VERSION "dbc-export 1 2026.26.6.5"

NS_ :

BS_:

BU_: APP BMS CC CMP CMPD CP DAS DI DIF DIR EPBL EPBR EVSE FC GTW HCML HCMR HVP ICR PCS PCS2 PM PMF PMR PTC SCCM SCM SCS SDCR TAS UMC V2G VC VCBATT VCBATT0 VCBATT1 VCBATT2 VCFRONT VCFRONT1 VCFRONT2 VCLEFT VCRIGHT VCSEAT2L VCSEAT2R VCSEC

BO_ 1000 EPBR_alertMatrix: 8 EPBR
 SG_ EPBR_matrixIndex M : 0|4@1+ (1,0) [0|15] "" Vector__XXX
 SG_ EPBR_a001_WatchdogReset m0 : 4|1@1+ (1,0) [0|1] "" Vector__XXX
 SG_ EPBR_a002_PowerLossReset m0 : 5|1@1+ (1,0) [0|1] "" Vector__XXX
 SG_ EPBR_a003_SWAssertion m0 : 6|1@1+ (1,0) [0|1] "" Vector__XXX
 SG_ EPBR_a005_CANTXError m0 : 8|1@1+ (1,0) [0|1] "" Vector__XXX
 SG_ EPBR_a006_CANTX_cyclicError m0 : 9|1@1+ (1,0) [0|1] "" Vector__XXX
 SG_ EPBR_a012_CPUReset m0 : 15|1@1+ (1,0) [0|1] "" Vector__XXX
 SG_ EPBR_a013_AlertManagerFault m0 : 16|1@1+ (1,0) [0|1] "" Vector__XXX
 SG_ EPBR_a015_NVMMError m0 : 18|1@1+ (1,0) [0|1] "" Vector__XXX
 SG_ EPBR_a016_NVMMRecordError m0 : 19|1@1+ (1,0) [0|1] "" Vector__XXX
 SG_ EPBR_a021_TaskSchedulerError m0 : 24|1@1+ (1,0) [0|1] "" Vector__XXX
 SG_ EPBR_a022_TaskInitError m0 : 25|1@1+ (1,0) [0|1] "" Vector__XXX
 SG_ EPBR_a029_CoreDump m0 : 32|1@1+ (1,0) [0|1] "" Vector__XXX
 SG_ EPBR_a030_ECULogUploadRequest m0 : 33|1@1+ (1,0) [0|1] "" Vector__XXX
 SG_ EPBR_a031_UDSActive m0 : 34|1@1+ (1,0) [0|1] "" Vector__XXX
 SG_ EPBR_a041_HighCPULoad m0 : 44|1@1+ (1,0) [0|1] "" Vector__XXX
 SG_ EPBR_a042_HighStackUsage m0 : 45|1@1+ (1,0) [0|1] "" Vector__XXX
 SG_ EPBR_a043_Task1msError m0 : 46|1@1+ (1,0) [0|1] "" Vector__XXX
 SG_ EPBR_a044_Task10msError m0 : 47|1@1+ (1,0) [0|1] "" Vector__XXX
 SG_ EPBR_a045_Task100msError m0 : 48|1@1+ (1,0) [0|1] "" Vector__XXX
 SG_ EPBR_a046_Task1000msError m0 : 49|1@1+ (1,0) [0|1] "" Vector__XXX
 SG_ EPBR_a057_HVP_MIA m0 : 60|1@1+ (1,0) [0|1] "" Vector__XXX
 SG_ EPBR_a058_inputRHighSyncDebug m0 : 61|1@1+ (1,0) [0|1] "" Vector__XXX
 SG_ EPBR_a059_inputResistanceHigh m0 : 62|1@1+ (1,0) [0|1] "" Vector__XXX
 SG_ EPBR_a060_engineeringBuild m0 : 63|1@1+ (1,0) [0|1] "" Vector__XXX
 SG_ EPBR_a061_XCPConnected m1 : 4|1@1+ (1,0) [0|1] "" Vector__XXX
 SG_ EPBR_a062_XCPWasConnected m1 : 5|1@1+ (1,0) [0|1] "" Vector__XXX
 SG_ EPBR_a063_SwitchFault m1 : 6|1@1+ (1,0) [0|1] "" Vector__XXX
 SG_ EPBR_a064_busSleepReqTimeout m1 : 7|1@1+ (1,0) [0|1] "" Vector__XXX
 SG_ EPBR_a081_APP_MIA m1 : 24|1@1+ (1,0) [0|1] "" Vector__XXX
 SG_ EPBR_a082_VCRIGHT_IPC_MIA m1 : 25|1@1+ (1,0) [0|1] "" Vector__XXX
 SG_ EPBR_a083_VCLEFT_IPC_MIA m1 : 26|1@1+ (1,0) [0|1] "" Vector__XXX
 SG_ EPBR_a084_TPMS_MIA m1 : 27|1@1+ (1,0) [0|1] "" Vector__XXX
 SG_ EPBR_a085_CCCM_MIA m1 : 28|1@1+ (1,0) [0|1] "" Vector__XXX
 SG_ EPBR_a086_VCBATT_MIA m1 : 29|1@1+ (1,0) [0|1] "" Vector__XXX
 SG_ EPBR_a087_DIREL_MIA m1 : 30|1@1+ (1,0) [0|1] "" Vector__XXX
 SG_ EPBR_a088_DIRER_MIA m1 : 31|1@1+ (1,0) [0|1] "" Vector__XXX
 SG_ EPBR_a089_IBST_MIA m1 : 32|1@1+ (1,0) [0|1] "" Vector__XXX
 SG_ EPBR_a090_APS_MIA m1 : 33|1@1+ (1,0) [0|1] "" Vector__XXX
 SG_ EPBR_a091_CMPD_MIA m1 : 34|1@1+ (1,0) [0|1] "" Vector__XXX
 SG_ EPBR_a092_VCSEATD_MIA m1 : 35|1@1+ (1,0) [0|1] "" Vector__XXX
 SG_ EPBR_a093_VCSEATP_MIA m1 : 36|1@1+ (1,0) [0|1] "" Vector__XXX
 SG_ EPBR_a094_EPAS3P_MIA m1 : 37|1@1+ (1,0) [0|1] "" Vector__XXX
 SG_ EPBR_a095_CHG_MIA m1 : 38|1@1+ (1,0) [0|1] "" Vector__XXX
 SG_ EPBR_a096_OCS1P_MIA m1 : 39|1@1+ (1,0) [0|1] "" Vector__XXX
 SG_ EPBR_a097_CMP_MIA m1 : 40|1@1+ (1,0) [0|1] "" Vector__XXX
 SG_ EPBR_a098_DIR_MIA m1 : 41|1@1+ (1,0) [0|1] "" Vector__XXX
 SG_ EPBR_a099_PARK_MIA m1 : 42|1@1+ (1,0) [0|1] "" Vector__XXX
 SG_ EPBR_a100_CANbus_MIA m1 : 43|1@1+ (1,0) [0|1] "" Vector__XXX
 SG_ EPBR_a101_PM_MIA m1 : 44|1@1+ (1,0) [0|1] "" Vector__XXX
 SG_ EPBR_a102_PTC_MIA m1 : 45|1@1+ (1,0) [0|1] "" Vector__XXX
 SG_ EPBR_a103_CP_MIA m1 : 46|1@1+ (1,0) [0|1] "" Vector__XXX
 SG_ EPBR_a104_DAS_MIA m1 : 47|1@1+ (1,0) [0|1] "" Vector__XXX
 SG_ EPBR_a105_TAS_MIA m1 : 48|1@1+ (1,0) [0|1] "" Vector__XXX
 SG_ EPBR_a106_PCS_MIA m1 : 49|1@1+ (1,0) [0|1] "" Vector__XXX
 SG_ EPBR_a107_BMS_MIA m1 : 50|1@1+ (1,0) [0|1] "" Vector__XXX
 SG_ EPBR_a108_DIF_MIA m1 : 51|1@1+ (1,0) [0|1] "" Vector__XXX
 SG_ EPBR_a109_RCM_MIA m1 : 52|1@1+ (1,0) [0|1] "" Vector__XXX
 SG_ EPBR_a110_GTW_MIA m1 : 53|1@1+ (1,0) [0|1] "" Vector__XXX
 SG_ EPBR_a111_EPBR_MIA m1 : 54|1@1+ (1,0) [0|1] "" Vector__XXX
 SG_ EPBR_a112_EPBL_MIA m1 : 55|1@1+ (1,0) [0|1] "" Vector__XXX
 SG_ EPBR_a113_UI_MIA m1 : 56|1@1+ (1,0) [0|1] "" Vector__XXX
 SG_ EPBR_a114_ESP_MIA m1 : 57|1@1+ (1,0) [0|1] "" Vector__XXX
 SG_ EPBR_a115_VCSEC_MIA m1 : 58|1@1+ (1,0) [0|1] "" Vector__XXX
 SG_ EPBR_a116_VCRIGHT_MIA m1 : 59|1@1+ (1,0) [0|1] "" Vector__XXX
 SG_ EPBR_a117_VCLEFT_MIA m1 : 60|1@1+ (1,0) [0|1] "" Vector__XXX
 SG_ EPBR_a118_VCFRONT_MIA m1 : 61|1@1+ (1,0) [0|1] "" Vector__XXX
 SG_ EPBR_a119_SCCM_MIA m1 : 62|1@1+ (1,0) [0|1] "" Vector__XXX
 SG_ EPBR_a120_DI_DRIVE_MIA m1 : 63|1@1+ (1,0) [0|1] "" Vector__XXX
 SG_ EPBR_a121_nDriveFault m2 : 4|1@1+ (1,0) [0|1] "" Vector__XXX
 SG_ EPBR_a122_Oc m2 : 5|1@1+ (1,0) [0|1] "" Vector__XXX
 SG_ EPBR_a123_Uc m2 : 6|1@1+ (1,0) [0|1] "" Vector__XXX
 SG_ EPBR_a124_calOutOfBounds m2 : 7|1@1+ (1,0) [0|1] "" Vector__XXX
 SG_ EPBR_a125_IdleVMismatch m2 : 8|1@1+ (1,0) [0|1] "" Vector__XXX
 SG_ EPBR_a126_MotorNVoltLow m2 : 9|1@1+ (1,0) [0|1] "" Vector__XXX
 SG_ EPBR_a127_MotorNVoltHigh m2 : 10|1@1+ (1,0) [0|1] "" Vector__XXX
 SG_ EPBR_a128_MotorPVoltHigh m2 : 11|1@1+ (1,0) [0|1] "" Vector__XXX
 SG_ EPBR_a129_ICR_MIA m2 : 12|1@1+ (1,0) [0|1] "" Vector__XXX
 SG_ EPBR_a130_BB_MIA m2 : 13|1@1+ (1,0) [0|1] "" Vector__XXX
 SG_ EPBR_a131_RCU_MIA m2 : 14|1@1+ (1,0) [0|1] "" Vector__XXX
 SG_ EPBR_a132_VCBATT1_MIA m2 : 15|1@1+ (1,0) [0|1] "" Vector__XXX
 SG_ EPBR_a133_VCBATT2_MIA m2 : 16|1@1+ (1,0) [0|1] "" Vector__XXX
 SG_ EPBR_a134_NvOv m2 : 17|1@1+ (1,0) [0|1] "" Vector__XXX
 SG_ EPBR_a135_NvUv m2 : 18|1@1+ (1,0) [0|1] "" Vector__XXX
 SG_ EPBR_a136_PvOv m2 : 19|1@1+ (1,0) [0|1] "" Vector__XXX
 SG_ EPBR_a137_PvUv m2 : 20|1@1+ (1,0) [0|1] "" Vector__XXX
 SG_ EPBR_a138_NvmDualFailure m2 : 21|1@1+ (1,0) [0|1] "" Vector__XXX
 SG_ EPBR_a139_NvmRedundancyLoss m2 : 22|1@1+ (1,0) [0|1] "" Vector__XXX
 SG_ EPBR_a140_NvmSlowWrite m2 : 23|1@1+ (1,0) [0|1] "" Vector__XXX
 SG_ EPBR_a141_invalidState m2 : 24|1@1+ (1,0) [0|1] "" Vector__XXX
 SG_ EPBR_a170_12vOv m2 : 53|1@1+ (1,0) [0|1] "" Vector__XXX
 SG_ EPBR_a171_12vUv m2 : 54|1@1+ (1,0) [0|1] "" Vector__XXX
 SG_ EPBR_a172_SPI_MIA m2 : 55|1@1+ (1,0) [0|1] "" Vector__XXX
 SG_ EPBR_a173_hiCurrentMissing m2 : 56|1@1+ (1,0) [0|1] "" Vector__XXX
 SG_ EPBR_a174_csmReleaseFailed m2 : 57|1@1+ (1,0) [0|1] "" Vector__XXX
 SG_ EPBR_a175_csmReleaseRetry m2 : 58|1@1+ (1,0) [0|1] "" Vector__XXX
 SG_ EPBR_a176_csmApplyFailed m2 : 59|1@1+ (1,0) [0|1] "" Vector__XXX
 SG_ EPBR_a177_csmApplyRetry m2 : 60|1@1+ (1,0) [0|1] "" Vector__XXX
 SG_ EPBR_a178_caliperStateUnknown m2 : 61|1@1+ (1,0) [0|1] "" Vector__XXX
 SG_ EPBR_a179_epbProblem m2 : 62|1@1+ (1,0) [0|1] "" Vector__XXX
 SG_ EPBR_a180_dynamicActive m2 : 63|1@1+ (1,0) [0|1] "" Vector__XXX
 SG_ EPBR_a181_TooSteepGradeToPark m3 : 4|1@1+ (1,0) [0|1] "" Vector__XXX
 SG_ EPBR_a182_OneEPBAppliedUnsecEnv m3 : 5|1@1+ (1,0) [0|1] "" Vector__XXX
 SG_ EPBR_a183_cdpNotAvailable m3 : 6|1@1+ (1,0) [0|1] "" Vector__XXX
 SG_ EPBR_a184_dynamicParkAbort m3 : 7|1@1+ (1,0) [0|1] "" Vector__XXX
 SG_ EPBR_a185_summonAborted m3 : 8|1@1+ (1,0) [0|1] "" Vector__XXX
 SG_ EPBR_a186_externalParkAbort m3 : 9|1@1+ (1,0) [0|1] "" Vector__XXX
 SG_ EPBR_a187_cdpDynamic m3 : 10|1@1+ (1,0) [0|1] "" Vector__XXX
 SG_ EPBR_a188_epbDynamic m3 : 11|1@1+ (1,0) [0|1] "" Vector__XXX
 SG_ EPBR_a189_epbDynamicParkCanceled m3 : 12|1@1+ (1,0) [0|1] "" Vector__XXX
 SG_ EPBR_a190_csmApplyDegraded m3 : 13|1@1+ (1,0) [0|1] "" Vector__XXX
 SG_ EPBR_a191_csmReleaseDegraded m3 : 14|1@1+ (1,0) [0|1] "" Vector__XXX
 SG_ EPBR_a195_parkForDriverIsLeaving m3 : 18|1@1+ (1,0) [0|1] "" Vector__XXX
 SG_ EPBR_a196_freeRollModeActive m3 : 19|1@1+ (1,0) [0|1] "" Vector__XXX
 SG_ EPBR_a197_freeRollModeAtSpeed m3 : 20|1@1+ (1,0) [0|1] "" Vector__XXX
 SG_ EPBR_a198_holdClampComplete m3 : 21|1@1+ (1,0) [0|1] "" Vector__XXX
 SG_ EPBR_a200_PmUnparkNotAllowed m3 : 23|1@1+ (1,0) [0|1] "" Vector__XXX
 SG_ EPBR_a202_remoteEpbConfigIncompa m3 : 25|1@1+ (1,0) [0|1] "" Vector__XXX
 SG_ EPBR_a203_hwBrakeTypeMismatch m3 : 26|1@1+ (1,0) [0|1] "" Vector__XXX
 SG_ EPBR_a210_parkForDriverIsLeaving m3 : 33|1@1+ (1,0) [0|1] "" Vector__XXX
 SG_ EPBR_a216_SPI_MIA_debugData1 m3 : 39|1@1+ (1,0) [0|1] "" Vector__XXX
 SG_ EPBR_a217_SPI_MIA_debugData2 m3 : 40|1@1+ (1,0) [0|1] "" Vector__XXX
 SG_ EPBR_a225_epbActiveDecel m3 : 48|1@1+ (1,0) [0|1] "" Vector__XXX
 SG_ EPBR_a241_diOutputLocked m4 : 4|1@1+ (1,0) [0|1] "" Vector__XXX
 SG_ EPBR_a242_hvOutputLocked m4 : 5|1@1+ (1,0) [0|1] "" Vector__XXX
 SG_ EPBR_a243_bdwUnavailable m4 : 6|1@1+ (1,0) [0|1] "" Vector__XXX
 SG_ EPBR_a244_WinchModeActive m4 : 7|1@1+ (1,0) [0|1] "" Vector__XXX
 SG_ EPBR_a245_serviceModeActive m4 : 8|1@1+ (1,0) [0|1] "" Vector__XXX
 SG_ EPBR_a246_idleFaultApply m4 : 9|1@1+ (1,0) [0|1] "" Vector__XXX
 SG_ EPBR_a247_csmDynamicApplyRetry m4 : 10|1@1+ (1,0) [0|1] "" Vector__XXX
 SG_ EPBR_a248_csmDynamicApplyFailed m4 : 11|1@1+ (1,0) [0|1] "" Vector__XXX
 SG_ EPBR_a249_idleFaultRelease m4 : 12|1@1+ (1,0) [0|1] "" Vector__XXX
 SG_ EPBR_a250_WinchModeCanceled m4 : 13|1@1+ (1,0) [0|1] "" Vector__XXX
 SG_ EPBR_a251_currentVarianceHigh m4 : 14|1@1+ (1,0) [0|1] "" Vector__XXX
 SG_ EPBR_a252_winchModePending m4 : 15|1@1+ (1,0) [0|1] "" Vector__XXX
 SG_ EPBR_a253_esmReleaseBlocked m4 : 16|1@1+ (1,0) [0|1] "" Vector__XXX
 SG_ EPBR_a254_showStalkParkButtonFau m4 : 17|1@1+ (1,0) [0|1] "" Vector__XXX
 SG_ EPBR_a256_epbSystemApply m4 : 19|1@1+ (1,0) [0|1] "" Vector__XXX
 SG_ EPBR_a261_winchModeWithoutSteeri m4 : 24|1@1+ (1,0) [0|1] "" Vector__XXX
 SG_ EPBR_a262_cannotPrepareWinchMode m4 : 25|1@1+ (1,0) [0|1] "" Vector__XXX
 SG_ EPBR_a263_epbRecoveryPark m4 : 26|1@1+ (1,0) [0|1] "" Vector__XXX
 SG_ EPBR_a264_winchModeDeactivated m4 : 27|1@1+ (1,0) [0|1] "" Vector__XXX
 SG_ EPBR_a272_vhclPwrStateMsmtch m4 : 35|1@1+ (1,0) [0|1] "" Vector__XXX
 SG_ EPBR_a300_leftRightConfusion m4 : 63|1@1+ (1,0) [0|1] "" Vector__XXX
 SG_ EPBR_a301_oocSpeedViolation m5 : 4|1@1+ (1,0) [0|1] "" Vector__XXX
 SG_ EPBR_a302_csmLongRelease m5 : 5|1@1+ (1,0) [0|1] "" Vector__XXX
 SG_ EPBR_a303_clampingOccuredEarly m5 : 6|1@1+ (1,0) [0|1] "" Vector__XXX
 SG_ EPBR_a304_rearSeatControllerEFus m5 : 7|1@1+ (1,0) [0|1] "" Vector__XXX
 SG_ EPBR_a305_premiumAmpEFuseTrip m5 : 8|1@1+ (1,0) [0|1] "" Vector__XXX
 SG_ EPBR_a330_parkForApIsLeaving m5 : 33|1@1+ (1,0) [0|1] "" Vector__XXX
 SG_ EPBR_a350_ensOutOfRange m5 : 53|1@1+ (1,0) [0|1] "" Vector__XXX
 SG_ EPBR_a352_audioCurrentSpikeData m5 : 55|1@1+ (1,0) [0|1] "" Vector__XXX
 SG_ EPBR_a353_missingSpeedUnableToPa m5 : 56|1@1+ (1,0) [0|1] "" Vector__XXX
 SG_ EPBR_a354_parkedForLowBrakeFluid m5 : 57|1@1+ (1,0) [0|1] "" Vector__XXX
 SG_ EPBR_a355_brakeHwAndEpbHwMismatc m5 : 58|1@1+ (1,0) [0|1] "" Vector__XXX
 SG_ EPBR_a356_parkingForStationaryDe m5 : 59|1@1+ (1,0) [0|1] "" Vector__XXX
 SG_ EPBR_a357_brakesTooHotForSlope m5 : 60|1@1+ (1,0) [0|1] "" Vector__XXX
 SG_ EPBR_a358_brakesTooHotForSlopeWi m5 : 61|1@1+ (1,0) [0|1] "" Vector__XXX
 SG_ EPBR_a359_seat2RControllerTrip m5 : 62|1@1+ (1,0) [0|1] "" Vector__XXX
 SG_ EPBR_a360_ibstBrakeSwitchInvalid m5 : 63|1@1+ (1,0) [0|1] "" Vector__XXX
 SG_ EPBR_a361_espBrakeSwitchInvalid m6 : 4|1@1+ (1,0) [0|1] "" Vector__XXX
 SG_ EPBR_a362_ibstPressedEspNotPress m6 : 5|1@1+ (1,0) [0|1] "" Vector__XXX
 SG_ EPBR_a363_ibstNotPressedEspPress m6 : 6|1@1+ (1,0) [0|1] "" Vector__XXX
 SG_ EPBR_a364_espMasterCylCompOverTh m6 : 7|1@1+ (1,0) [0|1] "" Vector__XXX
 SG_ EPBR_a365_TooSteepToParkWithTrai m6 : 8|1@1+ (1,0) [0|1] "" Vector__XXX
 SG_ EPBR_a366_TooSteepToParkWithTrai m6 : 9|1@1+ (1,0) [0|1] "" Vector__XXX
 SG_ EPBR_a370_imposterDetected m6 : 13|1@1+ (1,0) [0|1] "" Vector__XXX

BO_ 2024 EPBR_info: 8 EPBR
 SG_ EPBR_infoIndex M : 0|8@1+ (1,0) [0|255] "" Vector__XXX
 SG_ EPBR_infoBuildType m10 : 8|3@1+ (1,0) [0|7] "" Vector__XXX
 SG_ EPBR_infoBuildConfigId m10 : 16|16@1+ (1,0) [0|65535] "" Vector__XXX
 SG_ EPBR_infoHardwareId m10 : 32|16@1+ (1,0) [0|65535] "" Vector__XXX
 SG_ EPBR_infoComponentId m10 : 48|16@1+ (1,0) [0|65535] "" Vector__XXX
 SG_ EPBR_infoPcbaId m11 : 8|8@1+ (1,0) [0|255] "" Vector__XXX
 SG_ EPBR_infoAssemblyId m11 : 16|8@1+ (1,0) [0|254] "" Vector__XXX
 SG_ EPBR_infoUsageId m11 : 24|16@1+ (1,0) [0|65535] "" Vector__XXX
 SG_ EPBR_infoSubUsageId m11 : 40|16@1+ (1,0) [0|65535] "" Vector__XXX
 SG_ EPBR_infoAppCrc m13 : 8|32@1+ (1,0) [0|4294967295] "" Vector__XXX
 SG_ EPBR_infoAppGitHash m17 : 8|56@1+ (1,0) [0|7.20575940379e+16] "" Vector__XXX
 SG_ EPBR_infoBootGitHash m18 : 8|56@1+ (1,0) [0|7.20575940379e+16] "" Vector__XXX
 SG_ EPBR_infoPlatformType m19 : 8|8@1+ (1,0) [0|255] "" Vector__XXX
 SG_ EPBR_infoBootUdsProtoVersion m20 : 8|16@1+ (1,0) [0|65535] "" Vector__XXX
 SG_ EPBR_infoBootCrc m20 : 24|32@1+ (1,0) [0|4294967295] "" Vector__XXX

BO_ 552 EPBR_internalStatus: 8 EPBR
 SG_ EPBR_unitStatus : 0|5@1+ (1,0) [0|31] "" Vector__XXX
 SG_ EPBR_unitFaultStatus : 5|2@1+ (1,0) [0|3] "" Vector__XXX
 SG_ EPBR_summonState : 8|3@1+ (1,0) [0|7] "" Vector__XXX
 SG_ EPBR_disconnected : 11|1@1+ (1,0) [0|1] "" Vector__XXX
 SG_ EPBR_pistonTouchingRotor : 12|1@1+ (1,0) [0|1] "" Vector__XXX
 SG_ EPBR_csmFaultReason : 13|5@1+ (1,0) [0|31] "" Vector__XXX
 SG_ EPBR_esmOperationTrigger : 18|6@1+ (1,0) [0|63] "" Vector__XXX
 SG_ EPBR_summonFaultReason : 24|5@1+ (1,0) [0|31] "" Vector__XXX
 SG_ EPBR_localServiceModeActive : 29|1@1+ (1,0) [0|1] "" Vector__XXX
 SG_ EPBR_localCdpState : 30|2@1+ (1,0) [0|3] "" Vector__XXX
 SG_ EPBR_chimeRequestLocal : 33|3@1+ (1,0) [0|7] "" Vector__XXX
 SG_ EPBR_telltaleLocal : 39|3@1+ (1,0) [0|6] "" Vector__XXX
 SG_ EPBR_driverIsLeavingLocal : 42|1@1+ (1,0) [0|1] "" Vector__XXX
 SG_ EPBR_driverIsLeavingAnySpeedLoca : 43|1@1+ (1,0) [0|1] "" Vector__XXX
 SG_ EPBR_internalCDPRequest : 44|1@1+ (1,0) [0|1] "" Vector__XXX
 SG_ EPBR_esmSpeedClass : 45|3@1+ (1,0) [0|7] "" Vector__XXX
 SG_ EPBR_learnedEpbConfig : 48|4@1+ (1,0) [0|15] "" Vector__XXX
 SG_ EPBR_internalStatusCounter : 52|4@1+ (1,0) [0|15] "" Vector__XXX
 SG_ EPBR_internalStatusChecksum : 56|8@1+ (1,0) [0|255] "" Vector__XXX

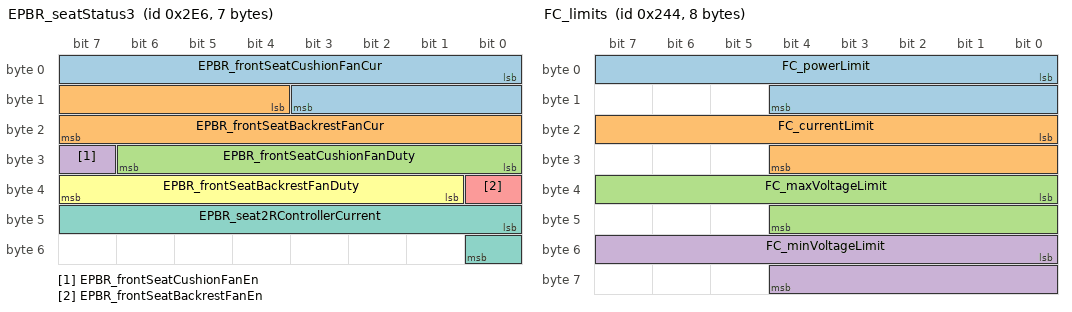
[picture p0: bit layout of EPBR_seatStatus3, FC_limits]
BO_ 742 EPBR_seatStatus3: 7 EPBR
 SG_ EPBR_frontSeatCushionFanCur : 0|12@1+ (0.01,0) [0|40.95] "A" Vector__XXX
 SG_ EPBR_frontSeatBackrestFanCur : 12|12@1+ (0.01,0) [0|40.95] "A" Vector__XXX
 SG_ EPBR_frontSeatCushionFanDuty : 24|7@1+ (1,0) [0|100] "%" Vector__XXX
 SG_ EPBR_frontSeatCushionFanEn : 31|1@1+ (1,0) [0|1] "" Vector__XXX
 SG_ EPBR_frontSeatBackrestFanEn : 32|1@1+ (1,0) [0|1] "" Vector__XXX
 SG_ EPBR_frontSeatBackrestFanDuty : 33|7@1+ (1,0) [0|100] "%" Vector__XXX
 SG_ EPBR_seat2RControllerCurrent : 40|9@1+ (0.2,0) [0|102] "A" Vector__XXX

BO_ 744 EPBR_status: 8 EPBR
 SG_ EPBR_systemStatus : 0|4@1+ (1,0) [0|15] "" Vector__XXX
 SG_ EPBR_freeRollModeStatus : 4|2@1+ (1,0) [0|3] "" Vector__XXX
 SG_ EPBR_driverIsLeaving : 6|1@1+ (1,0) [0|1] "" Vector__XXX
 SG_ EPBR_driverIsLeavingAnySpeed : 7|1@1+ (1,0) [0|1] "" Vector__XXX
 SG_ EPBR_systemCdpAvailable : 8|1@1+ (1,0) [0|1] "" Vector__XXX
 SG_ EPBR_chimeRequest : 9|3@1+ (1,0) [0|7] "" Vector__XXX
 SG_ EPBR_telltale : 12|3@1+ (1,0) [0|6] "" Vector__XXX
 SG_ EPBR_audioCurrentSpikeDetected : 15|1@1+ (1,0) [0|1] "" Vector__XXX
 SG_ EPBR_redundantBrakingEnabled : 16|1@1+ (1,0) [0|1] "" Vector__XXX
 SG_ EPBR_summonEnabled : 17|1@1+ (1,0) [0|1] "" Vector__XXX
 SG_ EPBR_brakeLight : 18|1@1+ (1,0) [0|1] "" Vector__XXX
 SG_ EPBR_epbConfigMismatch : 19|1@1+ (1,0) [0|1] "" Vector__XXX
 SG_ EPBR_brakeConfirmedPressed : 20|1@1+ (1,0) [0|1] "" Vector__XXX
 SG_ EPBR_requestUserConfirmation : 21|1@1+ (1,0) [0|1] "" Vector__XXX
 SG_ EPBR_uiWinchModeMiscBlocking : 22|1@1+ (1,0) [0|1] "" Vector__XXX
 SG_ EPBR_winchModeActive : 23|1@1+ (1,0) [0|1] "" Vector__XXX
 SG_ EPBR_updateMode : 24|1@1+ (1,0) [0|1] "" Vector__XXX
 SG_ EPBR_winchModePermissive : 25|1@1+ (1,0) [0|1] "" Vector__XXX
 SG_ EPBR_winchModePending : 26|1@1+ (1,0) [0|1] "" Vector__XXX
 SG_ EPBR_cdpRequest : 27|1@1+ (1,0) [0|1] "" Vector__XXX
 SG_ EPBR_uiParkAvailable : 28|2@1+ (1,0) [0|3] "" Vector__XXX
 SG_ EPBR_brakeDiscWipeRequest : 30|2@1+ (1,0) [0|2] "" Vector__XXX
 SG_ EPBR_showUiGearShifter : 32|1@1+ (1,0) [0|1] "" Vector__XXX
 SG_ EPBR_uiWinchModeLvStatus : 33|2@1+ (1,0) [0|3] "" Vector__XXX
 SG_ EPBR_contactorCycleNotNeededForW : 35|1@1+ (1,0) [0|1] "" Vector__XXX
 SG_ EPBR_autonomyBehavior : 43|2@1+ (1,0) [0|3] "" Vector__XXX
 SG_ EPBR_showStalkFaultedOnUi : 45|1@1+ (1,0) [0|1] "" Vector__XXX
 SG_ EPBR_espPowerRequest : 46|1@1+ (1,0) [0|1] "" Vector__XXX
 SG_ EPBR_okToPark : 47|1@1+ (1,0) [0|1] "" Vector__XXX
 SG_ EPBR_hornRequest : 48|1@1+ (1,0) [0|1] "" Vector__XXX
 SG_ EPBR_winchModeAvailable : 49|1@1+ (1,0) [0|1] "" Vector__XXX
 SG_ EPBR_bothDisconnected : 50|1@1+ (1,0) [0|1] "" Vector__XXX
 SG_ EPBR_blockDrive : 51|1@1+ (1,0) [0|1] "" Vector__XXX
 SG_ EPBR_statusCounter : 52|4@1+ (1,0) [0|15] "" Vector__XXX
 SG_ EPBR_statusChecksum : 56|8@1+ (1,0) [0|255] "" Vector__XXX

BO_ 1662 EVSE_isoTpToVeh: 8 EVSE
 SG_ EVSE_isoTpToVehData : 0|64@1+ (1,0) [0|1.84467440737e+19] "" Vector__XXX

BO_ 1322 FC_alertLog: 8 FC
 SG_ FC_alertID M : 0|15@1+ (1,0) [0|32767] "" Vector__XXX
 SG_ FC_alertType : 15|1@1+ (1,0) [0|1] "" Vector__XXX
 SG_ FC_a130_CA_flybackSwOvType m130 : 16|1@1+ (1,0) [0|1] "" Vector__XXX
 SG_ FC_a146_CA_flybackOnTime m146 : 16|16@1+ (0.0007629511,0) [0|50.0000003385] "uS" Vector__XXX
 SG_ FC_a146_CA_flybackV m146 : 32|16@1+ (0.0128332730383,0) [0|841.028548565] "V" Vector__XXX
 SG_ FC_a146_CA_flybackTargetV m146 : 48|16@1+ (0.0128332730383,0) [0|841.028548565] "V" Vector__XXX
 SG_ FC_a159_CA_wdtTaskList1 m159 : 16|16@1+ (1,0) [0|65535] "" Vector__XXX
 SG_ FC_a159_CA_wdtTaskList2 m159 : 32|16@1+ (1,0) [0|65535] "" Vector__XXX

BO_ 895 FC_alertMatrix3: 8 FC
 SG_ FC_a129_CA_flyback_HW_OC : 0|1@1+ (1,0) [0|1] "" Vector__XXX
 SG_ FC_a130_CA_flyback_SW_OV : 1|1@1+ (1,0) [0|1] "" Vector__XXX
 SG_ FC_a131_CA_flyback_HW_OV : 2|1@1+ (1,0) [0|1] "" Vector__XXX
 SG_ FC_a132_CA_bmsMia : 3|1@1+ (1,0) [0|1] "" Vector__XXX
 SG_ FC_a133_CA_evseMia : 4|1@1+ (1,0) [0|1] "" Vector__XXX
 SG_ FC_a134_CA_vehTxBufOvf : 5|1@1+ (1,0) [0|1] "" Vector__XXX
 SG_ FC_a135_CA_vehRxBufOvf : 6|1@1+ (1,0) [0|1] "" Vector__XXX
 SG_ FC_a136_CA_evseTxBufOvf : 7|1@1+ (1,0) [0|1] "" Vector__XXX
 SG_ FC_a137_CA_evseRxBufOvf : 8|1@1+ (1,0) [0|1] "" Vector__XXX
 SG_ FC_a138_CA_hwProxTrip : 9|1@1+ (1,0) [0|1] "" Vector__XXX
 SG_ FC_a139_CA_ss2NotLow : 10|1@1+ (1,0) [0|1] "" Vector__XXX
 SG_ FC_a140_CA_bmsIncompatible : 11|1@1+ (1,0) [0|1] "" Vector__XXX
 SG_ FC_a141_CA_vehConn_OT : 12|1@1+ (1,0) [0|1] "" Vector__XXX
 SG_ FC_a142_CA_evseConn_OT : 13|1@1+ (1,0) [0|1] "" Vector__XXX
 SG_ FC_a143_CA_pcb_OT : 14|1@1+ (1,0) [0|1] "" Vector__XXX
 SG_ FC_a144_CA_flybackUnstable : 15|1@1+ (1,0) [0|1] "" Vector__XXX
 SG_ FC_a145_CA_flybackDataStale : 16|1@1+ (1,0) [0|1] "" Vector__XXX
 SG_ FC_a146_CA_flybackBusLoadHi : 17|1@1+ (1,0) [0|1] "" Vector__XXX
 SG_ FC_a147_CA_vehConn_UT : 18|1@1+ (1,0) [0|1] "" Vector__XXX
 SG_ FC_a148_CA_evseConn_UT : 19|1@1+ (1,0) [0|1] "" Vector__XXX
 SG_ FC_a149_CA_pcb_UT : 20|1@1+ (1,0) [0|1] "" Vector__XXX
 SG_ FC_a150_CA_vehToEvseDeltaHi : 21|1@1+ (1,0) [0|1] "" Vector__XXX
 SG_ FC_a151_CA_vehToEvseDeltaLo : 22|1@1+ (1,0) [0|1] "" Vector__XXX
 SG_ FC_a152_CA_vehToPcbDeltaHi : 23|1@1+ (1,0) [0|1] "" Vector__XXX
 SG_ FC_a153_CA_evseToPcbDeltaHi : 24|1@1+ (1,0) [0|1] "" Vector__XXX
 SG_ FC_a154_CA_vehToPcbDeltaLo : 25|1@1+ (1,0) [0|1] "" Vector__XXX
 SG_ FC_a155_CA_evseToPcbDeltaLo : 26|1@1+ (1,0) [0|1] "" Vector__XXX
 SG_ FC_a156_CA_flybackRunTimeout : 27|1@1+ (1,0) [0|1] "" Vector__XXX
 SG_ FC_a157_CA_unused : 28|1@1+ (1,0) [0|1] "" Vector__XXX
 SG_ FC_a158_CA_evseOverCurrent : 29|1@1+ (1,0) [0|1] "" Vector__XXX
 SG_ FC_a159_CA_wdtExpired : 30|1@1+ (1,0) [0|1] "" Vector__XXX
 SG_ FC_a160_CA_ss2Deasserted : 31|1@1+ (1,0) [0|1] "" Vector__XXX
 SG_ FC_a161_CA_vehTempHiFoldBk : 32|1@1+ (1,0) [0|1] "" Vector__XXX
 SG_ FC_a162_CA_evseTempHiFoldBk : 33|1@1+ (1,0) [0|1] "" Vector__XXX
 SG_ FC_a163_CA_pcbTempHiFoldBk : 34|1@1+ (1,0) [0|1] "" Vector__XXX
 SG_ FC_a164_CA_proxDisconnected : 35|1@1+ (1,0) [0|1] "" Vector__XXX
 SG_ FC_a165_CA_evseConnUnlocked : 36|1@1+ (1,0) [0|1] "" Vector__XXX
 SG_ FC_a166_CA_vehConnUnlocked : 37|1@1+ (1,0) [0|1] "" Vector__XXX
 SG_ FC_a167_CA_isoVoltageLow : 38|1@1+ (1,0) [0|1] "" Vector__XXX
 SG_ FC_a168_CA_proxTimeout : 39|1@1+ (1,0) [0|1] "" Vector__XXX
 SG_ FC_a169_CA_pilotAcceptTimeout : 40|1@1+ (1,0) [0|1] "" Vector__XXX
 SG_ FC_a170_CA_vehDataTimeout : 41|1@1+ (1,0) [0|1] "" Vector__XXX
 SG_ FC_a171_CA_vehConLockTimeout : 42|1@1+ (1,0) [0|1] "" Vector__XXX
 SG_ FC_a172_CA_ss2LowTimeout : 43|1@1+ (1,0) [0|1] "" Vector__XXX
 SG_ FC_a173_CA_evseDataTimeout : 44|1@1+ (1,0) [0|1] "" Vector__XXX
 SG_ FC_a174_CA_vehReadyTimeout : 45|1@1+ (1,0) [0|1] "" Vector__XXX
 SG_ FC_a175_CA_evseIsoTestTimeout : 46|1@1+ (1,0) [0|1] "" Vector__XXX
 SG_ FC_a176_CA_chargingBusTimeout : 47|1@1+ (1,0) [0|1] "" Vector__XXX
 SG_ FC_a177_CA_bmsCtrCloseTimeout : 48|1@1+ (1,0) [0|1] "" Vector__XXX
 SG_ FC_a178_CA_evseStartTimeout : 49|1@1+ (1,0) [0|1] "" Vector__XXX
 SG_ FC_a179_CA_startupProblem : 50|1@1+ (1,0) [0|1] "" Vector__XXX
 SG_ FC_a180_CA_chargingProblem : 51|1@1+ (1,0) [0|1] "" Vector__XXX
 SG_ FC_a181_CA_vRegBrownout : 52|1@1+ (1,0) [0|1] "" Vector__XXX
 SG_ FC_a182_CA_evseChrMalfunc : 53|1@1+ (1,0) [0|1] "" Vector__XXX
 SG_ FC_a183_CA_evseBatIncompat : 54|1@1+ (1,0) [0|1] "" Vector__XXX
 SG_ FC_a184_CA_evseBatMalfunc : 55|1@1+ (1,0) [0|1] "" Vector__XXX
 SG_ FC_a185_CA_vehReadyDeasserted : 56|1@1+ (1,0) [0|1] "" Vector__XXX
 SG_ FC_a186_CA_fcContOpenTimeout : 57|1@1+ (1,0) [0|1] "" Vector__XXX
 SG_ FC_a187_CA_evseConLockTimeout : 58|1@1+ (1,0) [0|1] "" Vector__XXX

BO_ 927 FC_alertMatrix4: 8 FC
 SG_ FC_a193_FCAlertPlaceholder : 0|1@1+ (1,0) [0|1] "" Vector__XXX

BO_ 958 FC_alertMatrix5: 8 FC
 SG_ FC_a257_GB_bmsMia : 0|1@1+ (1,0) [0|1] "" Vector__XXX
 SG_ FC_a258_GB_evseMia : 1|1@1+ (1,0) [0|1] "" Vector__XXX
 SG_ FC_a259_GB_vehTxBufOvf : 2|1@1+ (1,0) [0|1] "" Vector__XXX
 SG_ FC_a260_GB_vehRxBufOvf : 3|1@1+ (1,0) [0|1] "" Vector__XXX
 SG_ FC_a261_GB_evseTxBufOvf : 4|1@1+ (1,0) [0|1] "" Vector__XXX
 SG_ FC_a262_GB_evseRxBufOvf : 5|1@1+ (1,0) [0|1] "" Vector__XXX
 SG_ FC_a263_GB_hwProxTrip : 6|1@1+ (1,0) [0|1] "" Vector__XXX
 SG_ FC_a264_GB_timeoutCHM : 7|1@1+ (1,0) [0|1] "" Vector__XXX
 SG_ FC_a265_GB_bmsIncompatible : 8|1@1+ (1,0) [0|1] "" Vector__XXX
 SG_ FC_a266_GB_negPin_OT : 9|1@1+ (1,0) [0|1] "" Vector__XXX
 SG_ FC_a267_GB_posPin_OT : 10|1@1+ (1,0) [0|1] "" Vector__XXX
 SG_ FC_a268_GB_pcb_OT : 11|1@1+ (1,0) [0|1] "" Vector__XXX
 SG_ FC_a269_GB_timeoutCRM : 12|1@1+ (1,0) [0|1] "" Vector__XXX
 SG_ FC_a270_GB_timeoutCML : 13|1@1+ (1,0) [0|1] "" Vector__XXX
 SG_ FC_a271_GB_timeoutCRO : 14|1@1+ (1,0) [0|1] "" Vector__XXX
 SG_ FC_a272_GB_negToPosDeltaHi : 15|1@1+ (1,0) [0|1] "" Vector__XXX
 SG_ FC_a273_GB_negToPosDeltaLo : 16|1@1+ (1,0) [0|1] "" Vector__XXX
 SG_ FC_a274_GB_negToPcbDeltaHi : 17|1@1+ (1,0) [0|1] "" Vector__XXX
 SG_ FC_a275_GB_posToPcbDeltaHi : 18|1@1+ (1,0) [0|1] "" Vector__XXX
 SG_ FC_a276_GB_negToPcbDeltaLo : 19|1@1+ (1,0) [0|1] "" Vector__XXX
 SG_ FC_a277_GB_posToPcbDeltaLo : 20|1@1+ (1,0) [0|1] "" Vector__XXX
 SG_ FC_a278_GB_timeoutCCS : 21|1@1+ (1,0) [0|1] "" Vector__XXX
 SG_ FC_a279_GB_evseOverCurrent : 22|1@1+ (1,0) [0|1] "" Vector__XXX
 SG_ FC_a280_GB_retryLimitExceeded : 23|1@1+ (1,0) [0|1] "" Vector__XXX
 SG_ FC_a281_GB_evseOutOfService : 24|1@1+ (1,0) [0|1] "" Vector__XXX
 SG_ FC_a282_GB_negTempHiFoldBk : 25|1@1+ (1,0) [0|1] "" Vector__XXX
 SG_ FC_a283_GB_posTempHiFoldBk : 26|1@1+ (1,0) [0|1] "" Vector__XXX
 SG_ FC_a284_GB_pcbTempHiFoldBk : 27|1@1+ (1,0) [0|1] "" Vector__XXX
 SG_ FC_a285_GB_proxDisconnected : 28|1@1+ (1,0) [0|1] "" Vector__XXX
 SG_ FC_a286_GB_evseConnUnlocked : 29|1@1+ (1,0) [0|1] "" Vector__XXX
 SG_ FC_a287_GB_vehConnUnlocked : 30|1@1+ (1,0) [0|1] "" Vector__XXX
 SG_ FC_a288_GB_evseAbnormalStopReq : 31|1@1+ (1,0) [0|1] "" Vector__XXX
 SG_ FC_a289_GB_proxTimeout : 32|1@1+ (1,0) [0|1] "" Vector__XXX
 SG_ FC_a290_GB_pilotAcceptTimeout : 33|1@1+ (1,0) [0|1] "" Vector__XXX
 SG_ FC_a291_GB_vehDataTimeout : 34|1@1+ (1,0) [0|1] "" Vector__XXX
 SG_ FC_a292_GB_vehConLockTimeout : 35|1@1+ (1,0) [0|1] "" Vector__XXX
 SG_ FC_a293_GB_proxRationality : 36|1@1+ (1,0) [0|1] "" Vector__XXX
 SG_ FC_a294_GB_unused : 37|1@1+ (1,0) [0|1] "" Vector__XXX
 SG_ FC_a295_GB_pilotRationality : 38|1@1+ (1,0) [0|1] "" Vector__XXX
 SG_ FC_a296_GB_invalidPilotTransitio : 39|1@1+ (1,0) [0|1] "" Vector__XXX
 SG_ FC_a297_GB_unused : 40|1@1+ (1,0) [0|1] "" Vector__XXX
 SG_ FC_a298_GB_bmsCtrCloseTimeout : 41|1@1+ (1,0) [0|1] "" Vector__XXX
 SG_ FC_a299_GB_evseReadyTimeout : 42|1@1+ (1,0) [0|1] "" Vector__XXX
 SG_ FC_a300_GB_unused : 43|1@1+ (1,0) [0|1] "" Vector__XXX
 SG_ FC_a301_GB_unused : 44|1@1+ (1,0) [0|1] "" Vector__XXX
 SG_ FC_a302_GB_unused : 45|1@1+ (1,0) [0|1] "" Vector__XXX
 SG_ FC_a303_GB_negRecogTimeout : 46|1@1+ (1,0) [0|1] "" Vector__XXX
 SG_ FC_a304_GB_unused : 47|1@1+ (1,0) [0|1] "" Vector__XXX
 SG_ FC_a305_GB_posRecogTimeout : 48|1@1+ (1,0) [0|1] "" Vector__XXX
 SG_ FC_a306_GB_vehReadyDeasserted : 49|1@1+ (1,0) [0|1] "" Vector__XXX
 SG_ FC_a307_GB_fcContOpenTimeout : 50|1@1+ (1,0) [0|1] "" Vector__XXX
 SG_ FC_a308_GB_evseConLockTimeout : 51|1@1+ (1,0) [0|1] "" Vector__XXX
 SG_ FC_a309_GB_unused : 52|1@1+ (1,0) [0|1] "" Vector__XXX
 SG_ FC_a310_GB_unused : 53|1@1+ (1,0) [0|1] "" Vector__XXX
 SG_ FC_a311_GB_battParamsTimeout : 54|1@1+ (1,0) [0|1] "" Vector__XXX
 SG_ FC_a312_GB_evseLimitsTimeout : 55|1@1+ (1,0) [0|1] "" Vector__XXX
 SG_ FC_a313_GB_inputVoltageRailOv : 56|1@1+ (1,0) [0|1] "" Vector__XXX

BO_ 990 FC_alertMatrix6: 8 FC
 SG_ FC_a321_FCAlertPlaceholder : 0|1@1+ (1,0) [0|1] "" Vector__XXX

BO_ 1117 FC_evseBilling: 8 FC
 SG_ FC_evseBillingDataSelect M : 0|1@1+ (1,0) [0|1] "" Vector__XXX
 SG_ FC_evseBillingEnergy m0 : 4|20@1+ (0.001,0) [0|1048.575] "kWh" Vector__XXX
 SG_ FC_evseMeterPower m0 : 24|20@1+ (0.001,0) [0|1048.575] "kW" Vector__XXX
 SG_ FC_evseMeterCurrent m0 : 44|10@1+ (1,0) [0|1023] "A" Vector__XXX
 SG_ FC_evseMeterVoltage m0 : 54|10@1+ (1,0) [0|1023] "V" Vector__XXX
 SG_ FC_evseMeterFwGitHash m1 : 4|56@1+ (1,0) [0|7.20575940379e+16] "" Vector__XXX

BO_ 1334 FC_evseBilling2: 8 FC
 SG_ FC_evseBilling2DataSelect M : 0|4@1+ (1,0) [0|15] "" Vector__XXX
 SG_ FC_evsePpuEnabled m0 : 4|1@1+ (1,0) [0|1] "" Vector__XXX
 SG_ FC_evseBillingEnergyHighRes m0 : 8|24@1+ (0.0001,0) [0|1677.7214] "kWh" Vector__XXX

BO_ 1303 FC_identifier: 8 FC
 SG_ FC_id : 0|32@1+ (1,0) [0|4294967295] "" Vector__XXX
 SG_ FC_sessionId : 32|32@1+ (1,0) [0|4294967295] "" Vector__XXX

BO_ 1310 FC_info: 8 FC
 SG_ FC_infoIndex M : 0|8@1+ (1,0) [0|255] "" Vector__XXX
 SG_ FC_infoBuildType m10 : 8|8@1+ (1,0) [0|255] "" Vector__XXX
 SG_ FC_infoBuildConfigID m10 : 16|16@1+ (1,0) [0|65535] "" Vector__XXX
 SG_ FC_infoHardwareID m10 : 32|16@1+ (1,0) [0|65535] "" Vector__XXX
 SG_ FC_infoComponentID m10 : 48|16@1+ (1,0) [0|65535] "" Vector__XXX
 SG_ FC_infoPcbaID m11 : 16|8@1+ (1,0) [0|255] "" Vector__XXX
 SG_ FC_infoAssemblyID m11 : 24|8@1+ (1,0) [0|255] "" Vector__XXX
 SG_ FC_infoUsageID m11 : 32|16@1+ (1,0) [0|65535] "" Vector__XXX
 SG_ FC_infoSubUsageID m11 : 48|16@1+ (1,0) [0|65535] "" Vector__XXX
 SG_ FC_infoApplicationCRC m13 : 32|32@1+ (1,0) [0|4294967295] "" Vector__XXX
 SG_ FC_infoAppGitHashBytes m17 : 8|56@1+ (1,0) [0|7.20575940379e+16] "" Vector__XXX
 SG_ FC_infoBootGitHashBytes m18 : 8|56@1+ (1,0) [0|7.20575940379e+16] "" Vector__XXX
 SG_ FC_infoPlatformType m19 : 8|8@1+ (1,0) [0|255] "" Vector__XXX
 SG_ FC_infoMajorVersion m19 : 16|8@1+ (1,0) [0|255] "" Vector__XXX
 SG_ FC_infoBranchOrigin m19 : 24|8@1+ (1,0) [0|255] "" Vector__XXX
 SG_ FC_infoMaturity m19 : 32|8@1+ (1,0) [0|255] "" Vector__XXX
 SG_ FC_infoHardwareRevision m19 : 40|8@1+ (1,0) [0|255] "" Vector__XXX
 SG_ FC_partNumChar01 m25 : 8|8@1+ (1,0) [0|255] "" Vector__XXX
 SG_ FC_partNumChar02 m25 : 16|8@1+ (1,0) [0|255] "" Vector__XXX
 SG_ FC_partNumChar03 m25 : 24|8@1+ (1,0) [0|255] "" Vector__XXX
 SG_ FC_partNumChar04 m25 : 32|8@1+ (1,0) [0|255] "" Vector__XXX
 SG_ FC_partNumChar05 m25 : 40|8@1+ (1,0) [0|255] "" Vector__XXX
 SG_ FC_partNumChar06 m25 : 48|8@1+ (1,0) [0|255] "" Vector__XXX
 SG_ FC_partNumChar07 m25 : 56|8@1+ (1,0) [0|255] "" Vector__XXX
 SG_ FC_partNumChar08 m26 : 8|8@1+ (1,0) [0|255] "" Vector__XXX
 SG_ FC_partNumChar09 m26 : 16|8@1+ (1,0) [0|255] "" Vector__XXX
 SG_ FC_partNumChar10 m26 : 24|8@1+ (1,0) [0|255] "" Vector__XXX
 SG_ FC_partNumChar11 m26 : 32|8@1+ (1,0) [0|255] "" Vector__XXX
 SG_ FC_partNumChar12 m26 : 40|8@1+ (1,0) [0|255] "" Vector__XXX
 SG_ FC_partNumChar13 m26 : 48|8@1+ (1,0) [0|255] "" Vector__XXX
 SG_ FC_partNumChar14 m26 : 56|8@1+ (1,0) [0|255] "" Vector__XXX
 SG_ FC_partNumChar15 m27 : 8|8@1+ (1,0) [0|255] "" Vector__XXX
 SG_ FC_partNumChar16 m27 : 16|8@1+ (1,0) [0|255] "" Vector__XXX
 SG_ FC_partNumChar17 m27 : 24|8@1+ (1,0) [0|255] "" Vector__XXX
 SG_ FC_partNumChar18 m27 : 32|8@1+ (1,0) [0|255] "" Vector__XXX
 SG_ FC_partNumChar19 m27 : 40|8@1+ (1,0) [0|255] "" Vector__XXX
 SG_ FC_partNumChar20 m27 : 48|8@1+ (1,0) [0|255] "" Vector__XXX

BO_ 580 FC_limits: 8 FC
 SG_ FC_powerLimit : 0|13@1+ (0.06225586,0) [0|509.8754934] "kW" Vector__XXX
 SG_ FC_currentLimit : 16|13@1+ (0.07324219,0) [0|599.8535361] "A" Vector__XXX
 SG_ FC_maxVoltageLimit : 32|13@1+ (0.07324219,0) [0|599.8535361] "V" Vector__XXX
 SG_ FC_minVoltageLimit : 48|13@1+ (0.07324219,0) [0|599.8535361] "V" Vector__XXX

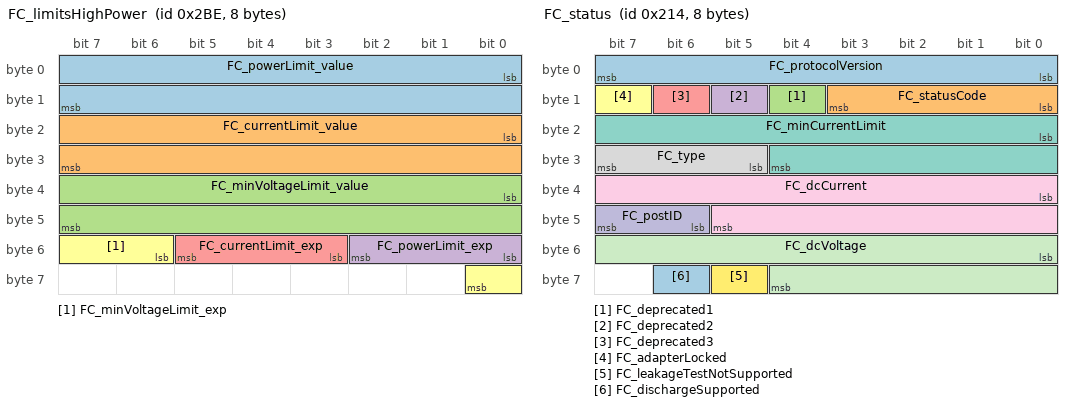
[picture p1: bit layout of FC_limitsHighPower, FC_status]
BO_ 702 FC_limitsHighPower: 8 FC
 SG_ FC_powerLimit_value : 0|16@1- (1,0) [-32767|32767] "*10^exp kW" Vector__XXX
 SG_ FC_currentLimit_value : 16|16@1- (1,0) [-32767|32767] "*10^exp A" Vector__XXX
 SG_ FC_minVoltageLimit_value : 32|16@1- (1,0) [-32767|32767] "*10^exp V" Vector__XXX
 SG_ FC_powerLimit_exp : 48|3@1- (1,0) [-4|3] "" Vector__XXX
 SG_ FC_currentLimit_exp : 51|3@1- (1,0) [-4|3] "" Vector__XXX
 SG_ FC_minVoltageLimit_exp : 54|3@1- (1,0) [-4|3] "" Vector__XXX

BO_ 1345 FC_maxLimits: 8 FC
 SG_ FC_maxPowerLimit : 0|13@1+ (0.06225586,0) [0|509.8754934] "kW" Vector__XXX
 SG_ FC_maxCurrentLimit : 16|13@1+ (0.07324219,0) [0|599.8535361] "A" Vector__XXX

BO_ 1300 FC_serial: 8 FC
 SG_ FC_serialDataSelect M : 0|7@1+ (1,0) [0|127] "" Vector__XXX
 SG_ FC_serialChar01 m0 : 8|8@1+ (1,0) [0|255] "" Vector__XXX
 SG_ FC_serialChar02 m0 : 16|8@1+ (1,0) [0|255] "" Vector__XXX
 SG_ FC_serialChar03 m0 : 24|8@1+ (1,0) [0|255] "" Vector__XXX
 SG_ FC_serialChar04 m0 : 32|8@1+ (1,0) [0|255] "" Vector__XXX
 SG_ FC_serialChar05 m0 : 40|8@1+ (1,0) [0|255] "" Vector__XXX
 SG_ FC_serialChar06 m0 : 48|8@1+ (1,0) [0|255] "" Vector__XXX
 SG_ FC_serialChar07 m0 : 56|8@1+ (1,0) [0|255] "" Vector__XXX
 SG_ FC_serialChar08 m1 : 8|8@1+ (1,0) [0|255] "" Vector__XXX
 SG_ FC_serialChar09 m1 : 16|8@1+ (1,0) [0|255] "" Vector__XXX
 SG_ FC_serialChar10 m1 : 24|8@1+ (1,0) [0|255] "" Vector__XXX
 SG_ FC_serialChar11 m1 : 32|8@1+ (1,0) [0|255] "" Vector__XXX
 SG_ FC_serialChar12 m1 : 40|8@1+ (1,0) [0|255] "" Vector__XXX
 SG_ FC_serialChar13 m1 : 48|8@1+ (1,0) [0|255] "" Vector__XXX
 SG_ FC_serialChar14 m1 : 56|8@1+ (1,0) [0|255] "" Vector__XXX
 SG_ FC_serialChar15 m2 : 8|8@1+ (1,0) [0|255] "" Vector__XXX
 SG_ FC_serialChar16 m2 : 16|8@1+ (1,0) [0|255] "" Vector__XXX
 SG_ FC_serialChar17 m2 : 24|8@1+ (1,0) [0|255] "" Vector__XXX

BO_ 532 FC_status: 8 FC
 SG_ FC_protocolVersion : 0|8@1+ (1,0) [0|255] "" Vector__XXX
 SG_ FC_statusCode : 8|4@1+ (1,0) [1|15] "" Vector__XXX
 SG_ FC_deprecated1 : 12|1@1+ (1,0) [0|1] "" Vector__XXX
 SG_ FC_deprecated2 : 13|1@1+ (1,0) [0|1] "" Vector__XXX
 SG_ FC_deprecated3 : 14|1@1+ (1,0) [0|1] "" Vector__XXX
 SG_ FC_adapterLocked : 15|1@1+ (1,0) [0|1] "" Vector__XXX
 SG_ FC_minCurrentLimit : 16|13@1+ (0.1,0) [0|600] "A" Vector__XXX
 SG_ FC_type : 29|3@1+ (1,0) [0|6] "" Vector__XXX
 SG_ FC_dcCurrent : 32|14@1- (0.07324219,0) [-600|599.92675781] "A" Vector__XXX
 SG_ FC_postID : 46|2@1+ (1,0) [0|2] "" Vector__XXX
 SG_ FC_dcVoltage : 48|13@1+ (0.07324219,0) [0|599.92675822] "V" Vector__XXX
 SG_ FC_leakageTestNotSupported : 61|1@1+ (1,0) [0|1] "" Vector__XXX
 SG_ FC_dischargeSupported : 62|1@1+ (1,0) [0|1] "" Vector__XXX

BO_ 533 FC_status2: 1 FC
 SG_ FC_externalIsolationResistance : 0|8@1+ (40,0) [0|10160] "kOhm" Vector__XXX

BO_ 535 FC_status3: 8 FC
 SG_ FC_status3DataSelect M : 0|7@1+ (1,0) [0|127] "" Vector__XXX
 SG_ FC_status3DummySig : 7|1@1+ (1,0) [0|1] "" Vector__XXX
 SG_ FC_class m0 : 8|8@1+ (1,0) [1|255] "" Vector__XXX
 SG_ FC_brand m0 : 16|4@1+ (1,0) [1|15] "" Vector__XXX
 SG_ FC_coolingType m0 : 20|4@1+ (1,0) [1|15] "" Vector__XXX
 SG_ FC_uiStopType m0 : 24|4@1+ (1,0) [1|15] "" Vector__XXX
 SG_ FC_emergencyShutdownSupported m0 : 28|1@1+ (1,0) [0|1] "" Vector__XXX
 SG_ FC_generation m0 : 32|8@1+ (1,0) [1|255] "" Vector__XXX

BO_ 1650 HCML_info: 7 HCML
 SG_ VC_hcmlInfoIndex M : 0|4@1+ (1,0) [0|15] "" Vector__XXX
 SG_ VC_infoHCMLBuildConfigId m0 : 8|16@1+ (1,0) [0|65535] "" Vector__XXX
 SG_ VC_leftHeadlampLMMVariant m0 : 24|2@1+ (1,0) [1|3] "" Vector__XXX
 SG_ VC_infoHCMLAssemblyId m1 : 8|16@1+ (1,0) [0|65535] "" Vector__XXX
 SG_ VC_infoHCMLPcbaId m1 : 24|16@1+ (1,0) [0|65535] "" Vector__XXX
 SG_ VC_infoHCMLUsageId m1 : 40|16@1+ (1,0) [0|65535] "" Vector__XXX

BO_ 1980 HCMR_info: 7 HCMR
 SG_ VC_hcmrInfoIndex M : 0|4@1+ (1,0) [0|15] "" Vector__XXX
 SG_ VC_infoHCMRBuildConfigId m0 : 8|16@1+ (1,0) [0|65535] "" Vector__XXX
 SG_ VC_rightHeadlampLMMVariant m0 : 24|2@1+ (1,0) [1|3] "" Vector__XXX
 SG_ VC_infoHCMRAssemblyId m1 : 8|16@1+ (1,0) [0|65535] "" Vector__XXX
 SG_ VC_infoHCMRPcbaId m1 : 24|16@1+ (1,0) [0|65535] "" Vector__XXX
 SG_ VC_infoHCMRUsageId m1 : 40|16@1+ (1,0) [0|65535] "" Vector__XXX

BO_ 1290 HVP_alertLog: 8 HVP
 SG_ HVP_alertID M : 0|7@1+ (1,0) [0|127] "" Vector__XXX
 SG_ HVP_alertSet : 15|1@1+ (1,0) [0|1] "" Vector__XXX
 SG_ HVP_a005_current m5 : 16|24@1- (0.001,0) [-8388.608|8388.607] "A" Vector__XXX
 SG_ HVP_a006_current m6 : 16|24@1- (0.001,0) [-8388.608|8388.607] "A" Vector__XXX
 SG_ HVP_a007_current m7 : 16|24@1- (0.001,0) [-8388.608|8388.607] "A" Vector__XXX
 SG_ HVP_a008_temperature m8 : 16|16@1- (0.01,0) [-327.68|327.67] "C" Vector__XXX
 SG_ HVP_a008_sensorId m8 : 32|6@1+ (1,1) [1|64] "" Vector__XXX
 SG_ HVP_a008_primaryChainSensor m8 : 38|1@1+ (1,0) [0|1] "" Vector__XXX
 SG_ HVP_a009_brickVoltage m9 : 16|16@1- (0.001,0) [-32.768|32.767] "V" Vector__XXX
 SG_ HVP_a009_brickId m9 : 32|7@1+ (1,1) [1|128] "" Vector__XXX
 SG_ HVP_a009_primaryChainSensor m9 : 39|1@1+ (1,0) [0|1] "" Vector__XXX
 SG_ HVP_a010_brickVoltage m10 : 16|16@1- (0.001,0) [-32.768|32.767] "V" Vector__XXX
 SG_ HVP_a010_brickId m10 : 32|7@1+ (1,1) [1|128] "" Vector__XXX
 SG_ HVP_a010_primaryChainSensor m10 : 39|1@1+ (1,0) [0|1] "" Vector__XXX
 SG_ HVP_a012_breakLocationA m12 : 16|5@1+ (1,0) [0|31] "" Vector__XXX
 SG_ HVP_a012_bmbCommStatusTypeA m12 : 21|2@1+ (1,0) [0|3] "" Vector__XXX
 SG_ HVP_a012_breakLocationB m12 : 24|5@1+ (1,0) [0|31] "" Vector__XXX
 SG_ HVP_a012_bmbCommStatusTypeB m12 : 29|2@1+ (1,0) [0|3] "" Vector__XXX
 SG_ HVP_a013_breakLocationA m13 : 16|5@1+ (1,0) [0|31] "" Vector__XXX
 SG_ HVP_a013_bmbCommStatusTypeA m13 : 21|2@1+ (1,0) [0|3] "" Vector__XXX
 SG_ HVP_a013_breakLocationB m13 : 24|5@1+ (1,0) [0|31] "" Vector__XXX
 SG_ HVP_a013_bmbCommStatusTypeB m13 : 29|2@1+ (1,0) [0|3] "" Vector__XXX
 SG_ HVP_a013_bmbChainBreakType m13 : 32|3@1+ (1,0) [0|7] "" Vector__XXX
 SG_ HVP_a018_dcLinkVoltage m18 : 16|16@1+ (0.01,0) [0|655.35] "V" Vector__XXX
 SG_ HVP_a018_battery12V m18 : 32|12@1+ (0.1,0) [0|409.5] "V" Vector__XXX
 SG_ HVP_a018_remainingPcsPowerCycles m18 : 44|2@1+ (1,0) [0|3] "" Vector__XXX
 SG_ HVP_a018_remainingPcsRecoveriesA m18 : 46|2@1+ (1,0) [0|3] "" Vector__XXX
 SG_ HVP_a018_hvcHardwareSupportsCycl m18 : 48|1@1+ (1,0) [0|1] "" Vector__XXX
 SG_ HVP_a018_pcsHardwareOkToBePowerC m18 : 49|1@1+ (1,0) [0|1] "" Vector__XXX
 SG_ HVP_a018_gpioLogicPowerEnable m18 : 50|1@1+ (1,0) [0|1] "" Vector__XXX
 SG_ HVP_a018_gpioDcDcEnable m18 : 51|1@1+ (1,0) [0|1] "" Vector__XXX
 SG_ HVP_a018_gpioChgEnable m18 : 52|1@1+ (1,0) [0|1] "" Vector__XXX
 SG_ HVP_a020_energyReserveV m20 : 16|16@1+ (0.001,0) [0|65.534] "V" Vector__XXX
 SG_ HVP_a020_shuntCurrentAux m20 : 32|16@1- (0.1,0) [-3276.8|3276.7] "A" Vector__XXX
 SG_ HVP_a020_shuntTemperature m20 : 48|16@1- (0.01,0) [-327.68|327.67] "C" Vector__XXX
 SG_ HVP_a021_pyroStatus m21 : 16|2@1+ (1,0) [0|3] "" Vector__XXX
 SG_ HVP_a021_ErTestFailed m21 : 18|1@1+ (1,0) [0|1] "" Vector__XXX
 SG_ HVP_a021_HighSideSwitchTestFaile m21 : 19|1@1+ (1,0) [0|1] "" Vector__XXX
 SG_ HVP_a021_LowSideSwitchTestFailed m21 : 20|1@1+ (1,0) [0|1] "" Vector__XXX
 SG_ HVP_a021_RefCurrentTestFailed m21 : 21|1@1+ (1,0) [0|1] "" Vector__XXX
 SG_ HVP_a021_PyroLeakTestFailed m21 : 22|1@1+ (1,0) [0|1] "" Vector__XXX
 SG_ HVP_a021_SquibResTestFailed m21 : 23|1@1+ (1,0) [0|1] "" Vector__XXX
 SG_ HVP_a021_VstTestFailed m21 : 24|1@1+ (1,0) [0|1] "" Vector__XXX
 SG_ HVP_a021_SquibResistance m21 : 25|16@1+ (0.001,0) [0|65.534] "Ohm" Vector__XXX
 SG_ HVP_a021_OneShotSequence m21 : 41|1@1+ (1,0) [0|1] "" Vector__XXX
 SG_ HVP_a021_HighSide m21 : 42|1@1+ (1,0) [0|1] "" Vector__XXX
 SG_ HVP_a021_LowSide m21 : 43|1@1+ (1,0) [0|1] "" Vector__XXX
 SG_ HVP_a021_Aout m21 : 44|14@1+ (0.001,0) [0|16.382] "V" Vector__XXX
 SG_ HVP_a022_pyroStatus m22 : 16|2@1+ (1,0) [0|3] "" Vector__XXX
 SG_ HVP_a022_PyroLeakTestFailed m22 : 18|1@1+ (1,0) [0|1] "" Vector__XXX
 SG_ HVP_a022_OneShotSequence m22 : 19|1@1+ (1,0) [0|1] "" Vector__XXX
 SG_ HVP_a022_HighSide m22 : 20|1@1+ (1,0) [0|1] "" Vector__XXX
 SG_ HVP_a022_LowSide m22 : 21|1@1+ (1,0) [0|1] "" Vector__XXX
 SG_ HVP_a022_Aout m22 : 24|14@1+ (0.001,0) [0|16.382] "V" Vector__XXX
 SG_ HVP_a022_SquibResistance m22 : 40|16@1+ (0.001,0) [0|65.534] "Ohm" Vector__XXX
 SG_ HVP_a024_voltage m24 : 16|16@1+ (0.1,0) [0|6553.5] "V" Vector__XXX
 SG_ HVP_a025_voltage1 m25 : 16|16@1+ (0.1,0) [0|6553.5] "V" Vector__XXX
 SG_ HVP_a025_voltage2 m25 : 32|16@1+ (0.1,0) [0|6553.5] "V" Vector__XXX
 SG_ HVP_a025_packVoltage m25 : 48|16@1+ (0.1,0) [0|6553.5] "V" Vector__XXX
 SG_ HVP_a026_hvilStatus m26 : 16|4@1+ (1,0) [0|15] "" Vector__XXX
 SG_ HVP_a026_inputVoltage m26 : 24|8@1+ (0.04,0) [0|10.2] "V" Vector__XXX
 SG_ HVP_a026_outputVoltage m26 : 32|8@1+ (0.04,0) [0|10.2] "V" Vector__XXX
 SG_ HVP_a026_internalVoltage m26 : 40|8@1+ (0.04,0) [0|10.16] "V" Vector__XXX
 SG_ HVP_a026_dirVoltage m26 : 48|8@1+ (0.04,0) [0|10.16] "V" Vector__XXX
 SG_ HVP_a026_difVoltage m26 : 56|8@1+ (0.04,0) [0|10.16] "V" Vector__XXX
 SG_ HVP_a028_packVoltage m28 : 16|16@1+ (0.1,0) [0|6553.5] "V" Vector__XXX
 SG_ HVP_a028_sumOfBrickV m28 : 32|16@1+ (0.1,0) [0|6553.5] "V" Vector__XXX
 SG_ HVP_a030_packPositiveLinkV m30 : 16|16@1- (0.1,0) [-3276.8|3276.7] "V" Vector__XXX
 SG_ HVP_a030_dcPositiveLinkV m30 : 32|16@1- (0.1,0) [-3276.8|3276.7] "V" Vector__XXX
 SG_ HVP_a031_packNegativeLinkV m31 : 16|16@1- (0.1,0) [-3276.8|3276.7] "V" Vector__XXX
 SG_ HVP_a031_dcNegativeLinkV m31 : 32|16@1- (0.1,0) [-3276.8|3276.7] "V" Vector__XXX
 SG_ HVP_a033_contactorPowerV m33 : 16|16@1+ (0.1,0) [0|6553.5] "V" Vector__XXX
 SG_ HVP_a033_coilCurrent m33 : 32|16@1+ (0.1,0) [0|6553.5] "A" Vector__XXX
 SG_ HVP_a033_pwmDutyCylePositive m33 : 48|8@1+ (1,0) [0|255] "Percentage" Vector__XXX
 SG_ HVP_a033_pwmDutyCyleNegative m33 : 56|8@1+ (1,0) [0|255] "Percentage" Vector__XXX
 SG_ HVP_a035_contactorPowerV m35 : 16|16@1+ (0.1,0) [0|6553.5] "V" Vector__XXX
 SG_ HVP_a035_coilCurrent m35 : 32|16@1+ (0.1,0) [0|6553.5] "A" Vector__XXX
 SG_ HVP_a035_pwmDutyCylePositive m35 : 48|8@1+ (1,0) [0|255] "Percentage" Vector__XXX
 SG_ HVP_a035_pwmDutyCyleNegative m35 : 56|8@1+ (1,0) [0|255] "Percentage" Vector__XXX
 SG_ HVP_a036_pyroFiringHandle m36 : 16|4@1+ (1,0) [0|15] "" Vector__XXX
 SG_ HVP_a036_pyroFiringTime m36 : 24|16@1+ (1,0) [0|65535] "" Vector__XXX
 SG_ HVP_a036_pyroFiringAttempt m36 : 40|4@1+ (1,0) [0|15] "" Vector__XXX
 SG_ HVP_a037_pyroFiringHandle m37 : 16|4@1+ (1,0) [0|15] "" Vector__XXX
 SG_ HVP_a039_posContactorFailed m39 : 16|1@1+ (1,0) [0|1] "" Vector__XXX
 SG_ HVP_a039_negContactorFailed m39 : 17|1@1+ (1,0) [0|1] "" Vector__XXX
 SG_ HVP_a040_powerVoltage m40 : 16|8@1+ (0.1,0) [0|25.5] "V" Vector__XXX
 SG_ HVP_a040_coilCurrent m40 : 24|8@1+ (0.1,0) [0|25.5] "A" Vector__XXX
 SG_ HVP_a040_posCtrVoltageDrop m40 : 32|15@1- (0.1,0) [-1638.4|1638.3] "V" Vector__XXX
 SG_ HVP_a040_negCtrVoltageDrop m40 : 47|15@1- (0.1,0) [-1638.4|1638.3] "V" Vector__XXX
 SG_ HVP_a040_posCtrAuxOpen m40 : 62|1@1+ (1,0) [0|1] "" Vector__XXX
 SG_ HVP_a040_negCtrAuxOpen m40 : 63|1@1+ (1,0) [0|1] "" Vector__XXX
 SG_ HVP_a041_overCurrent m41 : 16|1@1+ (1,0) [0|1] "" Vector__XXX
 SG_ HVP_a041_overChargeCurrent m41 : 17|1@1+ (1,0) [0|1] "" Vector__XXX
 SG_ HVP_a041_overDischargeCurrent m41 : 18|1@1+ (1,0) [0|1] "" Vector__XXX
 SG_ HVP_a041_overVoltage m41 : 19|1@1+ (1,0) [0|1] "" Vector__XXX
 SG_ HVP_a041_overTemperature m41 : 20|1@1+ (1,0) [0|1] "" Vector__XXX
 SG_ HVP_a041_underVoltage m41 : 21|1@1+ (1,0) [0|1] "" Vector__XXX
 SG_ HVP_a041_crashEvent m41 : 22|1@1+ (1,0) [0|1] "" Vector__XXX
 SG_ HVP_a041_packContactorHw m41 : 23|1@1+ (1,0) [0|1] "" Vector__XXX
 SG_ HVP_a041_notAllowedtoEnergize m41 : 24|1@1+ (1,0) [0|1] "" Vector__XXX
 SG_ HVP_a041_bmbMia m41 : 25|1@1+ (1,0) [0|1] "" Vector__XXX
 SG_ HVP_a041_hvilFault m41 : 26|1@1+ (1,0) [0|1] "" Vector__XXX
 SG_ HVP_a041_contactorStateWelded m41 : 27|1@1+ (1,0) [0|1] "" Vector__XXX
 SG_ HVP_a041_shuntHwMia m41 : 28|1@1+ (1,0) [0|1] "" Vector__XXX
 SG_ HVP_a041_shuntCurrentMia m41 : 29|1@1+ (1,0) [0|1] "" Vector__XXX
 SG_ HVP_a041_packVoltageMismatch m41 : 30|1@1+ (1,0) [0|1] "" Vector__XXX
 SG_ HVP_a041_gpoRequestActive m41 : 31|1@1+ (1,0) [0|1] "" Vector__XXX
 SG_ HVP_a041_fcContactorClosing m41 : 32|1@1+ (1,0) [0|1] "" Vector__XXX
 SG_ HVP_a041_fcContactorOpening m41 : 33|1@1+ (1,0) [0|1] "" Vector__XXX
 SG_ HVP_a041_resetRequestRequired m41 : 34|1@1+ (1,0) [0|1] "" Vector__XXX
 SG_ HVP_a041_pyroFault m41 : 35|1@1+ (1,0) [0|1] "" Vector__XXX
 SG_ HVP_a041_dcLinkOverVoltage m41 : 36|1@1+ (1,0) [0|1] "" Vector__XXX
 SG_ HVP_a042_overCurrent m42 : 16|1@1+ (1,0) [0|1] "" Vector__XXX
 SG_ HVP_a042_overChargeCurrent m42 : 17|1@1+ (1,0) [0|1] "" Vector__XXX
 SG_ HVP_a042_overDischargeCurrent m42 : 18|1@1+ (1,0) [0|1] "" Vector__XXX
 SG_ HVP_a042_overVoltage m42 : 19|1@1+ (1,0) [0|1] "" Vector__XXX
 SG_ HVP_a042_overTemperature m42 : 20|1@1+ (1,0) [0|1] "" Vector__XXX
 SG_ HVP_a042_crashEvent m42 : 21|1@1+ (1,0) [0|1] "" Vector__XXX
 SG_ HVP_a042_fcContactorHw m42 : 22|1@1+ (1,0) [0|1] "" Vector__XXX
 SG_ HVP_a042_notAllowedtoEnergize m42 : 23|1@1+ (1,0) [0|1] "" Vector__XXX
 SG_ HVP_a042_bmsHvsMia m42 : 24|1@1+ (1,0) [0|1] "" Vector__XXX
 SG_ HVP_a042_cpMia m42 : 25|1@1+ (1,0) [0|1] "" Vector__XXX
 SG_ HVP_a042_cpFault m42 : 26|1@1+ (1,0) [0|1] "" Vector__XXX
 SG_ HVP_a042_supply12V m42 : 27|1@1+ (1,0) [0|1] "" Vector__XXX
 SG_ HVP_a042_supplyVer m42 : 28|1@1+ (1,0) [0|1] "" Vector__XXX
 SG_ HVP_a042_packVoltageMismatch m42 : 29|1@1+ (1,0) [0|1] "" Vector__XXX
 SG_ HVP_a042_hvilFault m42 : 30|1@1+ (1,0) [0|1] "" Vector__XXX
 SG_ HVP_a042_contactorStateWelded m42 : 31|1@1+ (1,0) [0|1] "" Vector__XXX
 SG_ HVP_a042_shuntHwMia m42 : 32|1@1+ (1,0) [0|1] "" Vector__XXX
 SG_ HVP_a042_shuntCurrentMia m42 : 33|1@1+ (1,0) [0|1] "" Vector__XXX
 SG_ HVP_a042_packContactorClosing m42 : 34|1@1+ (1,0) [0|1] "" Vector__XXX
 SG_ HVP_a042_packContactorOpening m42 : 35|1@1+ (1,0) [0|1] "" Vector__XXX
 SG_ HVP_a042_resetRequestRequired m42 : 36|1@1+ (1,0) [0|1] "" Vector__XXX
 SG_ HVP_a042_cpVersionMismatch m42 : 37|1@1+ (1,0) [0|1] "" Vector__XXX
 SG_ HVP_a043_overCurrent m43 : 16|1@1+ (1,0) [0|1] "" Vector__XXX
 SG_ HVP_a043_overChargeCurrent m43 : 17|1@1+ (1,0) [0|1] "" Vector__XXX
 SG_ HVP_a043_overDischargeCurrent m43 : 18|1@1+ (1,0) [0|1] "" Vector__XXX
 SG_ HVP_a043_overVoltage m43 : 19|1@1+ (1,0) [0|1] "" Vector__XXX
 SG_ HVP_a043_overTemperature m43 : 20|1@1+ (1,0) [0|1] "" Vector__XXX
 SG_ HVP_a043_underVoltage m43 : 21|1@1+ (1,0) [0|1] "" Vector__XXX
 SG_ HVP_a043_crashEvent m43 : 22|1@1+ (1,0) [0|1] "" Vector__XXX
 SG_ HVP_a043_packContactorHw m43 : 23|1@1+ (1,0) [0|1] "" Vector__XXX
 SG_ HVP_a043_notAllowedtoEnergize m43 : 24|1@1+ (1,0) [0|1] "" Vector__XXX
 SG_ HVP_a043_bmbMia m43 : 25|1@1+ (1,0) [0|1] "" Vector__XXX
 SG_ HVP_a043_contactorOpened m43 : 26|1@1+ (1,0) [0|1] "" Vector__XXX
 SG_ HVP_a044_overCurrent m44 : 16|1@1+ (1,0) [0|1] "" Vector__XXX
 SG_ HVP_a044_overChargeCurrent m44 : 17|1@1+ (1,0) [0|1] "" Vector__XXX
 SG_ HVP_a044_overDischargeCurrent m44 : 18|1@1+ (1,0) [0|1] "" Vector__XXX
 SG_ HVP_a044_overVoltage m44 : 19|1@1+ (1,0) [0|1] "" Vector__XXX
 SG_ HVP_a044_overTemperature m44 : 20|1@1+ (1,0) [0|1] "" Vector__XXX
 SG_ HVP_a044_crashEvent m44 : 21|1@1+ (1,0) [0|1] "" Vector__XXX
 SG_ HVP_a044_fcContactorHw m44 : 22|1@1+ (1,0) [0|1] "" Vector__XXX
 SG_ HVP_a044_notAllowedtoEnergize m44 : 23|1@1+ (1,0) [0|1] "" Vector__XXX
 SG_ HVP_a044_bmsHvsMia m44 : 24|1@1+ (1,0) [0|1] "" Vector__XXX
 SG_ HVP_a044_cpMia m44 : 25|1@1+ (1,0) [0|1] "" Vector__XXX
 SG_ HVP_a044_cpFault m44 : 26|1@1+ (1,0) [0|1] "" Vector__XXX
 SG_ HVP_a044_supply12V m44 : 27|1@1+ (1,0) [0|1] "" Vector__XXX
 SG_ HVP_a044_supplyVer m44 : 28|1@1+ (1,0) [0|1] "" Vector__XXX
 SG_ HVP_a044_packVoltageMismatch m44 : 29|1@1+ (1,0) [0|1] "" Vector__XXX
 SG_ HVP_a044_contactorOpened m44 : 30|1@1+ (1,0) [0|1] "" Vector__XXX
 SG_ HVP_a044_cpVersionMismatch m44 : 31|1@1+ (1,0) [0|1] "" Vector__XXX
 SG_ HVP_a045_dcLinkVoltage m45 : 16|16@1+ (0.1,0) [0|6553.5] "V" Vector__XXX
 SG_ HVP_a046_shuntCurrent m46 : 16|16@1- (0.1,0) [-3276.8|3276.7] "A" Vector__XXX
 SG_ HVP_a046_shuntTemperature m46 : 32|16@1- (0.01,0) [-327.68|327.67] "C" Vector__XXX
 SG_ HVP_a046_asicTemperature m46 : 48|16@1- (0.01,0) [-327.68|327.67] "C" Vector__XXX
 SG_ HVP_a047_shuntCurrent m47 : 16|16@1- (0.1,0) [-3276.8|3276.7] "A" Vector__XXX
 SG_ HVP_a047_auxCurrent m47 : 32|16@1- (0.1,0) [-3276.8|3276.7] "A" Vector__XXX
 SG_ HVP_a049_contactorPowerV m49 : 16|16@1+ (0.1,0) [0|6553.5] "V" Vector__XXX
 SG_ HVP_a049_coilCurrent m49 : 32|16@1+ (0.1,0) [0|6553.5] "A" Vector__XXX
 SG_ HVP_a049_posCtrState m49 : 48|3@1+ (1,0) [1|7] "" Vector__XXX
 SG_ HVP_a049_negCtrState m49 : 51|3@1+ (1,0) [1|7] "" Vector__XXX
 SG_ HVP_a050_contactorPowerV m50 : 16|16@1+ (0.1,0) [0|6553.5] "V" Vector__XXX
 SG_ HVP_a050_coilCurrent m50 : 32|16@1+ (0.1,0) [0|6553.5] "A" Vector__XXX
 SG_ HVP_a050_posCtrState m50 : 48|3@1+ (1,0) [1|7] "" Vector__XXX
 SG_ HVP_a050_negCtrState m50 : 51|3@1+ (1,0) [1|7] "" Vector__XXX
 SG_ HVP_a051_shuntTemperature m51 : 16|16@1- (0.01,0) [-327.68|327.67] "C" Vector__XXX
 SG_ HVP_a051_shuntCurrent m51 : 32|16@1- (0.1,0) [-3276.8|3276.7] "A" Vector__XXX
 SG_ HVP_a051_energyReserveV m51 : 48|16@1+ (0.001,0) [0|65.534] "V" Vector__XXX
 SG_ HVP_a053_packVoltage m53 : 16|16@1+ (0.01,0) [0|655.35] "V" Vector__XXX
 SG_ HVP_a053_dcLinkVoltage m53 : 32|16@1+ (0.01,0) [0|655.35] "V" Vector__XXX
 SG_ HVP_a056_diagnosis m56 : 16|2@1+ (1,0) [1|3] "" Vector__XXX
 SG_ HVP_a056_shuntCurrent m56 : 24|16@1- (0.1,0) [-3276.8|3276.7] "A" Vector__XXX
 SG_ HVP_a056_posPackContactorState m56 : 40|3@1+ (1,0) [1|7] "" Vector__XXX
 SG_ HVP_a056_negPackContactorState m56 : 43|3@1+ (1,0) [1|7] "" Vector__XXX
 SG_ HVP_a056_posFcContactorState m56 : 48|3@1+ (1,0) [1|7] "" Vector__XXX
 SG_ HVP_a056_negFcContactorState m56 : 51|3@1+ (1,0) [1|7] "" Vector__XXX
 SG_ HVP_a058_VrefSample m58 : 16|16@1+ (0.0001,0) [0|6.5535] "V" Vector__XXX
 SG_ HVP_a058_bmbDeviceId m58 : 32|4@1+ (1,1) [1|16] "" Vector__XXX
 SG_ HVP_a058_VrefStatus m58 : 36|2@1+ (1,0) [0|3] "" Vector__XXX
 SG_ HVP_a058_VrefType m58 : 38|2@1+ (1,0) [0|3] "" Vector__XXX
 SG_ HVP_a060_stackVoltage m60 : 16|16@1+ (0.00128,0) [0|83.8848] "V" Vector__XXX
 SG_ HVP_a060_sumBrickVoltage m60 : 32|16@1+ (0.00128,0) [0|83.8848] "V" Vector__XXX
 SG_ HVP_a060_stackId m60 : 48|8@1+ (1,1) [1|256] "" Vector__XXX
 SG_ HVP_a062_bmbDeviceMask m62 : 16|16@1+ (1,0) [0|65535] "" Vector__XXX
 SG_ HVP_a067_hvilTypeFromHvp m67 : 16|2@1+ (1,0) [0|3] "" Vector__XXX
 SG_ HVP_a067_hvilTypeFromGateway m67 : 18|2@1+ (1,0) [0|3] "" Vector__XXX
 SG_ HVP_a067_hvilTypeIsFromCal m67 : 20|1@1+ (1,0) [0|1] "" Vector__XXX
 SG_ HVP_a068_shuntTemperature m68 : 16|16@1- (0.01,0) [-327.68|327.67] "C" Vector__XXX
 SG_ HVP_a068_shuntCurrent m68 : 32|16@1- (0.1,0) [-3276.8|3276.7] "A" Vector__XXX
 SG_ HVP_a068_energyReserveV m68 : 48|16@1+ (0.001,0) [0|65.534] "V" Vector__XXX

BO_ 938 HVP_alertMatrix: 8 HVP
 SG_ HVP_matrixIndex M : 0|4@1+ (1,0) [0|15] "" Vector__XXX
 SG_ HVP_w001_WatchdogReset m0 : 4|1@1+ (1,0) [0|1] "" Vector__XXX
 SG_ HVP_w002_UnusedAlert2 m0 : 5|1@1+ (1,0) [0|1] "" Vector__XXX
 SG_ HVP_w003_SwAssertion m0 : 6|1@1+ (1,0) [0|1] "" Vector__XXX
 SG_ HVP_w004_CrashEvent m0 : 7|1@1+ (1,0) [0|1] "" Vector__XXX
 SG_ HVP_w005_OverDchgCurrentFault m0 : 8|1@1+ (1,0) [0|1] "" Vector__XXX
 SG_ HVP_w006_OverChargeCurrentFault m0 : 9|1@1+ (1,0) [0|1] "" Vector__XXX
 SG_ HVP_w007_OverCurrentFault m0 : 10|1@1+ (1,0) [0|1] "" Vector__XXX
 SG_ HVP_w008_OverTemperatureFault m0 : 11|1@1+ (1,0) [0|1] "" Vector__XXX
 SG_ HVP_w009_OverVoltageFault m0 : 12|1@1+ (1,0) [0|1] "" Vector__XXX
 SG_ HVP_w010_UnderVoltageFault m0 : 13|1@1+ (1,0) [0|1] "" Vector__XXX
 SG_ HVP_w011_PrimaryBmbMiaFault m0 : 14|1@1+ (1,0) [0|1] "" Vector__XXX
 SG_ HVP_w012_BmbDataIntegrityLoss m0 : 15|1@1+ (1,0) [0|1] "" Vector__XXX
 SG_ HVP_w013_BmbCommunication m0 : 16|1@1+ (1,0) [0|1] "" Vector__XXX
 SG_ HVP_w014_BmsMiaOnHviFault m0 : 17|1@1+ (1,0) [0|1] "" Vector__XXX
 SG_ HVP_w015_CpMiaFault m0 : 18|1@1+ (1,0) [0|1] "" Vector__XXX
 SG_ HVP_w016_PcsMiaFault m0 : 19|1@1+ (1,0) [0|1] "" Vector__XXX
 SG_ HVP_w017_GtwMiaFault m0 : 20|1@1+ (1,0) [0|1] "" Vector__XXX
 SG_ HVP_w018_powerCyclingPcs m0 : 21|1@1+ (1,0) [0|1] "" Vector__XXX
 SG_ HVP_w019_CpFault m0 : 22|1@1+ (1,0) [0|1] "" Vector__XXX
 SG_ HVP_w020_ShuntHwMiaFault m0 : 23|1@1+ (1,0) [0|1] "" Vector__XXX
 SG_ HVP_w021_PyroMiaFault m0 : 24|1@1+ (1,0) [0|1] "" Vector__XXX
 SG_ HVP_w022_PyroMiaWarning m0 : 25|1@1+ (1,0) [0|1] "" Vector__XXX
 SG_ HVP_w023_BmbResetRecovery m0 : 26|1@1+ (1,0) [0|1] "" Vector__XXX
 SG_ HVP_w024_Supply12vFault m0 : 27|1@1+ (1,0) [0|1] "" Vector__XXX
 SG_ HVP_w025_VerSupplyFault m0 : 28|1@1+ (1,0) [0|1] "" Vector__XXX
 SG_ HVP_w026_HvilFault m0 : 29|1@1+ (1,0) [0|1] "" Vector__XXX
 SG_ HVP_w027_BmsMiaOnHvsFault m0 : 30|1@1+ (1,0) [0|1] "" Vector__XXX
 SG_ HVP_w028_PackVoltMismatchFault m0 : 31|1@1+ (1,0) [0|1] "" Vector__XXX
 SG_ HVP_w029_EnsMiaFault m0 : 32|1@1+ (1,0) [0|1] "" Vector__XXX
 SG_ HVP_w030_PackPosCtrArcFault m0 : 33|1@1+ (1,0) [0|1] "" Vector__XXX
 SG_ HVP_w031_packNegCtrArcFault m0 : 34|1@1+ (1,0) [0|1] "" Vector__XXX
 SG_ HVP_w032_ShuntHwAndBmsMiaFault m0 : 35|1@1+ (1,0) [0|1] "" Vector__XXX
 SG_ HVP_w033_fcContHwFault m0 : 36|1@1+ (1,0) [0|1] "" Vector__XXX
 SG_ HVP_w034_cpMismatchFault m0 : 37|1@1+ (1,0) [0|1] "" Vector__XXX
 SG_ HVP_w035_packContHwFault m0 : 38|1@1+ (1,0) [0|1] "" Vector__XXX
 SG_ HVP_w036_pyroFuseBlown m0 : 39|1@1+ (1,0) [0|1] "" Vector__XXX
 SG_ HVP_w037_pyroFuseFailedToBlow m0 : 40|1@1+ (1,0) [0|1] "" Vector__XXX
 SG_ HVP_w038_CpilFault m0 : 41|1@1+ (1,0) [0|1] "" Vector__XXX
 SG_ HVP_w039_PackContactorFellOpen m0 : 42|1@1+ (1,0) [0|1] "" Vector__XXX
 SG_ HVP_w040_FcContactorFellOpen m0 : 43|1@1+ (1,0) [0|1] "" Vector__XXX
 SG_ HVP_w041_packCtrCloseBlocked m0 : 44|1@1+ (1,0) [0|1] "" Vector__XXX
 SG_ HVP_w042_fcCtrCloseBlocked m0 : 45|1@1+ (1,0) [0|1] "" Vector__XXX
 SG_ HVP_w043_packContactorForceOpen m0 : 46|1@1+ (1,0) [0|1] "" Vector__XXX
 SG_ HVP_w044_fcContactorForceOpen m0 : 47|1@1+ (1,0) [0|1] "" Vector__XXX
 SG_ HVP_w045_dcLinkOverVoltage m0 : 48|1@1+ (1,0) [0|1] "" Vector__XXX
 SG_ HVP_w046_shuntOverTemperature m0 : 49|1@1+ (1,0) [0|1] "" Vector__XXX
 SG_ HVP_w047_passivePyroDeploy m0 : 50|1@1+ (1,0) [0|1] "" Vector__XXX
 SG_ HVP_w048_swUnsupportedBmbAsicTyp m0 : 51|1@1+ (1,0) [0|1] "" Vector__XXX
 SG_ HVP_w049_packCtrCloseFailed m0 : 52|1@1+ (1,0) [0|1] "" Vector__XXX
 SG_ HVP_w050_fcCtrCloseFailed m0 : 53|1@1+ (1,0) [0|1] "" Vector__XXX
 SG_ HVP_w051_shuntThermistorMia m0 : 54|1@1+ (1,0) [0|1] "" Vector__XXX
 SG_ HVP_w052_BmbStatusRegError m0 : 55|1@1+ (1,0) [0|1] "" Vector__XXX
 SG_ HVP_w053_hvVoltageSensorRational m0 : 56|1@1+ (1,0) [0|1] "" Vector__XXX
 SG_ HVP_w054_swMissingConfigBlock m0 : 57|1@1+ (1,0) [0|1] "" Vector__XXX
 SG_ HVP_w055_swMissingPartNumber m0 : 58|1@1+ (1,0) [0|1] "" Vector__XXX
 SG_ HVP_w056_contactorFailedToOpen m0 : 59|1@1+ (1,0) [0|1] "" Vector__XXX
 SG_ HVP_w057_BatmanDiagnosticsError m0 : 60|1@1+ (1,0) [0|1] "" Vector__XXX
 SG_ HVP_w058_BmbVrefBad m0 : 61|1@1+ (1,0) [0|1] "" Vector__XXX
 SG_ HVP_w059_BmbVrefWarning m0 : 62|1@1+ (1,0) [0|1] "" Vector__XXX
 SG_ HVP_w060_StackVoltageSense m0 : 63|1@1+ (1,0) [0|1] "" Vector__XXX
 SG_ HVP_w061_ShuntCurrentRationality m1 : 4|1@1+ (1,0) [0|1] "" Vector__XXX
 SG_ HVP_w062_BmbOtpConfigError m1 : 5|1@1+ (1,0) [0|1] "" Vector__XXX
 SG_ HVP_w063_BmbBrickVRationality m1 : 6|1@1+ (1,0) [0|1] "" Vector__XXX
 SG_ HVP_w064_BmbAuxVRationality m1 : 7|1@1+ (1,0) [0|1] "" Vector__XXX
 SG_ HVP_w065_FastOpenVshDetected m1 : 8|1@1+ (1,0) [0|1] "" Vector__XXX
 SG_ HVP_w067_HvilCalNodeMismatch m1 : 10|1@1+ (1,0) [0|1] "" Vector__XXX
 SG_ HVP_w068_shuntUnexpectedThermist m1 : 11|1@1+ (1,0) [0|1] "" Vector__XXX
 SG_ HVP_w069_hviCanFrameRxDropped m1 : 12|1@1+ (1,0) [0|1] "" Vector__XXX
 SG_ HVP_w070_hvsCanFrameRxDropped m1 : 13|1@1+ (1,0) [0|1] "" Vector__XXX
 SG_ HVP_w071_PassivePyroVrefRational m1 : 14|1@1+ (1,0) [0|1] "" Vector__XXX

BO_ 522 HVP_contactorState: 6 HVP
 SG_ HVP_packContNegativeState : 0|3@1+ (1,0) [1|7] "" Vector__XXX
 SG_ HVP_packContPositiveState : 3|3@1+ (1,0) [1|7] "" Vector__XXX
 SG_ HVP_fcContPositiveAuxOpen : 6|1@1+ (1,0) [0|1] "" Vector__XXX
 SG_ HVP_fcContNegativeAuxOpen : 7|1@1+ (1,0) [0|1] "" Vector__XXX
 SG_ HVP_packContactorSetState : 8|4@1+ (1,0) [1|15] "" Vector__XXX
 SG_ HVP_fcContNegativeState : 12|3@1+ (1,0) [1|7] "" Vector__XXX
 SG_ HVP_contactorsBlocked : 15|1@1+ (1,0) [0|1] "" Vector__XXX
 SG_ HVP_fcContPositiveState : 16|3@1+ (1,0) [1|7] "" Vector__XXX
 SG_ HVP_fcContactorSetState : 19|4@1+ (1,0) [1|15] "" Vector__XXX
 SG_ HVP_fcCtrsRequestStatus : 24|2@1+ (1,0) [0|3] "" Vector__XXX
 SG_ HVP_fcCtrsResetRequestRequired : 26|1@1+ (1,0) [0|1] "" Vector__XXX
 SG_ HVP_fcCtrsOpenNowRequested : 27|1@1+ (1,0) [0|1] "" Vector__XXX
 SG_ HVP_fcCtrsOpenRequested : 28|1@1+ (1,0) [0|1] "" Vector__XXX
 SG_ HVP_fcCtrsClosingAllowed : 29|1@1+ (1,0) [0|1] "" Vector__XXX
 SG_ HVP_packCtrsRequestStatus : 30|2@1+ (1,0) [0|3] "" Vector__XXX
 SG_ HVP_packCtrsResetRequestRequired : 32|1@1+ (1,0) [0|1] "" Vector__XXX
 SG_ HVP_packCtrsOpenNowRequested : 33|1@1+ (1,0) [0|1] "" Vector__XXX
 SG_ HVP_packCtrsOpenRequested : 34|1@1+ (1,0) [0|1] "" Vector__XXX
 SG_ HVP_packCtrsClosingAllowed : 35|1@1+ (1,0) [0|1] "" Vector__XXX
 SG_ HVP_dcLinkAllowedToEnergize : 36|1@1+ (1,0) [0|1] "" Vector__XXX
 SG_ HVP_pyroTestInProgress : 37|1@1+ (1,0) [0|1] "" Vector__XXX
 SG_ HVP_hvilDiag : 40|4@1+ (1,0) [0|15] "" Vector__XXX
 SG_ HVP_fcLinkAllowedToEnergize : 44|2@1+ (1,0) [0|3] "" Vector__XXX

BO_ 1962 HVP_debugMessage: 8 HVP
 SG_ HVP_debugMessageMultiplexer M : 0|4@1+ (1,0) [0|15] "" Vector__XXX
 SG_ HVP_ecuLogUploadRequest m1 : 4|2@1+ (1,0) [0|3] "" Vector__XXX
 SG_ HVP_dcLinkVoltage m1 : 8|16@1- (0.1,0) [-3276.8|3276.7] "V" Vector__XXX
 SG_ HVP_packVoltage m1 : 24|16@1- (0.1,0) [-3276.8|3276.7] "V" Vector__XXX
 SG_ HVP_fcLinkVoltage m1 : 40|16@1- (0.1,0) [-3276.8|3276.7] "V" Vector__XXX
 SG_ HVP_10HzTask_stackUsage m1 : 56|7@1+ (1,0) [0|100] "%" Vector__XXX
 SG_ HVP_packContVoltage m2 : 4|12@1+ (0.1,0) [0|30] "V" Vector__XXX
 SG_ HVP_packNegativeV m2 : 16|16@1- (0.1,0) [-550|550] "V" Vector__XXX
 SG_ HVP_packPositiveV m2 : 32|16@1- (0.1,0) [-550|550] "V" Vector__XXX
 SG_ HVP_pyroAnalog m2 : 48|12@1+ (0.1,0) [0|3] "V" Vector__XXX
 SG_ HVP_shuntSetTCRCoeffA m2 : 60|1@1+ (1,0) [0|1] "" Vector__XXX
 SG_ HVP_shuntSetTCRCoeffB m2 : 61|1@1+ (1,0) [0|1] "" Vector__XXX
 SG_ HVP_shuntSetTCRCoeffC m2 : 62|1@1+ (1,0) [0|1] "" Vector__XXX
 SG_ HVP_shuntSetTCRCoeffD m2 : 63|1@1+ (1,0) [0|1] "" Vector__XXX
 SG_ HVP_fcContCoilCurrent m4 : 4|12@1+ (0.1,0) [0|7.5] "A" Vector__XXX
 SG_ HVP_fcContVoltage m4 : 16|12@1+ (0.1,0) [0|30] "V" Vector__XXX
 SG_ HVP_hvilInVoltage m4 : 28|12@1+ (0.1,0) [0|30] "V" Vector__XXX
 SG_ HVP_hvilOutVoltage m4 : 40|12@1+ (0.1,0) [0|30] "V" Vector__XXX
 SG_ HVP_shuntGainInvalidCountDbg m4 : 56|8@1+ (1,0) [0|255] "counts" Vector__XXX
 SG_ HVP_passivePyroRefVoltageMax m5 : 4|10@1+ (0.001,0.7) [0.7|1.722] "V" Vector__XXX
 SG_ HVP_passivePyroRefVoltageMin m5 : 14|10@1+ (0.001,0.7) [0.7|1.722] "V" Vector__XXX
 SG_ HVP_packContCoilCurrent m5 : 24|12@1+ (0.1,0) [0|7.5] "A" Vector__XXX
 SG_ HVP_battery12V m5 : 36|12@1+ (0.1,0) [0|30] "V" Vector__XXX
 SG_ HVP_fcLinkPositiveV m5 : 48|16@1- (0.1,0) [-550|550] "V" Vector__XXX

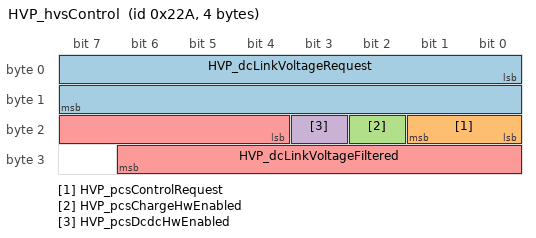
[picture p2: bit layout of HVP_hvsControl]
BO_ 554 HVP_hvsControl: 4 HVP
 SG_ HVP_dcLinkVoltageRequest : 0|16@1- (0.1,0) [-550|550] "V" Vector__XXX
 SG_ HVP_pcsControlRequest : 16|2@1+ (1,0) [0|3] "" Vector__XXX
 SG_ HVP_pcsChargeHwEnabled : 18|1@1+ (1,0) [0|1] "" Vector__XXX
 SG_ HVP_pcsDcdcHwEnabled : 19|1@1+ (1,0) [0|1] "" Vector__XXX
 SG_ HVP_dcLinkVoltageFiltered : 20|11@1- (1,0) [-550|550] "V" Vector__XXX

BO_ 784 HVP_info: 8 HVP
 SG_ HVP_infoIndex M : 0|8@1+ (1,0) [0|255] "" Vector__XXX
 SG_ HVP_buildType m10 : 8|3@1+ (1,0) [0|7] "" Vector__XXX
 SG_ HVP_buildConfigId m10 : 16|16@1+ (1,0) [0|65535] "" Vector__XXX
 SG_ HVP_hardwareId m10 : 32|16@1+ (1,0) [0|65535] "" Vector__XXX
 SG_ HVP_componentId m10 : 48|16@1+ (1,0) [0|65535] "" Vector__XXX
 SG_ HVP_pcbaId m11 : 16|8@1+ (1,0) [0|255] "" Vector__XXX
 SG_ HVP_assemblyId m11 : 24|8@1+ (1,0) [0|255] "" Vector__XXX
 SG_ HVP_usageId m11 : 32|16@1+ (1,0) [0|65535] "" Vector__XXX
 SG_ HVP_subUsageId m11 : 48|16@1+ (1,0) [0|65535] "" Vector__XXX
 SG_ HVP_platformType m13 : 8|8@1+ (1,0) [0|255] "" Vector__XXX
 SG_ HVP_appCrc m13 : 32|32@1+ (1,0) [0|4294967295] "" Vector__XXX
 SG_ HVP_appGitHash m17 : 8|56@1+ (1,0) [0|7.20575940379e+16] "" Vector__XXX
 SG_ HVP_bootGitHash m18 : 8|56@1+ (1,0) [0|7.20575940379e+16] "" Vector__XXX
 SG_ HVP_bootUdsProtoVersion m20 : 8|8@1+ (1,0) [0|255] "" Vector__XXX
 SG_ HVP_bootCrc m20 : 32|32@1+ (1,0) [0|4294967295] "" Vector__XXX

BO_TX_BU_ 1000 : EPBR;
BO_TX_BU_ 2024 : EPBR;
BO_TX_BU_ 552 : EPBR;
BO_TX_BU_ 742 : EPBR;
BO_TX_BU_ 744 : EPBR;
BO_TX_BU_ 1662 : EVSE;
BO_TX_BU_ 1322 : FC;
BO_TX_BU_ 895 : FC;
BO_TX_BU_ 927 : FC;
BO_TX_BU_ 958 : FC;
BO_TX_BU_ 990 : FC;
BO_TX_BU_ 1117 : FC;
BO_TX_BU_ 1334 : FC;
BO_TX_BU_ 1303 : FC;
BO_TX_BU_ 1310 : FC;
BO_TX_BU_ 580 : FC;
BO_TX_BU_ 702 : FC;
BO_TX_BU_ 1345 : FC;
BO_TX_BU_ 1300 : FC;
BO_TX_BU_ 532 : FC;
BO_TX_BU_ 533 : FC;
BO_TX_BU_ 535 : FC;
BO_TX_BU_ 1650 : HCML;
BO_TX_BU_ 1980 : HCMR;
BO_TX_BU_ 1290 : HVP;
BO_TX_BU_ 938 : HVP;
BO_TX_BU_ 522 : HVP;
BO_TX_BU_ 1962 : HVP;
BO_TX_BU_ 554 : HVP;
BO_TX_BU_ 784 : HVP;
CM_ BO_ 1000 "Right electric parking brake message: alert matrix; frame length observed on a vehicle bus";
CM_ SG_ 1000 EPBR_matrixIndex "Right electric parking brake: matrix index";
CM_ SG_ 1000 EPBR_a001_WatchdogReset "Right electric parking brake: a001 watchdog reset";
CM_ SG_ 1000 EPBR_a002_PowerLossReset "Right electric parking brake: a002 power loss reset";
CM_ SG_ 1000 EPBR_a003_SWAssertion "Right electric parking brake: a003 SW assertion";
CM_ SG_ 1000 EPBR_a005_CANTXError "Right electric parking brake: a005 CANTX error";
CM_ SG_ 1000 EPBR_a006_CANTX_cyclicError "Right electric parking brake: a006 CANTX cyclic error";
CM_ SG_ 1000 EPBR_a012_CPUReset "Right electric parking brake: a012 CPU reset";
CM_ SG_ 1000 EPBR_a013_AlertManagerFault "Right electric parking brake: a013 alert manager fault";
CM_ SG_ 1000 EPBR_a015_NVMMError "Right electric parking brake: a015 NVMM error";
CM_ SG_ 1000 EPBR_a016_NVMMRecordError "Right electric parking brake: a016 NVMM record error";
CM_ SG_ 1000 EPBR_a021_TaskSchedulerError "Right electric parking brake: a021 task scheduler error";
CM_ SG_ 1000 EPBR_a022_TaskInitError "Right electric parking brake: a022 task init error";
CM_ SG_ 1000 EPBR_a029_CoreDump "Right electric parking brake: a029 core dump";
CM_ SG_ 1000 EPBR_a030_ECULogUploadRequest "Right electric parking brake: a030 ECU log upload request";
CM_ SG_ 1000 EPBR_a031_UDSActive "Right electric parking brake: a031 UDS active";
CM_ SG_ 1000 EPBR_a041_HighCPULoad "Right electric parking brake: a041 high CPU load";
CM_ SG_ 1000 EPBR_a042_HighStackUsage "Right electric parking brake: a042 high stack usage";
CM_ SG_ 1000 EPBR_a043_Task1msError "Right electric parking brake: a043 task1ms error";
CM_ SG_ 1000 EPBR_a044_Task10msError "Right electric parking brake: a044 task10ms error";
CM_ SG_ 1000 EPBR_a045_Task100msError "Right electric parking brake: a045 task100ms error";
CM_ SG_ 1000 EPBR_a046_Task1000msError "Right electric parking brake: a046 task1000ms error";
CM_ SG_ 1000 EPBR_a057_HVP_MIA "Right electric parking brake: a057 HVP MIA";
CM_ SG_ 1000 EPBR_a058_inputRHighSyncDebug "Right electric parking brake: a058 input r high sync debug";
CM_ SG_ 1000 EPBR_a059_inputResistanceHigh "Right electric parking brake: a059 input resistance high";
CM_ SG_ 1000 EPBR_a060_engineeringBuild "Right electric parking brake: a060 engineering build";
CM_ SG_ 1000 EPBR_a061_XCPConnected "Right electric parking brake: a061 XCP connected";
CM_ SG_ 1000 EPBR_a062_XCPWasConnected "Right electric parking brake: a062 XCP was connected";
CM_ SG_ 1000 EPBR_a063_SwitchFault "Right electric parking brake: a063 switch fault";
CM_ SG_ 1000 EPBR_a064_busSleepReqTimeout "Right electric parking brake: a064 bus sleep req timeout";
CM_ SG_ 1000 EPBR_a081_APP_MIA "Right electric parking brake: a081 APP MIA";
CM_ SG_ 1000 EPBR_a082_VCRIGHT_IPC_MIA "Right electric parking brake: a082 VCRIGHT IPC MIA";
CM_ SG_ 1000 EPBR_a083_VCLEFT_IPC_MIA "Right electric parking brake: a083 VCLEFT IPC MIA";
CM_ SG_ 1000 EPBR_a084_TPMS_MIA "Right electric parking brake: a084 TPMS MIA";
CM_ SG_ 1000 EPBR_a085_CCCM_MIA "Right electric parking brake: a085 CCCM MIA";
CM_ SG_ 1000 EPBR_a086_VCBATT_MIA "Right electric parking brake: a086 VCBATT MIA";
CM_ SG_ 1000 EPBR_a087_DIREL_MIA "Right electric parking brake: a087 DIREL MIA";
CM_ SG_ 1000 EPBR_a088_DIRER_MIA "Right electric parking brake: a088 DIRER MIA";
CM_ SG_ 1000 EPBR_a089_IBST_MIA "Right electric parking brake: a089 IBST MIA";
CM_ SG_ 1000 EPBR_a090_APS_MIA "Right electric parking brake: a090 APS MIA";
CM_ SG_ 1000 EPBR_a091_CMPD_MIA "Right electric parking brake: a091 CMPD MIA";
CM_ SG_ 1000 EPBR_a092_VCSEATD_MIA "Right electric parking brake: a092 VCSEATD MIA";
CM_ SG_ 1000 EPBR_a093_VCSEATP_MIA "Right electric parking brake: a093 VCSEATP MIA";
CM_ SG_ 1000 EPBR_a094_EPAS3P_MIA "Right electric parking brake: a094 EPAS3 p MIA";
CM_ SG_ 1000 EPBR_a095_CHG_MIA "Right electric parking brake: a095 CHG MIA";
CM_ SG_ 1000 EPBR_a096_OCS1P_MIA "Right electric parking brake: a096 OCS1 p MIA";
CM_ SG_ 1000 EPBR_a097_CMP_MIA "Right electric parking brake: a097 CMP MIA";
CM_ SG_ 1000 EPBR_a098_DIR_MIA "Right electric parking brake: a098 DIR MIA";
CM_ SG_ 1000 EPBR_a099_PARK_MIA "Right electric parking brake: a099 PARK MIA";
CM_ SG_ 1000 EPBR_a100_CANbus_MIA "Right electric parking brake: a100 CA nbus MIA";
CM_ SG_ 1000 EPBR_a101_PM_MIA "Right electric parking brake: a101 PM MIA";
CM_ SG_ 1000 EPBR_a102_PTC_MIA "Right electric parking brake: a102 PTC MIA";
CM_ SG_ 1000 EPBR_a103_CP_MIA "Right electric parking brake: a103 CP MIA";
CM_ SG_ 1000 EPBR_a104_DAS_MIA "Right electric parking brake: a104 DAS MIA";
CM_ SG_ 1000 EPBR_a105_TAS_MIA "Right electric parking brake: a105 TAS MIA";
CM_ SG_ 1000 EPBR_a106_PCS_MIA "Right electric parking brake: a106 PCS MIA";
CM_ SG_ 1000 EPBR_a107_BMS_MIA "Right electric parking brake: a107 BMS MIA";
CM_ SG_ 1000 EPBR_a108_DIF_MIA "Right electric parking brake: a108 DIF MIA";
CM_ SG_ 1000 EPBR_a109_RCM_MIA "Right electric parking brake: a109 RCM MIA";
CM_ SG_ 1000 EPBR_a110_GTW_MIA "Right electric parking brake: a110 GTW MIA";
CM_ SG_ 1000 EPBR_a111_EPBR_MIA "Right electric parking brake: a111 EPBR MIA";
CM_ SG_ 1000 EPBR_a112_EPBL_MIA "Right electric parking brake: a112 EPBL MIA";
CM_ SG_ 1000 EPBR_a113_UI_MIA "Right electric parking brake: a113 UI MIA";
CM_ SG_ 1000 EPBR_a114_ESP_MIA "Right electric parking brake: a114 ESP MIA";
CM_ SG_ 1000 EPBR_a115_VCSEC_MIA "Right electric parking brake: a115 VCSEC MIA";
CM_ SG_ 1000 EPBR_a116_VCRIGHT_MIA "Right electric parking brake: a116 VCRIGHT MIA";
CM_ SG_ 1000 EPBR_a117_VCLEFT_MIA "Right electric parking brake: a117 VCLEFT MIA";
CM_ SG_ 1000 EPBR_a118_VCFRONT_MIA "Right electric parking brake: a118 VCFRONT MIA";
CM_ SG_ 1000 EPBR_a119_SCCM_MIA "Right electric parking brake: a119 SCCM MIA";
CM_ SG_ 1000 EPBR_a120_DI_DRIVE_MIA "Right electric parking brake: a120 DI DRIVE MIA";
CM_ SG_ 1000 EPBR_a121_nDriveFault "Right electric parking brake: a121 n drive fault";
CM_ SG_ 1000 EPBR_a122_Oc "Right electric parking brake: a122 oc";
CM_ SG_ 1000 EPBR_a123_Uc "Right electric parking brake: a123 uc";
CM_ SG_ 1000 EPBR_a124_calOutOfBounds "Right electric parking brake: a124 cal out of bounds";
CM_ SG_ 1000 EPBR_a125_IdleVMismatch "Right electric parking brake: a125 idle v mismatch";
CM_ SG_ 1000 EPBR_a126_MotorNVoltLow "Right electric parking brake: a126 motor n volt low";
CM_ SG_ 1000 EPBR_a127_MotorNVoltHigh "Right electric parking brake: a127 motor n volt high";
CM_ SG_ 1000 EPBR_a128_MotorPVoltHigh "Right electric parking brake: a128 motor p volt high";
CM_ SG_ 1000 EPBR_a129_ICR_MIA "Right electric parking brake: a129 ICR MIA";
CM_ SG_ 1000 EPBR_a130_BB_MIA "Right electric parking brake: a130 BB MIA";
CM_ SG_ 1000 EPBR_a131_RCU_MIA "Right electric parking brake: a131 RCU MIA";
CM_ SG_ 1000 EPBR_a132_VCBATT1_MIA "Right electric parking brake: a132 VCBATT1 MIA";
CM_ SG_ 1000 EPBR_a133_VCBATT2_MIA "Right electric parking brake: a133 VCBATT2 MIA";
CM_ SG_ 1000 EPBR_a134_NvOv "Right electric parking brake: a134 nv ov";
CM_ SG_ 1000 EPBR_a135_NvUv "Right electric parking brake: a135 nv uv";
CM_ SG_ 1000 EPBR_a136_PvOv "Right electric parking brake: a136 pv ov";
CM_ SG_ 1000 EPBR_a137_PvUv "Right electric parking brake: a137 pv uv";
CM_ SG_ 1000 EPBR_a138_NvmDualFailure "Right electric parking brake: a138 nvm dual failure";
CM_ SG_ 1000 EPBR_a139_NvmRedundancyLoss "Right electric parking brake: a139 nvm redundancy loss";
CM_ SG_ 1000 EPBR_a140_NvmSlowWrite "Right electric parking brake: a140 nvm slow write";
CM_ SG_ 1000 EPBR_a141_invalidState "Right electric parking brake: a141 invalid state";
CM_ SG_ 1000 EPBR_a170_12vOv "Right electric parking brake: a170 12v ov";
CM_ SG_ 1000 EPBR_a171_12vUv "Right electric parking brake: a171 12v uv";
CM_ SG_ 1000 EPBR_a172_SPI_MIA "Right electric parking brake: a172 SPI MIA";
CM_ SG_ 1000 EPBR_a173_hiCurrentMissing "Right electric parking brake: a173 hi current missing";
CM_ SG_ 1000 EPBR_a174_csmReleaseFailed "Right electric parking brake: a174 csm release failed";
CM_ SG_ 1000 EPBR_a175_csmReleaseRetry "Right electric parking brake: a175 csm release retry";
CM_ SG_ 1000 EPBR_a176_csmApplyFailed "Right electric parking brake: a176 csm apply failed";
CM_ SG_ 1000 EPBR_a177_csmApplyRetry "Right electric parking brake: a177 csm apply retry";
CM_ SG_ 1000 EPBR_a178_caliperStateUnknown "Right electric parking brake: a178 caliper state unknown";
CM_ SG_ 1000 EPBR_a179_epbProblem "Right electric parking brake: a179 epb problem";
CM_ SG_ 1000 EPBR_a180_dynamicActive "Right electric parking brake: a180 dynamic active";
CM_ SG_ 1000 EPBR_a181_TooSteepGradeToPark "Right electric parking brake: a181 too steep grade to park";
CM_ SG_ 1000 EPBR_a182_OneEPBAppliedUnsecEnv "Right electric parking brake: a182 one EPB applied unsec env";
CM_ SG_ 1000 EPBR_a183_cdpNotAvailable "Right electric parking brake: a183 cdp not available";
CM_ SG_ 1000 EPBR_a184_dynamicParkAbort "Right electric parking brake: a184 dynamic park abort";
CM_ SG_ 1000 EPBR_a185_summonAborted "Right electric parking brake: a185 summon aborted";
CM_ SG_ 1000 EPBR_a186_externalParkAbort "Right electric parking brake: a186 external park abort";
CM_ SG_ 1000 EPBR_a187_cdpDynamic "Right electric parking brake: a187 cdp dynamic";
CM_ SG_ 1000 EPBR_a188_epbDynamic "Right electric parking brake: a188 epb dynamic";
CM_ SG_ 1000 EPBR_a189_epbDynamicParkCanceled "Right electric parking brake: a189 epb dynamic park canceled";
CM_ SG_ 1000 EPBR_a190_csmApplyDegraded "Right electric parking brake: a190 csm apply degraded";
CM_ SG_ 1000 EPBR_a191_csmReleaseDegraded "Right electric parking brake: a191 csm release degraded";
CM_ SG_ 1000 EPBR_a195_parkForDriverIsLeaving "Right electric parking brake: a195 park for driver is leaving";
CM_ SG_ 1000 EPBR_a196_freeRollModeActive "Right electric parking brake: a196 free roll mode active";
CM_ SG_ 1000 EPBR_a197_freeRollModeAtSpeed "Right electric parking brake: a197 free roll mode at speed";
CM_ SG_ 1000 EPBR_a198_holdClampComplete "Right electric parking brake: a198 hold clamp complete";
CM_ SG_ 1000 EPBR_a200_PmUnparkNotAllowed "Right electric parking brake: a200 pm unpark not allowed";
CM_ SG_ 1000 EPBR_a202_remoteEpbConfigIncompa "Right electric parking brake: a202 remote epb config incompatible";
CM_ SG_ 1000 EPBR_a203_hwBrakeTypeMismatch "Right electric parking brake: a203 hw brake type mismatch";
CM_ SG_ 1000 EPBR_a210_parkForDriverIsLeaving "Right electric parking brake: a210 park for driver is leaving debug";
CM_ SG_ 1000 EPBR_a216_SPI_MIA_debugData1 "Right electric parking brake: a216 SPI MIA debug data1";
CM_ SG_ 1000 EPBR_a217_SPI_MIA_debugData2 "Right electric parking brake: a217 SPI MIA debug data2";
CM_ SG_ 1000 EPBR_a225_epbActiveDecel "Right electric parking brake: a225 epb active decel";
CM_ SG_ 1000 EPBR_a241_diOutputLocked "Right electric parking brake: a241 di output locked";
CM_ SG_ 1000 EPBR_a242_hvOutputLocked "Right electric parking brake: a242 hv output locked";
CM_ SG_ 1000 EPBR_a243_bdwUnavailable "Right electric parking brake: a243 bdw unavailable";
CM_ SG_ 1000 EPBR_a244_WinchModeActive "Right electric parking brake: a244 winch mode active";
CM_ SG_ 1000 EPBR_a245_serviceModeActive "Signal reported by Right electric parking brake";
CM_ SG_ 1000 EPBR_a246_idleFaultApply "Right electric parking brake: a246 idle fault apply";
CM_ SG_ 1000 EPBR_a247_csmDynamicApplyRetry "Right electric parking brake: a247 csm dynamic apply retry";
CM_ SG_ 1000 EPBR_a248_csmDynamicApplyFailed "Right electric parking brake: a248 csm dynamic apply failed";
CM_ SG_ 1000 EPBR_a249_idleFaultRelease "Right electric parking brake: a249 idle fault release";
CM_ SG_ 1000 EPBR_a250_WinchModeCanceled "Right electric parking brake: a250 winch mode canceled";
CM_ SG_ 1000 EPBR_a251_currentVarianceHigh "Right electric parking brake: a251 current variance high";
CM_ SG_ 1000 EPBR_a252_winchModePending "Right electric parking brake: a252 winch mode pending";
CM_ SG_ 1000 EPBR_a253_esmReleaseBlocked "Right electric parking brake: a253 esm release blocked";
CM_ SG_ 1000 EPBR_a254_showStalkParkButtonFau "Right electric parking brake: a254 show stalk park button fault on ui";
CM_ SG_ 1000 EPBR_a256_epbSystemApply "Right electric parking brake: a256 epb system apply";
CM_ SG_ 1000 EPBR_a261_winchModeWithoutSteeri "Right electric parking brake: a261 winch mode without steering";
CM_ SG_ 1000 EPBR_a262_cannotPrepareWinchMode "Right electric parking brake: a262 cannot prepare winch mode";
CM_ SG_ 1000 EPBR_a263_epbRecoveryPark "Right electric parking brake: a263 epb recovery park";
CM_ SG_ 1000 EPBR_a264_winchModeDeactivated "Right electric parking brake: a264 winch mode deactivated";
CM_ SG_ 1000 EPBR_a272_vhclPwrStateMsmtch "Right electric parking brake: a272 vhcl pwr state msmtch";
CM_ SG_ 1000 EPBR_a300_leftRightConfusion "Right electric parking brake: a300 left right confusion";
CM_ SG_ 1000 EPBR_a301_oocSpeedViolation "Right electric parking brake: a301 ooc speed violation";
CM_ SG_ 1000 EPBR_a302_csmLongRelease "Right electric parking brake: a302 csm long release";
CM_ SG_ 1000 EPBR_a303_clampingOccuredEarly "Right electric parking brake: a303 clamping occured early";
CM_ SG_ 1000 EPBR_a304_rearSeatControllerEFus "Right electric parking brake: a304 rear seat controller e fuse trip";
CM_ SG_ 1000 EPBR_a305_premiumAmpEFuseTrip "Right electric parking brake: a305 premium amp e fuse trip";
CM_ SG_ 1000 EPBR_a330_parkForApIsLeaving "Right electric parking brake: a330 park for ap is leaving";
CM_ SG_ 1000 EPBR_a350_ensOutOfRange "Right electric parking brake: a350 ens out of range";
CM_ SG_ 1000 EPBR_a352_audioCurrentSpikeData "Right electric parking brake: a352 audio current spike data";
CM_ SG_ 1000 EPBR_a353_missingSpeedUnableToPa "Right electric parking brake: a353 missing speed unable to park";
CM_ SG_ 1000 EPBR_a354_parkedForLowBrakeFluid "Right electric parking brake: a354 parked for low brake fluid mode";
CM_ SG_ 1000 EPBR_a355_brakeHwAndEpbHwMismatc "Right electric parking brake: a355 brake hw and epb hw mismatch";
CM_ SG_ 1000 EPBR_a356_parkingForStationaryDe "Right electric parking brake: a356 parking for stationary detect";
CM_ SG_ 1000 EPBR_a357_brakesTooHotForSlope "Right electric parking brake: a357 brakes too hot for slope";
CM_ SG_ 1000 EPBR_a358_brakesTooHotForSlopeWi "Right electric parking brake: a358 brakes too hot for slope with only one epb";
CM_ SG_ 1000 EPBR_a359_seat2RControllerTrip "Right electric parking brake: a359 seat2 r controller trip";
CM_ SG_ 1000 EPBR_a360_ibstBrakeSwitchInvalid "Right electric parking brake: a360 ibst brake switch invalid";
CM_ SG_ 1000 EPBR_a361_espBrakeSwitchInvalid "Right electric parking brake: a361 esp brake switch invalid";
CM_ SG_ 1000 EPBR_a362_ibstPressedEspNotPress "Right electric parking brake: a362 ibst pressed esp not pressed mismatch";
CM_ SG_ 1000 EPBR_a363_ibstNotPressedEspPress "Right electric parking brake: a363 ibst not pressed esp pressed mismatch";
CM_ SG_ 1000 EPBR_a364_espMasterCylCompOverTh "Right electric parking brake: a364 esp master cyl comp over threshold";
CM_ SG_ 1000 EPBR_a365_TooSteepToParkWithTrai "Right electric parking brake: a365 too steep to park with trailer warning";
CM_ SG_ 1000 EPBR_a366_TooSteepToParkWithTrai "Right electric parking brake: a366 too steep to park with trailer un sec env";
CM_ SG_ 1000 EPBR_a370_imposterDetected "Right electric parking brake: a370 imposter detected";
CM_ BO_ 2024 "Right electric parking brake message: info; frame length observed on a vehicle bus";
CM_ SG_ 2024 EPBR_infoIndex "Right electric parking brake: info index";
CM_ SG_ 2024 EPBR_infoBuildType "Right electric parking brake: info build type";
CM_ SG_ 2024 EPBR_infoBuildConfigId "Right electric parking brake: info build config id";
CM_ SG_ 2024 EPBR_infoHardwareId "Right electric parking brake: info hardware id";
CM_ SG_ 2024 EPBR_infoComponentId "Right electric parking brake: info component id";
CM_ SG_ 2024 EPBR_infoPcbaId "Right electric parking brake: info pcba id";
CM_ SG_ 2024 EPBR_infoAssemblyId "Right electric parking brake: info assembly id; raw 255 = signal not available (SNA)";
CM_ SG_ 2024 EPBR_infoUsageId "Right electric parking brake: info usage id";
CM_ SG_ 2024 EPBR_infoSubUsageId "Right electric parking brake: info sub usage id";
CM_ SG_ 2024 EPBR_infoAppCrc "Right electric parking brake: info app crc";
CM_ SG_ 2024 EPBR_infoAppGitHash "Right electric parking brake: info app git hash";
CM_ SG_ 2024 EPBR_infoBootGitHash "Right electric parking brake: info boot git hash";
CM_ SG_ 2024 EPBR_infoPlatformType "Right electric parking brake: info platform type";
CM_ SG_ 2024 EPBR_infoBootUdsProtoVersion "Right electric parking brake: info boot uds proto version";
CM_ SG_ 2024 EPBR_infoBootCrc "Right electric parking brake: info boot crc";
CM_ BO_ 552 "Right electric parking brake message: internal status; frame length observed on a vehicle bus";
CM_ SG_ 552 EPBR_unitStatus "Electronic Parking Brake's unit state.";
CM_ SG_ 552 EPBR_unitFaultStatus "Right electric parking brake: unit fault status";
CM_ SG_ 552 EPBR_summonState "Right electric parking brake: summon state";
CM_ SG_ 552 EPBR_disconnected "Right electric parking brake: disconnected";
CM_ SG_ 552 EPBR_pistonTouchingRotor "Right electric parking brake: piston touching rotor";
CM_ SG_ 552 EPBR_csmFaultReason "Right electric parking brake: csm fault reason";
CM_ SG_ 552 EPBR_esmOperationTrigger "Right electric parking brake: esm operation trigger";
CM_ SG_ 552 EPBR_summonFaultReason "Error code associated with previous summon failure.";
CM_ SG_ 552 EPBR_localServiceModeActive "Signal reported by Right electric parking brake";
CM_ SG_ 552 EPBR_localCdpState "Right electric parking brake: local cdp state";
CM_ SG_ 552 EPBR_chimeRequestLocal "Right electric parking brake: chime request local";
CM_ SG_ 552 EPBR_telltaleLocal "Right electric parking brake: telltale local; raw 7 = signal not available (SNA)";
CM_ SG_ 552 EPBR_driverIsLeavingLocal "Right electric parking brake: driver is leaving local";
CM_ SG_ 552 EPBR_driverIsLeavingAnySpeedLoca "Right electric parking brake: driver is leaving any speed local";
CM_ SG_ 552 EPBR_internalCDPRequest "Right electric parking brake: internal CDP request";
CM_ SG_ 552 EPBR_esmSpeedClass "Right electric parking brake: esm speed class";
CM_ SG_ 552 EPBR_learnedEpbConfig "Right electric parking brake: learned epb config";
CM_ SG_ 552 EPBR_internalStatusCounter "Right electric parking brake: internal status counter";
CM_ SG_ 552 EPBR_internalStatusChecksum "Right electric parking brake: internal status checksum";
CM_ BO_ 742 "Right electric parking brake message: seat status3; frame length from the layout, not yet observed on a vehicle bus";
CM_ SG_ 742 EPBR_frontSeatCushionFanCur "Right electric parking brake: front seat cushion fan cur";
CM_ SG_ 742 EPBR_frontSeatBackrestFanCur "Right electric parking brake: front seat backrest fan cur";
CM_ SG_ 742 EPBR_frontSeatCushionFanDuty "Right electric parking brake: front seat cushion fan duty";
CM_ SG_ 742 EPBR_frontSeatCushionFanEn "Right electric parking brake: front seat cushion fan en";
CM_ SG_ 742 EPBR_frontSeatBackrestFanEn "Right electric parking brake: front seat backrest fan en";
CM_ SG_ 742 EPBR_frontSeatBackrestFanDuty "Right electric parking brake: front seat backrest fan duty";
CM_ SG_ 742 EPBR_seat2RControllerCurrent "Right electric parking brake: seat2 r controller current";
CM_ BO_ 744 "Right electric parking brake message: status; frame length observed on a vehicle bus";
CM_ SG_ 744 EPBR_systemStatus "Coordinated state representing the vehicle level parking brake state.";
CM_ SG_ 744 EPBR_freeRollModeStatus "Right electric parking brake: free roll mode status";
CM_ SG_ 744 EPBR_driverIsLeaving "Right electric parking brake: driver is leaving";
CM_ SG_ 744 EPBR_driverIsLeavingAnySpeed "Right electric parking brake: driver is leaving any speed";
CM_ SG_ 744 EPBR_systemCdpAvailable "Right electric parking brake: system cdp available";
CM_ SG_ 744 EPBR_chimeRequest "Right electric parking brake: chime request";
CM_ SG_ 744 EPBR_telltale "Controls the telltale illumination on the instrument cluster; raw 7 = signal not available (SNA)";
CM_ SG_ 744 EPBR_audioCurrentSpikeDetected "Right electric parking brake: audio current spike detected";
CM_ SG_ 744 EPBR_redundantBrakingEnabled "Right electric parking brake: redundant braking enabled";
CM_ SG_ 744 EPBR_summonEnabled "Right electric parking brake: summon enabled";
CM_ SG_ 744 EPBR_brakeLight "Right electric parking brake: brake light";
CM_ SG_ 744 EPBR_epbConfigMismatch "Right electric parking brake: epb config mismatch";
CM_ SG_ 744 EPBR_brakeConfirmedPressed "Right electric parking brake: brake confirmed pressed";
CM_ SG_ 744 EPBR_requestUserConfirmation "Right electric parking brake: request user confirmation";
CM_ SG_ 744 EPBR_uiWinchModeMiscBlocking "Reports the expected appearance of system error message on User Interface (UI) winch mode panel.";
CM_ SG_ 744 EPBR_winchModeActive "Right electric parking brake: winch mode active";
CM_ SG_ 744 EPBR_updateMode "Right electric parking brake: update mode";
CM_ SG_ 744 EPBR_winchModePermissive "Right electric parking brake: winch mode permissive";
CM_ SG_ 744 EPBR_winchModePending "Right electric parking brake: winch mode pending";
CM_ SG_ 744 EPBR_cdpRequest "Right electric parking brake: cdp request";
CM_ SG_ 744 EPBR_uiParkAvailable "Reports the expected availability and appearance of the park button on User Interface (UI) safety panel.";
CM_ SG_ 744 EPBR_brakeDiscWipeRequest "Right electric parking brake: brake disc wipe request; raw 3 = signal not available (SNA)";
CM_ SG_ 744 EPBR_showUiGearShifter "Right electric parking brake: show ui gear shifter";
CM_ SG_ 744 EPBR_uiWinchModeLvStatus "Reports the expected availability and appearance of Low Voltage (LV) system status on UI winch mode panel.";
CM_ SG_ 744 EPBR_contactorCycleNotNeededForW "Right electric parking brake: contactor cycle not needed for winch entry";
CM_ SG_ 744 EPBR_autonomyBehavior "Right electric parking brake: autonomy behavior";
CM_ SG_ 744 EPBR_showStalkFaultedOnUi "Right electric parking brake: show stalk faulted on ui";
CM_ SG_ 744 EPBR_espPowerRequest "Right electric parking brake: esp power request";
CM_ SG_ 744 EPBR_okToPark "Right electric parking brake: ok to park";
CM_ SG_ 744 EPBR_hornRequest "Right electric parking brake: horn request";
CM_ SG_ 744 EPBR_winchModeAvailable "Right electric parking brake: winch mode available";
CM_ SG_ 744 EPBR_bothDisconnected "Right electric parking brake: both disconnected";
CM_ SG_ 744 EPBR_blockDrive "Right electric parking brake: block drive";
CM_ SG_ 744 EPBR_statusCounter "Right electric parking brake: status counter";
CM_ SG_ 744 EPBR_statusChecksum "Right electric parking brake: status checksum";
CM_ BO_ 1662 "EVSE ECU message: iso tp to veh; frame length from the layout, not yet observed on a vehicle bus";
CM_ SG_ 1662 EVSE_isoTpToVehData "EVSE ECU: iso tp to veh data";
CM_ BO_ 1322 "FC ECU message: alert log; frame length from the layout, not yet observed on a vehicle bus";
CM_ SG_ 1322 FC_alertID "FC ECU: alert ID";
CM_ SG_ 1322 FC_alertType "FC ECU: alert type";
CM_ SG_ 1322 FC_a130_CA_flybackSwOvType "FC ECU: a130 CA flyback sw ov type";
CM_ SG_ 1322 FC_a146_CA_flybackOnTime "FC ECU: a146 CA flyback on time";
CM_ SG_ 1322 FC_a146_CA_flybackV "FC ECU: a146 CA flyback v";
CM_ SG_ 1322 FC_a146_CA_flybackTargetV "FC ECU: a146 CA flyback target v";
CM_ SG_ 1322 FC_a159_CA_wdtTaskList1 "FC ECU: a159 CA wdt task list1";
CM_ SG_ 1322 FC_a159_CA_wdtTaskList2 "FC ECU: a159 CA wdt task list2";
CM_ BO_ 895 "FC ECU message: alert matrix3; frame length from the layout, not yet observed on a vehicle bus";
CM_ SG_ 895 FC_a129_CA_flyback_HW_OC "FC ECU: a129 CA flyback HW OC";
CM_ SG_ 895 FC_a130_CA_flyback_SW_OV "FC ECU: a130 CA flyback SW OV";
CM_ SG_ 895 FC_a131_CA_flyback_HW_OV "FC ECU: a131 CA flyback HW OV";
CM_ SG_ 895 FC_a132_CA_bmsMia "FC ECU: a132 CA bms mia";
CM_ SG_ 895 FC_a133_CA_evseMia "FC ECU: a133 CA evse mia";
CM_ SG_ 895 FC_a134_CA_vehTxBufOvf "FC ECU: a134 CA veh tx buf ovf";
CM_ SG_ 895 FC_a135_CA_vehRxBufOvf "FC ECU: a135 CA veh rx buf ovf";
CM_ SG_ 895 FC_a136_CA_evseTxBufOvf "FC ECU: a136 CA evse tx buf ovf";
CM_ SG_ 895 FC_a137_CA_evseRxBufOvf "FC ECU: a137 CA evse rx buf ovf";
CM_ SG_ 895 FC_a138_CA_hwProxTrip "FC ECU: a138 CA hw prox trip";
CM_ SG_ 895 FC_a139_CA_ss2NotLow "FC ECU: a139 CA ss2 not low";
CM_ SG_ 895 FC_a140_CA_bmsIncompatible "FC ECU: a140 CA bms incompatible";
CM_ SG_ 895 FC_a141_CA_vehConn_OT "FC ECU: a141 CA veh conn OT";
CM_ SG_ 895 FC_a142_CA_evseConn_OT "FC ECU: a142 CA evse conn OT";
CM_ SG_ 895 FC_a143_CA_pcb_OT "FC ECU: a143 CA pcb OT";
CM_ SG_ 895 FC_a144_CA_flybackUnstable "FC ECU: a144 CA flyback unstable";
CM_ SG_ 895 FC_a145_CA_flybackDataStale "FC ECU: a145 CA flyback data stale";
CM_ SG_ 895 FC_a146_CA_flybackBusLoadHi "FC ECU: a146 CA flyback bus load hi";
CM_ SG_ 895 FC_a147_CA_vehConn_UT "FC ECU: a147 CA veh conn UT";
CM_ SG_ 895 FC_a148_CA_evseConn_UT "FC ECU: a148 CA evse conn UT";
CM_ SG_ 895 FC_a149_CA_pcb_UT "FC ECU: a149 CA pcb UT";
CM_ SG_ 895 FC_a150_CA_vehToEvseDeltaHi "FC ECU: a150 CA veh to evse delta hi";
CM_ SG_ 895 FC_a151_CA_vehToEvseDeltaLo "FC ECU: a151 CA veh to evse delta lo";
CM_ SG_ 895 FC_a152_CA_vehToPcbDeltaHi "FC ECU: a152 CA veh to pcb delta hi";
CM_ SG_ 895 FC_a153_CA_evseToPcbDeltaHi "FC ECU: a153 CA evse to pcb delta hi";
CM_ SG_ 895 FC_a154_CA_vehToPcbDeltaLo "FC ECU: a154 CA veh to pcb delta lo";
CM_ SG_ 895 FC_a155_CA_evseToPcbDeltaLo "FC ECU: a155 CA evse to pcb delta lo";
CM_ SG_ 895 FC_a156_CA_flybackRunTimeout "FC ECU: a156 CA flyback run timeout";
CM_ SG_ 895 FC_a157_CA_unused "FC ECU: a157 CA unused";
CM_ SG_ 895 FC_a158_CA_evseOverCurrent "FC ECU: a158 CA evse over current";
CM_ SG_ 895 FC_a159_CA_wdtExpired "FC ECU: a159 CA wdt expired";
CM_ SG_ 895 FC_a160_CA_ss2Deasserted "FC ECU: a160 CA ss2 deasserted";
CM_ SG_ 895 FC_a161_CA_vehTempHiFoldBk "FC ECU: a161 CA veh temp hi fold bk";
CM_ SG_ 895 FC_a162_CA_evseTempHiFoldBk "FC ECU: a162 CA evse temp hi fold bk";
CM_ SG_ 895 FC_a163_CA_pcbTempHiFoldBk "FC ECU: a163 CA pcb temp hi fold bk";
CM_ SG_ 895 FC_a164_CA_proxDisconnected "FC ECU: a164 CA prox disconnected";
CM_ SG_ 895 FC_a165_CA_evseConnUnlocked "FC ECU: a165 CA evse conn unlocked";
CM_ SG_ 895 FC_a166_CA_vehConnUnlocked "FC ECU: a166 CA veh conn unlocked";
CM_ SG_ 895 FC_a167_CA_isoVoltageLow "FC ECU: a167 CA iso voltage low";
CM_ SG_ 895 FC_a168_CA_proxTimeout "FC ECU: a168 CA prox timeout";
CM_ SG_ 895 FC_a169_CA_pilotAcceptTimeout "FC ECU: a169 CA pilot accept timeout";
CM_ SG_ 895 FC_a170_CA_vehDataTimeout "FC ECU: a170 CA veh data timeout";
CM_ SG_ 895 FC_a171_CA_vehConLockTimeout "FC ECU: a171 CA veh con lock timeout";
CM_ SG_ 895 FC_a172_CA_ss2LowTimeout "FC ECU: a172 CA ss2 low timeout";
CM_ SG_ 895 FC_a173_CA_evseDataTimeout "FC ECU: a173 CA evse data timeout";
CM_ SG_ 895 FC_a174_CA_vehReadyTimeout "FC ECU: a174 CA veh ready timeout";
CM_ SG_ 895 FC_a175_CA_evseIsoTestTimeout "FC ECU: a175 CA evse iso test timeout";
CM_ SG_ 895 FC_a176_CA_chargingBusTimeout "FC ECU: a176 CA charging bus timeout";
CM_ SG_ 895 FC_a177_CA_bmsCtrCloseTimeout "FC ECU: a177 CA bms ctr close timeout";
CM_ SG_ 895 FC_a178_CA_evseStartTimeout "FC ECU: a178 CA evse start timeout";
CM_ SG_ 895 FC_a179_CA_startupProblem "FC ECU: a179 CA startup problem";
CM_ SG_ 895 FC_a180_CA_chargingProblem "FC ECU: a180 CA charging problem";
CM_ SG_ 895 FC_a181_CA_vRegBrownout "FC ECU: a181 CA v reg brownout";
CM_ SG_ 895 FC_a182_CA_evseChrMalfunc "FC ECU: a182 CA evse chr malfunc";
CM_ SG_ 895 FC_a183_CA_evseBatIncompat "FC ECU: a183 CA evse bat incompat";
CM_ SG_ 895 FC_a184_CA_evseBatMalfunc "FC ECU: a184 CA evse bat malfunc";
CM_ SG_ 895 FC_a185_CA_vehReadyDeasserted "FC ECU: a185 CA veh ready deasserted";
CM_ SG_ 895 FC_a186_CA_fcContOpenTimeout "FC ECU: a186 CA fc cont open timeout";
CM_ SG_ 895 FC_a187_CA_evseConLockTimeout "FC ECU: a187 CA evse con lock timeout";
CM_ BO_ 927 "FC ECU message: alert matrix4; frame length from the layout, not yet observed on a vehicle bus";
CM_ SG_ 927 FC_a193_FCAlertPlaceholder "FC ECU: a193 FC alert placeholder";
CM_ BO_ 958 "FC ECU message: alert matrix5; frame length from the layout, not yet observed on a vehicle bus";
CM_ SG_ 958 FC_a257_GB_bmsMia "FC ECU: a257 GB bms mia";
CM_ SG_ 958 FC_a258_GB_evseMia "FC ECU: a258 GB evse mia";
CM_ SG_ 958 FC_a259_GB_vehTxBufOvf "FC ECU: a259 GB veh tx buf ovf";
CM_ SG_ 958 FC_a260_GB_vehRxBufOvf "FC ECU: a260 GB veh rx buf ovf";
CM_ SG_ 958 FC_a261_GB_evseTxBufOvf "FC ECU: a261 GB evse tx buf ovf";
CM_ SG_ 958 FC_a262_GB_evseRxBufOvf "FC ECU: a262 GB evse rx buf ovf";
CM_ SG_ 958 FC_a263_GB_hwProxTrip "FC ECU: a263 GB hw prox trip";
CM_ SG_ 958 FC_a264_GB_timeoutCHM "FC ECU: a264 GB timeout CHM";
CM_ SG_ 958 FC_a265_GB_bmsIncompatible "FC ECU: a265 GB bms incompatible";
CM_ SG_ 958 FC_a266_GB_negPin_OT "FC ECU: a266 GB neg pin OT";
CM_ SG_ 958 FC_a267_GB_posPin_OT "FC ECU: a267 GB pos pin OT";
CM_ SG_ 958 FC_a268_GB_pcb_OT "FC ECU: a268 GB pcb OT";
CM_ SG_ 958 FC_a269_GB_timeoutCRM "FC ECU: a269 GB timeout CRM";
CM_ SG_ 958 FC_a270_GB_timeoutCML "FC ECU: a270 GB timeout CML";
CM_ SG_ 958 FC_a271_GB_timeoutCRO "FC ECU: a271 GB timeout CRO";
CM_ SG_ 958 FC_a272_GB_negToPosDeltaHi "FC ECU: a272 GB neg to pos delta hi";
CM_ SG_ 958 FC_a273_GB_negToPosDeltaLo "FC ECU: a273 GB neg to pos delta lo";
CM_ SG_ 958 FC_a274_GB_negToPcbDeltaHi "FC ECU: a274 GB neg to pcb delta hi";
CM_ SG_ 958 FC_a275_GB_posToPcbDeltaHi "FC ECU: a275 GB pos to pcb delta hi";
CM_ SG_ 958 FC_a276_GB_negToPcbDeltaLo "FC ECU: a276 GB neg to pcb delta lo";
CM_ SG_ 958 FC_a277_GB_posToPcbDeltaLo "FC ECU: a277 GB pos to pcb delta lo";
CM_ SG_ 958 FC_a278_GB_timeoutCCS "FC ECU: a278 GB timeout CCS";
CM_ SG_ 958 FC_a279_GB_evseOverCurrent "FC ECU: a279 GB evse over current";
CM_ SG_ 958 FC_a280_GB_retryLimitExceeded "FC ECU: a280 GB retry limit exceeded";
CM_ SG_ 958 FC_a281_GB_evseOutOfService "FC ECU: a281 GB evse out of service";
CM_ SG_ 958 FC_a282_GB_negTempHiFoldBk "FC ECU: a282 GB neg temp hi fold bk";
CM_ SG_ 958 FC_a283_GB_posTempHiFoldBk "FC ECU: a283 GB pos temp hi fold bk";
CM_ SG_ 958 FC_a284_GB_pcbTempHiFoldBk "FC ECU: a284 GB pcb temp hi fold bk";
CM_ SG_ 958 FC_a285_GB_proxDisconnected "FC ECU: a285 GB prox disconnected";
CM_ SG_ 958 FC_a286_GB_evseConnUnlocked "FC ECU: a286 GB evse conn unlocked";
CM_ SG_ 958 FC_a287_GB_vehConnUnlocked "FC ECU: a287 GB veh conn unlocked";
CM_ SG_ 958 FC_a288_GB_evseAbnormalStopReq "FC ECU: a288 GB evse abnormal stop req";
CM_ SG_ 958 FC_a289_GB_proxTimeout "FC ECU: a289 GB prox timeout";
CM_ SG_ 958 FC_a290_GB_pilotAcceptTimeout "FC ECU: a290 GB pilot accept timeout";
CM_ SG_ 958 FC_a291_GB_vehDataTimeout "FC ECU: a291 GB veh data timeout";
CM_ SG_ 958 FC_a292_GB_vehConLockTimeout "FC ECU: a292 GB veh con lock timeout";
CM_ SG_ 958 FC_a293_GB_proxRationality "FC ECU: a293 GB prox rationality";
CM_ SG_ 958 FC_a294_GB_unused "FC ECU: a294 GB unused";
CM_ SG_ 958 FC_a295_GB_pilotRationality "FC ECU: a295 GB pilot rationality";
CM_ SG_ 958 FC_a296_GB_invalidPilotTransitio "FC ECU: a296 GB invalid pilot transitio";
CM_ SG_ 958 FC_a297_GB_unused "FC ECU: a297 GB unused";
CM_ SG_ 958 FC_a298_GB_bmsCtrCloseTimeout "FC ECU: a298 GB bms ctr close timeout";
CM_ SG_ 958 FC_a299_GB_evseReadyTimeout "FC ECU: a299 GB evse ready timeout";
CM_ SG_ 958 FC_a300_GB_unused "FC ECU: a300 GB unused";
CM_ SG_ 958 FC_a301_GB_unused "FC ECU: a301 GB unused";
CM_ SG_ 958 FC_a302_GB_unused "FC ECU: a302 GB unused";
CM_ SG_ 958 FC_a303_GB_negRecogTimeout "FC ECU: a303 GB neg recog timeout";
CM_ SG_ 958 FC_a304_GB_unused "FC ECU: a304 GB unused";
CM_ SG_ 958 FC_a305_GB_posRecogTimeout "FC ECU: a305 GB pos recog timeout";
CM_ SG_ 958 FC_a306_GB_vehReadyDeasserted "FC ECU: a306 GB veh ready deasserted";
CM_ SG_ 958 FC_a307_GB_fcContOpenTimeout "FC ECU: a307 GB fc cont open timeout";
CM_ SG_ 958 FC_a308_GB_evseConLockTimeout "FC ECU: a308 GB evse con lock timeout";
CM_ SG_ 958 FC_a309_GB_unused "FC ECU: a309 GB unused";
CM_ SG_ 958 FC_a310_GB_unused "FC ECU: a310 GB unused";
CM_ SG_ 958 FC_a311_GB_battParamsTimeout "FC ECU: a311 GB batt params timeout";
CM_ SG_ 958 FC_a312_GB_evseLimitsTimeout "FC ECU: a312 GB evse limits timeout";
CM_ SG_ 958 FC_a313_GB_inputVoltageRailOv "FC ECU: a313 GB input voltage rail ov";
CM_ BO_ 990 "FC ECU message: alert matrix6; frame length from the layout, not yet observed on a vehicle bus";
CM_ SG_ 990 FC_a321_FCAlertPlaceholder "FC ECU: a321 FC alert placeholder";
CM_ BO_ 1117 "FC ECU message: evse billing; frame length from the layout, not yet observed on a vehicle bus";
CM_ SG_ 1117 FC_evseBillingDataSelect "FC ECU: evse billing data select";
CM_ SG_ 1117 FC_evseBillingEnergy "FC ECU: evse billing energy";
CM_ SG_ 1117 FC_evseMeterPower "FC ECU: evse meter power";
CM_ SG_ 1117 FC_evseMeterCurrent "FC ECU: evse meter current";
CM_ SG_ 1117 FC_evseMeterVoltage "FC ECU: evse meter voltage";
CM_ SG_ 1117 FC_evseMeterFwGitHash "FC ECU: evse meter fw git hash";
CM_ BO_ 1334 "FC ECU message: evse billing2; frame length from the layout, not yet observed on a vehicle bus";
CM_ SG_ 1334 FC_evseBilling2DataSelect "FC ECU: evse billing2 data select";
CM_ SG_ 1334 FC_evsePpuEnabled "FC ECU: evse ppu enabled";
CM_ SG_ 1334 FC_evseBillingEnergyHighRes "FC ECU: evse billing energy high res; raw 16777215 = signal not available (SNA)";
CM_ BO_ 1303 "FC ECU message: identifier; frame length from the layout, not yet observed on a vehicle bus";
CM_ SG_ 1303 FC_id "Fast charger identifying number";
CM_ SG_ 1303 FC_sessionId "Fast charge session ID";
CM_ BO_ 1310 "FC ECU message: info; frame length from the layout, not yet observed on a vehicle bus";
CM_ SG_ 1310 FC_infoIndex "FC ECU: info index";
CM_ SG_ 1310 FC_infoBuildType "FC ECU: info build type";
CM_ SG_ 1310 FC_infoBuildConfigID "FC ECU: info build config ID";
CM_ SG_ 1310 FC_infoHardwareID "FC ECU: info hardware ID";
CM_ SG_ 1310 FC_infoComponentID "FC ECU: info component ID";
CM_ SG_ 1310 FC_infoPcbaID "FC ECU: info pcba ID";
CM_ SG_ 1310 FC_infoAssemblyID "FC ECU: info assembly ID";
CM_ SG_ 1310 FC_infoUsageID "FC ECU: info usage ID";
CM_ SG_ 1310 FC_infoSubUsageID "FC ECU: info sub usage ID";
CM_ SG_ 1310 FC_infoApplicationCRC "FC ECU: info application CRC";
CM_ SG_ 1310 FC_infoAppGitHashBytes "FC ECU: info app git hash bytes";
CM_ SG_ 1310 FC_infoBootGitHashBytes "FC ECU: info boot git hash bytes";
CM_ SG_ 1310 FC_infoPlatformType "FC ECU: info platform type";
CM_ SG_ 1310 FC_infoMajorVersion "Fast charger firmware major version number";
CM_ SG_ 1310 FC_infoBranchOrigin "Fast charger branch origin";
CM_ SG_ 1310 FC_infoMaturity "Fast charger firmware info";
CM_ SG_ 1310 FC_infoHardwareRevision "FC ECU: info hardware revision";
CM_ SG_ 1310 FC_partNumChar01 "FC ECU: part num char01";
CM_ SG_ 1310 FC_partNumChar02 "FC ECU: part num char02";
CM_ SG_ 1310 FC_partNumChar03 "FC ECU: part num char03";
CM_ SG_ 1310 FC_partNumChar04 "FC ECU: part num char04";
CM_ SG_ 1310 FC_partNumChar05 "FC ECU: part num char05";
CM_ SG_ 1310 FC_partNumChar06 "FC ECU: part num char06";
CM_ SG_ 1310 FC_partNumChar07 "FC ECU: part num char07";
CM_ SG_ 1310 FC_partNumChar08 "FC ECU: part num char08";
CM_ SG_ 1310 FC_partNumChar09 "FC ECU: part num char09";
CM_ SG_ 1310 FC_partNumChar10 "FC ECU: part num char10";
CM_ SG_ 1310 FC_partNumChar11 "FC ECU: part num char11";
CM_ SG_ 1310 FC_partNumChar12 "FC ECU: part num char12";
CM_ SG_ 1310 FC_partNumChar13 "FC ECU: part num char13";
CM_ SG_ 1310 FC_partNumChar14 "FC ECU: part num char14";
CM_ SG_ 1310 FC_partNumChar15 "FC ECU: part num char15";
CM_ SG_ 1310 FC_partNumChar16 "FC ECU: part num char16";
CM_ SG_ 1310 FC_partNumChar17 "FC ECU: part num char17";
CM_ SG_ 1310 FC_partNumChar18 "FC ECU: part num char18";
CM_ SG_ 1310 FC_partNumChar19 "FC ECU: part num char19";
CM_ SG_ 1310 FC_partNumChar20 "FC ECU: part num char20";
CM_ BO_ 580 "FC ECU message: limits; frame length from the layout, not yet observed on a vehicle bus";
CM_ SG_ 580 FC_powerLimit "Instantaneous power charger can deliver; raw 8191 = signal not available (SNA)";
CM_ SG_ 580 FC_currentLimit "Instantaneous current charger can deliver; raw 8191 = signal not available (SNA)";
CM_ SG_ 580 FC_maxVoltageLimit "Max voltage charger can deliver. 600/65536; raw 8191 = signal not available (SNA)";
CM_ SG_ 580 FC_minVoltageLimit "Measures Electric Vehicle Supply Equipment (EVSE) minimum current limit; raw 8191 = signal not available (SNA)";
CM_ BO_ 702 "FC ECU message: limits high power; frame length from the layout, not yet observed on a vehicle bus";
CM_ SG_ 702 FC_powerLimit_value "Instantaneous power charger can deliver. Mantissa portion of extended range version of legacy signal, used with protocol versions 9+. FC_powerLimit = value * 10^exp; raw 32768 = signal not available (SNA)";
CM_ SG_ 702 FC_currentLimit_value "FC ECU: current limit value; raw 32768 = signal not available (SNA)";
CM_ SG_ 702 FC_minVoltageLimit_value "FC ECU: min voltage limit value; raw 32768 = signal not available (SNA)";
CM_ SG_ 702 FC_powerLimit_exp "Instantaneous power charger can deliver. Exponent portion of extended ragne version of legacy signal, used with protocol versions 9+. FC_powerLimit = value * 10^exp.";
CM_ SG_ 702 FC_currentLimit_exp "FC ECU: current limit exp";
CM_ SG_ 702 FC_minVoltageLimit_exp "FC ECU: min voltage limit exp";
CM_ BO_ 1345 "FC ECU message: max limits; frame length from the layout, not yet observed on a vehicle bus";
CM_ SG_ 1345 FC_maxPowerLimit "Max power charger can deliver; raw 8191 = signal not available (SNA)";
CM_ SG_ 1345 FC_maxCurrentLimit "Max current charger can deliver; raw 8191 = signal not available (SNA)";
CM_ BO_ 1300 "FC ECU message: serial; frame length from the layout, not yet observed on a vehicle bus";
CM_ SG_ 1300 FC_serialDataSelect "FC ECU: serial data select";
CM_ SG_ 1300 FC_serialChar01 "FC ECU: serial char01";
CM_ SG_ 1300 FC_serialChar02 "FC ECU: serial char02";
CM_ SG_ 1300 FC_serialChar03 "FC ECU: serial char03";
CM_ SG_ 1300 FC_serialChar04 "FC ECU: serial char04";
CM_ SG_ 1300 FC_serialChar05 "FC ECU: serial char05";
CM_ SG_ 1300 FC_serialChar06 "FC ECU: serial char06";
CM_ SG_ 1300 FC_serialChar07 "FC ECU: serial char07";
CM_ SG_ 1300 FC_serialChar08 "FC ECU: serial char08";
CM_ SG_ 1300 FC_serialChar09 "FC ECU: serial char09";
CM_ SG_ 1300 FC_serialChar10 "FC ECU: serial char10";
CM_ SG_ 1300 FC_serialChar11 "FC ECU: serial char11";
CM_ SG_ 1300 FC_serialChar12 "FC ECU: serial char12";
CM_ SG_ 1300 FC_serialChar13 "FC ECU: serial char13";
CM_ SG_ 1300 FC_serialChar14 "FC ECU: serial char14";
CM_ SG_ 1300 FC_serialChar15 "FC ECU: serial char15";
CM_ SG_ 1300 FC_serialChar16 "FC ECU: serial char16";
CM_ SG_ 1300 FC_serialChar17 "FC ECU: serial char17";
CM_ BO_ 532 "FC ECU message: status; frame length from the layout, not yet observed on a vehicle bus";
CM_ SG_ 532 FC_protocolVersion "FC ECU: protocol version";
CM_ SG_ 532 FC_statusCode "Fast charger status code; raw 0 = signal not available (SNA)";
CM_ SG_ 532 FC_deprecated1 "FC ECU: deprecated1";
CM_ SG_ 532 FC_deprecated2 "FC ECU: deprecated2";
CM_ SG_ 532 FC_deprecated3 "FC ECU: deprecated3";
CM_ SG_ 532 FC_adapterLocked "Indicates if the DC adapter is secure or not";
CM_ SG_ 532 FC_minCurrentLimit "Fast charger min current limit";
CM_ SG_ 532 FC_type "Type of EVSE connected that supports digital communication; raw 7 = signal not available (SNA)";
CM_ SG_ 532 FC_dcCurrent "Fast charger DC output current";
CM_ SG_ 532 FC_postID "Fast charger charging post ID; raw 3 = signal not available (SNA)";
CM_ SG_ 532 FC_dcVoltage "Fast charger DC voltage";
CM_ SG_ 532 FC_leakageTestNotSupported "Indicates if the S/X leakage test can be run on this supercharger";
CM_ SG_ 532 FC_dischargeSupported "FC ECU: discharge supported";
CM_ BO_ 533 "FC ECU message: status2; frame length from the layout, not yet observed on a vehicle bus";
CM_ SG_ 533 FC_externalIsolationResistance "Fast charger external isolation resistance; raw 255 = signal not available (SNA)";
CM_ BO_ 535 "FC ECU message: status3; frame length from the layout, not yet observed on a vehicle bus";
CM_ SG_ 535 FC_status3DataSelect "FC ECU: status3 data select";
CM_ SG_ 535 FC_status3DummySig "FC ECU: status3 dummy sig";
CM_ SG_ 535 FC_class "FC ECU: class; raw 0 = signal not available (SNA)";
CM_ SG_ 535 FC_brand "Fast charger brand; raw 0 = signal not available (SNA)";
CM_ SG_ 535 FC_coolingType "Type of cooling used for the supercharger; raw 0 = signal not available (SNA)";
CM_ SG_ 535 FC_uiStopType "Type of stop type supported from the UI; raw 0 = signal not available (SNA)";
CM_ SG_ 535 FC_emergencyShutdownSupported "Indicates if the supercharger supports fast emergency shutdown requests from vehicle";
CM_ SG_ 535 FC_generation "Hardware generation of the Tesla EVSE; raw 0 = signal not available (SNA)";
CM_ BO_ 1650 "HCML ECU message: info; frame length observed on a vehicle bus";
CM_ SG_ 1650 VC_hcmlInfoIndex "HCML ECU: hcml info index";
CM_ SG_ 1650 VC_infoHCMLBuildConfigId "HCM Diagnostic Field.";
CM_ SG_ 1650 VC_leftHeadlampLMMVariant "Reports the detected left headlamp LED Matrix Manager (LMM) variant; raw 0 = signal not available (SNA)";
CM_ SG_ 1650 VC_infoHCMLAssemblyId "HCM Diagnostic Field.";
CM_ SG_ 1650 VC_infoHCMLPcbaId "HCM Diagnostic Field.";
CM_ SG_ 1650 VC_infoHCMLUsageId "HCM Diagnostic Field.";
CM_ BO_ 1980 "HCMR ECU message: info; frame length observed on a vehicle bus";
CM_ SG_ 1980 VC_hcmrInfoIndex "HCMR ECU: hcmr info index";
CM_ SG_ 1980 VC_infoHCMRBuildConfigId "HCM Diagnostic Field.";
CM_ SG_ 1980 VC_rightHeadlampLMMVariant "Reports the detected right headlamp LED Matrix Manager (LMM) variant; raw 0 = signal not available (SNA)";
CM_ SG_ 1980 VC_infoHCMRAssemblyId "HCM Diagnostic Field.";
CM_ SG_ 1980 VC_infoHCMRPcbaId "HCM Diagnostic Field.";
CM_ SG_ 1980 VC_infoHCMRUsageId "HCM Diagnostic Field.";
CM_ BO_ 1290 "High-voltage processor (pack contactor and isolation controller) message: alert log; frame length from the layout, not yet observed on a vehicle bus";
CM_ SG_ 1290 HVP_alertID "High-voltage processor (pack contactor and isolation controller): alert ID";
CM_ SG_ 1290 HVP_alertSet "High-voltage processor (pack contactor and isolation controller): alert set";
CM_ SG_ 1290 HVP_a005_current "High-voltage processor (pack contactor and isolation controller): a005 current";
CM_ SG_ 1290 HVP_a006_current "High-voltage processor (pack contactor and isolation controller): a006 current";
CM_ SG_ 1290 HVP_a007_current "High-voltage processor (pack contactor and isolation controller): a007 current";
CM_ SG_ 1290 HVP_a008_temperature "High-voltage processor (pack contactor and isolation controller): a008 temperature";
CM_ SG_ 1290 HVP_a008_sensorId "High-voltage processor (pack contactor and isolation controller): a008 sensor id";
CM_ SG_ 1290 HVP_a008_primaryChainSensor "High-voltage processor (pack contactor and isolation controller): a008 primary chain sensor";
CM_ SG_ 1290 HVP_a009_brickVoltage "High-voltage processor (pack contactor and isolation controller): a009 brick voltage";
CM_ SG_ 1290 HVP_a009_brickId "High-voltage processor (pack contactor and isolation controller): a009 brick id";
CM_ SG_ 1290 HVP_a009_primaryChainSensor "High-voltage processor (pack contactor and isolation controller): a009 primary chain sensor";
CM_ SG_ 1290 HVP_a010_brickVoltage "High-voltage processor (pack contactor and isolation controller): a010 brick voltage";
CM_ SG_ 1290 HVP_a010_brickId "High-voltage processor (pack contactor and isolation controller): a010 brick id";
CM_ SG_ 1290 HVP_a010_primaryChainSensor "High-voltage processor (pack contactor and isolation controller): a010 primary chain sensor";
CM_ SG_ 1290 HVP_a012_breakLocationA "High-voltage processor (pack contactor and isolation controller): a012 break location a";
CM_ SG_ 1290 HVP_a012_bmbCommStatusTypeA "High-voltage processor (pack contactor and isolation controller): a012 bmb comm status type a";
CM_ SG_ 1290 HVP_a012_breakLocationB "High-voltage processor (pack contactor and isolation controller): a012 break location b";
CM_ SG_ 1290 HVP_a012_bmbCommStatusTypeB "High-voltage processor (pack contactor and isolation controller): a012 bmb comm status type b";
CM_ SG_ 1290 HVP_a013_breakLocationA "High-voltage processor (pack contactor and isolation controller): a013 break location a";
CM_ SG_ 1290 HVP_a013_bmbCommStatusTypeA "High-voltage processor (pack contactor and isolation controller): a013 bmb comm status type a";
CM_ SG_ 1290 HVP_a013_breakLocationB "High-voltage processor (pack contactor and isolation controller): a013 break location b";
CM_ SG_ 1290 HVP_a013_bmbCommStatusTypeB "High-voltage processor (pack contactor and isolation controller): a013 bmb comm status type b";
CM_ SG_ 1290 HVP_a013_bmbChainBreakType "High-voltage processor (pack contactor and isolation controller): a013 bmb chain break type";
CM_ SG_ 1290 HVP_a018_dcLinkVoltage "High-voltage processor (pack contactor and isolation controller): a018 dc link voltage";
CM_ SG_ 1290 HVP_a018_battery12V "High-voltage processor (pack contactor and isolation controller): a018 battery12 v";
CM_ SG_ 1290 HVP_a018_remainingPcsPowerCycles "High-voltage processor (pack contactor and isolation controller): a018 remaining pcs power cycles allowed";
CM_ SG_ 1290 HVP_a018_remainingPcsRecoveriesA "High-voltage processor (pack contactor and isolation controller): a018 remaining pcs recoveries allowed";
CM_ SG_ 1290 HVP_a018_hvcHardwareSupportsCycl "High-voltage processor (pack contactor and isolation controller): a018 hvc hardware supports cycling";
CM_ SG_ 1290 HVP_a018_pcsHardwareOkToBePowerC "High-voltage processor (pack contactor and isolation controller): a018 pcs hardware ok to be power cycled";
CM_ SG_ 1290 HVP_a018_gpioLogicPowerEnable "High-voltage processor (pack contactor and isolation controller): a018 gpio logic power enable";
CM_ SG_ 1290 HVP_a018_gpioDcDcEnable "High-voltage processor (pack contactor and isolation controller): a018 gpio dc dc enable";
CM_ SG_ 1290 HVP_a018_gpioChgEnable "High-voltage processor (pack contactor and isolation controller): a018 gpio chg enable";
CM_ SG_ 1290 HVP_a020_energyReserveV "High-voltage processor (pack contactor and isolation controller): a020 energy reserve v; raw 65535 = signal not available (SNA)";
CM_ SG_ 1290 HVP_a020_shuntCurrentAux "High-voltage processor (pack contactor and isolation controller): a020 shunt current aux; raw 32768 = signal not available (SNA)";
CM_ SG_ 1290 HVP_a020_shuntTemperature "High-voltage processor (pack contactor and isolation controller): a020 shunt temperature; raw 32768 = signal not available (SNA)";
CM_ SG_ 1290 HVP_a021_pyroStatus "High-voltage processor (pack contactor and isolation controller): a021 pyro status";
CM_ SG_ 1290 HVP_a021_ErTestFailed "High-voltage processor (pack contactor and isolation controller): a021 er test failed";
CM_ SG_ 1290 HVP_a021_HighSideSwitchTestFaile "High-voltage processor (pack contactor and isolation controller): a021 high side switch test failed";
CM_ SG_ 1290 HVP_a021_LowSideSwitchTestFailed "High-voltage processor (pack contactor and isolation controller): a021 low side switch test failed";
CM_ SG_ 1290 HVP_a021_RefCurrentTestFailed "High-voltage processor (pack contactor and isolation controller): a021 ref current test failed";
CM_ SG_ 1290 HVP_a021_PyroLeakTestFailed "High-voltage processor (pack contactor and isolation controller): a021 pyro leak test failed";
CM_ SG_ 1290 HVP_a021_SquibResTestFailed "High-voltage processor (pack contactor and isolation controller): a021 squib res test failed";
CM_ SG_ 1290 HVP_a021_VstTestFailed "High-voltage processor (pack contactor and isolation controller): a021 vst test failed";
CM_ SG_ 1290 HVP_a021_SquibResistance "High-voltage processor (pack contactor and isolation controller): a021 squib resistance; raw 65535 = signal not available (SNA)";
CM_ SG_ 1290 HVP_a021_OneShotSequence "High-voltage processor (pack contactor and isolation controller): a021 one shot sequence";
CM_ SG_ 1290 HVP_a021_HighSide "High-voltage processor (pack contactor and isolation controller): a021 high side";
CM_ SG_ 1290 HVP_a021_LowSide "High-voltage processor (pack contactor and isolation controller): a021 low side";
CM_ SG_ 1290 HVP_a021_Aout "High-voltage processor (pack contactor and isolation controller): a021 aout; raw 16383 = signal not available (SNA)";
CM_ SG_ 1290 HVP_a022_pyroStatus "High-voltage processor (pack contactor and isolation controller): a022 pyro status";
CM_ SG_ 1290 HVP_a022_PyroLeakTestFailed "High-voltage processor (pack contactor and isolation controller): a022 pyro leak test failed";
CM_ SG_ 1290 HVP_a022_OneShotSequence "High-voltage processor (pack contactor and isolation controller): a022 one shot sequence";
CM_ SG_ 1290 HVP_a022_HighSide "High-voltage processor (pack contactor and isolation controller): a022 high side";
CM_ SG_ 1290 HVP_a022_LowSide "High-voltage processor (pack contactor and isolation controller): a022 low side";
CM_ SG_ 1290 HVP_a022_Aout "High-voltage processor (pack contactor and isolation controller): a022 aout; raw 16383 = signal not available (SNA)";
CM_ SG_ 1290 HVP_a022_SquibResistance "High-voltage processor (pack contactor and isolation controller): a022 squib resistance; raw 65535 = signal not available (SNA)";
CM_ SG_ 1290 HVP_a024_voltage "High-voltage processor (pack contactor and isolation controller): a024 voltage";
CM_ SG_ 1290 HVP_a025_voltage1 "High-voltage processor (pack contactor and isolation controller): a025 voltage1";
CM_ SG_ 1290 HVP_a025_voltage2 "High-voltage processor (pack contactor and isolation controller): a025 voltage2";
CM_ SG_ 1290 HVP_a025_packVoltage "High-voltage processor (pack contactor and isolation controller): a025 pack voltage";
CM_ SG_ 1290 HVP_a026_hvilStatus "High-voltage processor (pack contactor and isolation controller): a026 hvil status; raw 14 = signal not available (SNA)";
CM_ SG_ 1290 HVP_a026_inputVoltage "High-voltage processor (pack contactor and isolation controller): a026 input voltage";
CM_ SG_ 1290 HVP_a026_outputVoltage "High-voltage processor (pack contactor and isolation controller): a026 output voltage";
CM_ SG_ 1290 HVP_a026_internalVoltage "High-voltage processor (pack contactor and isolation controller): a026 internal voltage; raw 255 = signal not available (SNA)";
CM_ SG_ 1290 HVP_a026_dirVoltage "High-voltage processor (pack contactor and isolation controller): a026 dir voltage; raw 255 = signal not available (SNA)";
CM_ SG_ 1290 HVP_a026_difVoltage "High-voltage processor (pack contactor and isolation controller): a026 dif voltage; raw 255 = signal not available (SNA)";
CM_ SG_ 1290 HVP_a028_packVoltage "High-voltage processor (pack contactor and isolation controller): a028 pack voltage";
CM_ SG_ 1290 HVP_a028_sumOfBrickV "High-voltage processor (pack contactor and isolation controller): a028 sum of brick v";
CM_ SG_ 1290 HVP_a030_packPositiveLinkV "High-voltage processor (pack contactor and isolation controller): a030 pack positive link v";
CM_ SG_ 1290 HVP_a030_dcPositiveLinkV "High-voltage processor (pack contactor and isolation controller): a030 dc positive link v";
CM_ SG_ 1290 HVP_a031_packNegativeLinkV "High-voltage processor (pack contactor and isolation controller): a031 pack negative link v";
CM_ SG_ 1290 HVP_a031_dcNegativeLinkV "High-voltage processor (pack contactor and isolation controller): a031 dc negative link v";
CM_ SG_ 1290 HVP_a033_contactorPowerV "High-voltage processor (pack contactor and isolation controller): a033 contactor power v";
CM_ SG_ 1290 HVP_a033_coilCurrent "High-voltage processor (pack contactor and isolation controller): a033 coil current";
CM_ SG_ 1290 HVP_a033_pwmDutyCylePositive "High-voltage processor (pack contactor and isolation controller): a033 pwm duty cyle positive";
CM_ SG_ 1290 HVP_a033_pwmDutyCyleNegative "High-voltage processor (pack contactor and isolation controller): a033 pwm duty cyle negative";
CM_ SG_ 1290 HVP_a035_contactorPowerV "High-voltage processor (pack contactor and isolation controller): a035 contactor power v";
CM_ SG_ 1290 HVP_a035_coilCurrent "High-voltage processor (pack contactor and isolation controller): a035 coil current";
CM_ SG_ 1290 HVP_a035_pwmDutyCylePositive "High-voltage processor (pack contactor and isolation controller): a035 pwm duty cyle positive";
CM_ SG_ 1290 HVP_a035_pwmDutyCyleNegative "High-voltage processor (pack contactor and isolation controller): a035 pwm duty cyle negative";
CM_ SG_ 1290 HVP_a036_pyroFiringHandle "High-voltage processor (pack contactor and isolation controller): a036 pyro firing handle";
CM_ SG_ 1290 HVP_a036_pyroFiringTime "High-voltage processor (pack contactor and isolation controller): a036 pyro firing time";
CM_ SG_ 1290 HVP_a036_pyroFiringAttempt "High-voltage processor (pack contactor and isolation controller): a036 pyro firing attempt";
CM_ SG_ 1290 HVP_a037_pyroFiringHandle "High-voltage processor (pack contactor and isolation controller): a037 pyro firing handle";
CM_ SG_ 1290 HVP_a039_posContactorFailed "High-voltage processor (pack contactor and isolation controller): a039 pos contactor failed";
CM_ SG_ 1290 HVP_a039_negContactorFailed "High-voltage processor (pack contactor and isolation controller): a039 neg contactor failed";
CM_ SG_ 1290 HVP_a040_powerVoltage "High-voltage processor (pack contactor and isolation controller): a040 power voltage";
CM_ SG_ 1290 HVP_a040_coilCurrent "High-voltage processor (pack contactor and isolation controller): a040 coil current";
CM_ SG_ 1290 HVP_a040_posCtrVoltageDrop "High-voltage processor (pack contactor and isolation controller): a040 pos ctr voltage drop";
CM_ SG_ 1290 HVP_a040_negCtrVoltageDrop "High-voltage processor (pack contactor and isolation controller): a040 neg ctr voltage drop";
CM_ SG_ 1290 HVP_a040_posCtrAuxOpen "High-voltage processor (pack contactor and isolation controller): a040 pos ctr aux open";
CM_ SG_ 1290 HVP_a040_negCtrAuxOpen "High-voltage processor (pack contactor and isolation controller): a040 neg ctr aux open";
CM_ SG_ 1290 HVP_a041_overCurrent "High-voltage processor (pack contactor and isolation controller): a041 over current";
CM_ SG_ 1290 HVP_a041_overChargeCurrent "High-voltage processor (pack contactor and isolation controller): a041 over charge current";
CM_ SG_ 1290 HVP_a041_overDischargeCurrent "High-voltage processor (pack contactor and isolation controller): a041 over discharge current";
CM_ SG_ 1290 HVP_a041_overVoltage "High-voltage processor (pack contactor and isolation controller): a041 over voltage";
CM_ SG_ 1290 HVP_a041_overTemperature "High-voltage processor (pack contactor and isolation controller): a041 over temperature";
CM_ SG_ 1290 HVP_a041_underVoltage "High-voltage processor (pack contactor and isolation controller): a041 under voltage";
CM_ SG_ 1290 HVP_a041_crashEvent "High-voltage processor (pack contactor and isolation controller): a041 crash event";
CM_ SG_ 1290 HVP_a041_packContactorHw "High-voltage processor (pack contactor and isolation controller): a041 pack contactor hw";
CM_ SG_ 1290 HVP_a041_notAllowedtoEnergize "High-voltage processor (pack contactor and isolation controller): a041 not allowedto energize";
CM_ SG_ 1290 HVP_a041_bmbMia "High-voltage processor (pack contactor and isolation controller): a041 bmb mia";
CM_ SG_ 1290 HVP_a041_hvilFault "High-voltage processor (pack contactor and isolation controller): a041 hvil fault";
CM_ SG_ 1290 HVP_a041_contactorStateWelded "High-voltage processor (pack contactor and isolation controller): a041 contactor state welded";
CM_ SG_ 1290 HVP_a041_shuntHwMia "High-voltage processor (pack contactor and isolation controller): a041 shunt hw mia";
CM_ SG_ 1290 HVP_a041_shuntCurrentMia "High-voltage processor (pack contactor and isolation controller): a041 shunt current mia";
CM_ SG_ 1290 HVP_a041_packVoltageMismatch "High-voltage processor (pack contactor and isolation controller): a041 pack voltage mismatch";
CM_ SG_ 1290 HVP_a041_gpoRequestActive "High-voltage processor (pack contactor and isolation controller): a041 gpo request active";
CM_ SG_ 1290 HVP_a041_fcContactorClosing "High-voltage processor (pack contactor and isolation controller): a041 fc contactor closing";
CM_ SG_ 1290 HVP_a041_fcContactorOpening "High-voltage processor (pack contactor and isolation controller): a041 fc contactor opening";
CM_ SG_ 1290 HVP_a041_resetRequestRequired "High-voltage processor (pack contactor and isolation controller): a041 reset request required";
CM_ SG_ 1290 HVP_a041_pyroFault "High-voltage processor (pack contactor and isolation controller): a041 pyro fault";
CM_ SG_ 1290 HVP_a041_dcLinkOverVoltage "High-voltage processor (pack contactor and isolation controller): a041 dc link over voltage";
CM_ SG_ 1290 HVP_a042_overCurrent "High-voltage processor (pack contactor and isolation controller): a042 over current";
CM_ SG_ 1290 HVP_a042_overChargeCurrent "High-voltage processor (pack contactor and isolation controller): a042 over charge current";
CM_ SG_ 1290 HVP_a042_overDischargeCurrent "High-voltage processor (pack contactor and isolation controller): a042 over discharge current";
CM_ SG_ 1290 HVP_a042_overVoltage "High-voltage processor (pack contactor and isolation controller): a042 over voltage";
CM_ SG_ 1290 HVP_a042_overTemperature "High-voltage processor (pack contactor and isolation controller): a042 over temperature";
CM_ SG_ 1290 HVP_a042_crashEvent "High-voltage processor (pack contactor and isolation controller): a042 crash event";
CM_ SG_ 1290 HVP_a042_fcContactorHw "High-voltage processor (pack contactor and isolation controller): a042 fc contactor hw";
CM_ SG_ 1290 HVP_a042_notAllowedtoEnergize "High-voltage processor (pack contactor and isolation controller): a042 not allowedto energize";
CM_ SG_ 1290 HVP_a042_bmsHvsMia "High-voltage processor (pack contactor and isolation controller): a042 bms hvs mia";
CM_ SG_ 1290 HVP_a042_cpMia "High-voltage processor (pack contactor and isolation controller): a042 cp mia";
CM_ SG_ 1290 HVP_a042_cpFault "High-voltage processor (pack contactor and isolation controller): a042 cp fault";
CM_ SG_ 1290 HVP_a042_supply12V "High-voltage processor (pack contactor and isolation controller): a042 supply12 v";
CM_ SG_ 1290 HVP_a042_supplyVer "High-voltage processor (pack contactor and isolation controller): a042 supply ver";
CM_ SG_ 1290 HVP_a042_packVoltageMismatch "High-voltage processor (pack contactor and isolation controller): a042 pack voltage mismatch";
CM_ SG_ 1290 HVP_a042_hvilFault "High-voltage processor (pack contactor and isolation controller): a042 hvil fault";
CM_ SG_ 1290 HVP_a042_contactorStateWelded "High-voltage processor (pack contactor and isolation controller): a042 contactor state welded";
CM_ SG_ 1290 HVP_a042_shuntHwMia "High-voltage processor (pack contactor and isolation controller): a042 shunt hw mia";
CM_ SG_ 1290 HVP_a042_shuntCurrentMia "High-voltage processor (pack contactor and isolation controller): a042 shunt current mia";
CM_ SG_ 1290 HVP_a042_packContactorClosing "High-voltage processor (pack contactor and isolation controller): a042 pack contactor closing";
CM_ SG_ 1290 HVP_a042_packContactorOpening "High-voltage processor (pack contactor and isolation controller): a042 pack contactor opening";
CM_ SG_ 1290 HVP_a042_resetRequestRequired "High-voltage processor (pack contactor and isolation controller): a042 reset request required";
CM_ SG_ 1290 HVP_a042_cpVersionMismatch "High-voltage processor (pack contactor and isolation controller): a042 cp version mismatch";
CM_ SG_ 1290 HVP_a043_overCurrent "High-voltage processor (pack contactor and isolation controller): a043 over current";
CM_ SG_ 1290 HVP_a043_overChargeCurrent "High-voltage processor (pack contactor and isolation controller): a043 over charge current";
CM_ SG_ 1290 HVP_a043_overDischargeCurrent "High-voltage processor (pack contactor and isolation controller): a043 over discharge current";
CM_ SG_ 1290 HVP_a043_overVoltage "High-voltage processor (pack contactor and isolation controller): a043 over voltage";
CM_ SG_ 1290 HVP_a043_overTemperature "High-voltage processor (pack contactor and isolation controller): a043 over temperature";
CM_ SG_ 1290 HVP_a043_underVoltage "High-voltage processor (pack contactor and isolation controller): a043 under voltage";
CM_ SG_ 1290 HVP_a043_crashEvent "High-voltage processor (pack contactor and isolation controller): a043 crash event";
CM_ SG_ 1290 HVP_a043_packContactorHw "High-voltage processor (pack contactor and isolation controller): a043 pack contactor hw";
CM_ SG_ 1290 HVP_a043_notAllowedtoEnergize "High-voltage processor (pack contactor and isolation controller): a043 not allowedto energize";
CM_ SG_ 1290 HVP_a043_bmbMia "High-voltage processor (pack contactor and isolation controller): a043 bmb mia";
CM_ SG_ 1290 HVP_a043_contactorOpened "High-voltage processor (pack contactor and isolation controller): a043 contactor opened";
CM_ SG_ 1290 HVP_a044_overCurrent "High-voltage processor (pack contactor and isolation controller): a044 over current";
CM_ SG_ 1290 HVP_a044_overChargeCurrent "High-voltage processor (pack contactor and isolation controller): a044 over charge current";
CM_ SG_ 1290 HVP_a044_overDischargeCurrent "High-voltage processor (pack contactor and isolation controller): a044 over discharge current";
CM_ SG_ 1290 HVP_a044_overVoltage "High-voltage processor (pack contactor and isolation controller): a044 over voltage";
CM_ SG_ 1290 HVP_a044_overTemperature "High-voltage processor (pack contactor and isolation controller): a044 over temperature";
CM_ SG_ 1290 HVP_a044_crashEvent "High-voltage processor (pack contactor and isolation controller): a044 crash event";
CM_ SG_ 1290 HVP_a044_fcContactorHw "High-voltage processor (pack contactor and isolation controller): a044 fc contactor hw";
CM_ SG_ 1290 HVP_a044_notAllowedtoEnergize "High-voltage processor (pack contactor and isolation controller): a044 not allowedto energize";
CM_ SG_ 1290 HVP_a044_bmsHvsMia "High-voltage processor (pack contactor and isolation controller): a044 bms hvs mia";
CM_ SG_ 1290 HVP_a044_cpMia "High-voltage processor (pack contactor and isolation controller): a044 cp mia";
CM_ SG_ 1290 HVP_a044_cpFault "High-voltage processor (pack contactor and isolation controller): a044 cp fault";
CM_ SG_ 1290 HVP_a044_supply12V "High-voltage processor (pack contactor and isolation controller): a044 supply12 v";
CM_ SG_ 1290 HVP_a044_supplyVer "High-voltage processor (pack contactor and isolation controller): a044 supply ver";
CM_ SG_ 1290 HVP_a044_packVoltageMismatch "High-voltage processor (pack contactor and isolation controller): a044 pack voltage mismatch";
CM_ SG_ 1290 HVP_a044_contactorOpened "High-voltage processor (pack contactor and isolation controller): a044 contactor opened";
CM_ SG_ 1290 HVP_a044_cpVersionMismatch "High-voltage processor (pack contactor and isolation controller): a044 cp version mismatch";
CM_ SG_ 1290 HVP_a045_dcLinkVoltage "High-voltage processor (pack contactor and isolation controller): a045 dc link voltage";
CM_ SG_ 1290 HVP_a046_shuntCurrent "High-voltage processor (pack contactor and isolation controller): a046 shunt current";
CM_ SG_ 1290 HVP_a046_shuntTemperature "High-voltage processor (pack contactor and isolation controller): a046 shunt temperature";
CM_ SG_ 1290 HVP_a046_asicTemperature "High-voltage processor (pack contactor and isolation controller): a046 asic temperature";
CM_ SG_ 1290 HVP_a047_shuntCurrent "High-voltage processor (pack contactor and isolation controller): a047 shunt current";
CM_ SG_ 1290 HVP_a047_auxCurrent "High-voltage processor (pack contactor and isolation controller): a047 aux current";
CM_ SG_ 1290 HVP_a049_contactorPowerV "High-voltage processor (pack contactor and isolation controller): a049 contactor power v";
CM_ SG_ 1290 HVP_a049_coilCurrent "High-voltage processor (pack contactor and isolation controller): a049 coil current";
CM_ SG_ 1290 HVP_a049_posCtrState "High-voltage processor (pack contactor and isolation controller): a049 pos ctr state; raw 0 = signal not available (SNA)";
CM_ SG_ 1290 HVP_a049_negCtrState "High-voltage processor (pack contactor and isolation controller): a049 neg ctr state; raw 0 = signal not available (SNA)";
CM_ SG_ 1290 HVP_a050_contactorPowerV "High-voltage processor (pack contactor and isolation controller): a050 contactor power v";
CM_ SG_ 1290 HVP_a050_coilCurrent "High-voltage processor (pack contactor and isolation controller): a050 coil current";
CM_ SG_ 1290 HVP_a050_posCtrState "High-voltage processor (pack contactor and isolation controller): a050 pos ctr state; raw 0 = signal not available (SNA)";
CM_ SG_ 1290 HVP_a050_negCtrState "High-voltage processor (pack contactor and isolation controller): a050 neg ctr state; raw 0 = signal not available (SNA)";
CM_ SG_ 1290 HVP_a051_shuntTemperature "High-voltage processor (pack contactor and isolation controller): a051 shunt temperature; raw 32768 = signal not available (SNA)";
CM_ SG_ 1290 HVP_a051_shuntCurrent "High-voltage processor (pack contactor and isolation controller): a051 shunt current; raw 32768 = signal not available (SNA)";
CM_ SG_ 1290 HVP_a051_energyReserveV "High-voltage processor (pack contactor and isolation controller): a051 energy reserve v; raw 65535 = signal not available (SNA)";
CM_ SG_ 1290 HVP_a053_packVoltage "High-voltage processor (pack contactor and isolation controller): a053 pack voltage";
CM_ SG_ 1290 HVP_a053_dcLinkVoltage "High-voltage processor (pack contactor and isolation controller): a053 dc link voltage";
CM_ SG_ 1290 HVP_a056_diagnosis "High-voltage processor (pack contactor and isolation controller): a056 diagnosis; raw 0 = signal not available (SNA)";
CM_ SG_ 1290 HVP_a056_shuntCurrent "High-voltage processor (pack contactor and isolation controller): a056 shunt current";
CM_ SG_ 1290 HVP_a056_posPackContactorState "High-voltage processor (pack contactor and isolation controller): a056 pos pack contactor state; raw 0 = signal not available (SNA)";
CM_ SG_ 1290 HVP_a056_negPackContactorState "High-voltage processor (pack contactor and isolation controller): a056 neg pack contactor state; raw 0 = signal not available (SNA)";
CM_ SG_ 1290 HVP_a056_posFcContactorState "High-voltage processor (pack contactor and isolation controller): a056 pos fc contactor state; raw 0 = signal not available (SNA)";
CM_ SG_ 1290 HVP_a056_negFcContactorState "High-voltage processor (pack contactor and isolation controller): a056 neg fc contactor state; raw 0 = signal not available (SNA)";
CM_ SG_ 1290 HVP_a058_VrefSample "High-voltage processor (pack contactor and isolation controller): a058 vref sample";
CM_ SG_ 1290 HVP_a058_bmbDeviceId "High-voltage processor (pack contactor and isolation controller): a058 bmb device id";
CM_ SG_ 1290 HVP_a058_VrefStatus "High-voltage processor (pack contactor and isolation controller): a058 vref status";
CM_ SG_ 1290 HVP_a058_VrefType "High-voltage processor (pack contactor and isolation controller): a058 vref type";
CM_ SG_ 1290 HVP_a060_stackVoltage "High-voltage processor (pack contactor and isolation controller): a060 stack voltage";
CM_ SG_ 1290 HVP_a060_sumBrickVoltage "High-voltage processor (pack contactor and isolation controller): a060 sum brick voltage";
CM_ SG_ 1290 HVP_a060_stackId "High-voltage processor (pack contactor and isolation controller): a060 stack id";
CM_ SG_ 1290 HVP_a062_bmbDeviceMask "High-voltage processor (pack contactor and isolation controller): a062 bmb device mask";
CM_ SG_ 1290 HVP_a067_hvilTypeFromHvp "High-voltage processor (pack contactor and isolation controller): a067 hvil type from hvp";
CM_ SG_ 1290 HVP_a067_hvilTypeFromGateway "High-voltage processor (pack contactor and isolation controller): a067 hvil type from gateway";
CM_ SG_ 1290 HVP_a067_hvilTypeIsFromCal "High-voltage processor (pack contactor and isolation controller): a067 hvil type is from cal";
CM_ SG_ 1290 HVP_a068_shuntTemperature "High-voltage processor (pack contactor and isolation controller): a068 shunt temperature; raw 32768 = signal not available (SNA)";
CM_ SG_ 1290 HVP_a068_shuntCurrent "High-voltage processor (pack contactor and isolation controller): a068 shunt current; raw 32768 = signal not available (SNA)";
CM_ SG_ 1290 HVP_a068_energyReserveV "High-voltage processor (pack contactor and isolation controller): a068 energy reserve v; raw 65535 = signal not available (SNA)";
CM_ BO_ 938 "High-voltage processor (pack contactor and isolation controller) message: alert matrix; frame length from the layout, not yet observed on a vehicle bus";
CM_ SG_ 938 HVP_matrixIndex "High-voltage processor (pack contactor and isolation controller): matrix index";
CM_ SG_ 938 HVP_w001_WatchdogReset "High-voltage processor (pack contactor and isolation controller): w001 watchdog reset";
CM_ SG_ 938 HVP_w002_UnusedAlert2 "High-voltage processor (pack contactor and isolation controller): w002 unused alert2";
CM_ SG_ 938 HVP_w003_SwAssertion "High-voltage processor (pack contactor and isolation controller): w003 sw assertion";
CM_ SG_ 938 HVP_w004_CrashEvent "High-voltage processor (pack contactor and isolation controller): w004 crash event";
CM_ SG_ 938 HVP_w005_OverDchgCurrentFault "High-voltage processor (pack contactor and isolation controller): w005 over dchg current fault";
CM_ SG_ 938 HVP_w006_OverChargeCurrentFault "High-voltage processor (pack contactor and isolation controller): w006 over charge current fault";
CM_ SG_ 938 HVP_w007_OverCurrentFault "High-voltage processor (pack contactor and isolation controller): w007 over current fault";
CM_ SG_ 938 HVP_w008_OverTemperatureFault "High-voltage processor (pack contactor and isolation controller): w008 over temperature fault";
CM_ SG_ 938 HVP_w009_OverVoltageFault "High-voltage processor (pack contactor and isolation controller): w009 over voltage fault";
CM_ SG_ 938 HVP_w010_UnderVoltageFault "High-voltage processor (pack contactor and isolation controller): w010 under voltage fault";
CM_ SG_ 938 HVP_w011_PrimaryBmbMiaFault "High-voltage processor (pack contactor and isolation controller): w011 primary bmb mia fault";
CM_ SG_ 938 HVP_w012_BmbDataIntegrityLoss "High-voltage processor (pack contactor and isolation controller): w012 bmb data integrity loss";
CM_ SG_ 938 HVP_w013_BmbCommunication "High-voltage processor (pack contactor and isolation controller): w013 bmb communication";
CM_ SG_ 938 HVP_w014_BmsMiaOnHviFault "High-voltage processor (pack contactor and isolation controller): w014 bms mia on hvi fault";
CM_ SG_ 938 HVP_w015_CpMiaFault "High-voltage processor (pack contactor and isolation controller): w015 cp mia fault";
CM_ SG_ 938 HVP_w016_PcsMiaFault "High-voltage processor (pack contactor and isolation controller): w016 pcs mia fault";
CM_ SG_ 938 HVP_w017_GtwMiaFault "High-voltage processor (pack contactor and isolation controller): w017 gtw mia fault";
CM_ SG_ 938 HVP_w018_powerCyclingPcs "High-voltage processor (pack contactor and isolation controller): w018 power cycling pcs";
CM_ SG_ 938 HVP_w019_CpFault "High-voltage processor (pack contactor and isolation controller): w019 cp fault";
CM_ SG_ 938 HVP_w020_ShuntHwMiaFault "High-voltage processor (pack contactor and isolation controller): w020 shunt hw mia fault";
CM_ SG_ 938 HVP_w021_PyroMiaFault "High-voltage processor (pack contactor and isolation controller): w021 pyro mia fault";
CM_ SG_ 938 HVP_w022_PyroMiaWarning "High-voltage processor (pack contactor and isolation controller): w022 pyro mia warning";
CM_ SG_ 938 HVP_w023_BmbResetRecovery "High-voltage processor (pack contactor and isolation controller): w023 bmb reset recovery";
CM_ SG_ 938 HVP_w024_Supply12vFault "High-voltage processor (pack contactor and isolation controller): w024 supply12v fault";
CM_ SG_ 938 HVP_w025_VerSupplyFault "High-voltage processor (pack contactor and isolation controller): w025 ver supply fault";
CM_ SG_ 938 HVP_w026_HvilFault "High-voltage processor (pack contactor and isolation controller): w026 hvil fault";
CM_ SG_ 938 HVP_w027_BmsMiaOnHvsFault "High-voltage processor (pack contactor and isolation controller): w027 bms mia on hvs fault";
CM_ SG_ 938 HVP_w028_PackVoltMismatchFault "High-voltage processor (pack contactor and isolation controller): w028 pack volt mismatch fault";
CM_ SG_ 938 HVP_w029_EnsMiaFault "High-voltage processor (pack contactor and isolation controller): w029 ens mia fault";
CM_ SG_ 938 HVP_w030_PackPosCtrArcFault "High-voltage processor (pack contactor and isolation controller): w030 pack pos ctr arc fault";
CM_ SG_ 938 HVP_w031_packNegCtrArcFault "High-voltage processor (pack contactor and isolation controller): w031 pack neg ctr arc fault";
CM_ SG_ 938 HVP_w032_ShuntHwAndBmsMiaFault "High-voltage processor (pack contactor and isolation controller): w032 shunt hw and bms mia fault";
CM_ SG_ 938 HVP_w033_fcContHwFault "High-voltage processor (pack contactor and isolation controller): w033 fc cont hw fault";
CM_ SG_ 938 HVP_w034_cpMismatchFault "High-voltage processor (pack contactor and isolation controller): w034 cp mismatch fault";
CM_ SG_ 938 HVP_w035_packContHwFault "High-voltage processor (pack contactor and isolation controller): w035 pack cont hw fault";
CM_ SG_ 938 HVP_w036_pyroFuseBlown "High-voltage processor (pack contactor and isolation controller): w036 pyro fuse blown";
CM_ SG_ 938 HVP_w037_pyroFuseFailedToBlow "High-voltage processor (pack contactor and isolation controller): w037 pyro fuse failed to blow";
CM_ SG_ 938 HVP_w038_CpilFault "High-voltage processor (pack contactor and isolation controller): w038 cpil fault";
CM_ SG_ 938 HVP_w039_PackContactorFellOpen "High-voltage processor (pack contactor and isolation controller): w039 pack contactor fell open";
CM_ SG_ 938 HVP_w040_FcContactorFellOpen "High-voltage processor (pack contactor and isolation controller): w040 fc contactor fell open";
CM_ SG_ 938 HVP_w041_packCtrCloseBlocked "High-voltage processor (pack contactor and isolation controller): w041 pack ctr close blocked";
CM_ SG_ 938 HVP_w042_fcCtrCloseBlocked "High-voltage processor (pack contactor and isolation controller): w042 fc ctr close blocked";
CM_ SG_ 938 HVP_w043_packContactorForceOpen "High-voltage processor (pack contactor and isolation controller): w043 pack contactor force open";
CM_ SG_ 938 HVP_w044_fcContactorForceOpen "High-voltage processor (pack contactor and isolation controller): w044 fc contactor force open";
CM_ SG_ 938 HVP_w045_dcLinkOverVoltage "High-voltage processor (pack contactor and isolation controller): w045 dc link over voltage";
CM_ SG_ 938 HVP_w046_shuntOverTemperature "High-voltage processor (pack contactor and isolation controller): w046 shunt over temperature";
CM_ SG_ 938 HVP_w047_passivePyroDeploy "High-voltage processor (pack contactor and isolation controller): w047 passive pyro deploy";
CM_ SG_ 938 HVP_w048_swUnsupportedBmbAsicTyp "High-voltage processor (pack contactor and isolation controller): w048 sw unsupported bmb asic type";
CM_ SG_ 938 HVP_w049_packCtrCloseFailed "High-voltage processor (pack contactor and isolation controller): w049 pack ctr close failed";
CM_ SG_ 938 HVP_w050_fcCtrCloseFailed "High-voltage processor (pack contactor and isolation controller): w050 fc ctr close failed";
CM_ SG_ 938 HVP_w051_shuntThermistorMia "High-voltage processor (pack contactor and isolation controller): w051 shunt thermistor mia";
CM_ SG_ 938 HVP_w052_BmbStatusRegError "High-voltage processor (pack contactor and isolation controller): w052 bmb status reg error";
CM_ SG_ 938 HVP_w053_hvVoltageSensorRational "High-voltage processor (pack contactor and isolation controller): w053 hv voltage sensor rationality";
CM_ SG_ 938 HVP_w054_swMissingConfigBlock "High-voltage processor (pack contactor and isolation controller): w054 sw missing config block";
CM_ SG_ 938 HVP_w055_swMissingPartNumber "High-voltage processor (pack contactor and isolation controller): w055 sw missing part number";
CM_ SG_ 938 HVP_w056_contactorFailedToOpen "High-voltage processor (pack contactor and isolation controller): w056 contactor failed to open";
CM_ SG_ 938 HVP_w057_BatmanDiagnosticsError "High-voltage processor (pack contactor and isolation controller): w057 batman diagnostics error";
CM_ SG_ 938 HVP_w058_BmbVrefBad "High-voltage processor (pack contactor and isolation controller): w058 bmb vref bad";
CM_ SG_ 938 HVP_w059_BmbVrefWarning "High-voltage processor (pack contactor and isolation controller): w059 bmb vref warning";
CM_ SG_ 938 HVP_w060_StackVoltageSense "High-voltage processor (pack contactor and isolation controller): w060 stack voltage sense";
CM_ SG_ 938 HVP_w061_ShuntCurrentRationality "High-voltage processor (pack contactor and isolation controller): w061 shunt current rationality";
CM_ SG_ 938 HVP_w062_BmbOtpConfigError "High-voltage processor (pack contactor and isolation controller): w062 bmb otp config error";
CM_ SG_ 938 HVP_w063_BmbBrickVRationality "High-voltage processor (pack contactor and isolation controller): w063 bmb brick v rationality";
CM_ SG_ 938 HVP_w064_BmbAuxVRationality "High-voltage processor (pack contactor and isolation controller): w064 bmb aux v rationality";
CM_ SG_ 938 HVP_w065_FastOpenVshDetected "High-voltage processor (pack contactor and isolation controller): w065 fast open vsh detected";
CM_ SG_ 938 HVP_w067_HvilCalNodeMismatch "High-voltage processor (pack contactor and isolation controller): w067 hvil cal node mismatch";
CM_ SG_ 938 HVP_w068_shuntUnexpectedThermist "High-voltage processor (pack contactor and isolation controller): w068 shunt unexpected thermistor";
CM_ SG_ 938 HVP_w069_hviCanFrameRxDropped "High-voltage processor (pack contactor and isolation controller): w069 hvi can frame rx dropped";
CM_ SG_ 938 HVP_w070_hvsCanFrameRxDropped "High-voltage processor (pack contactor and isolation controller): w070 hvs can frame rx dropped";
CM_ SG_ 938 HVP_w071_PassivePyroVrefRational "High-voltage processor (pack contactor and isolation controller): w071 passive pyro vref rationality";
CM_ BO_ 522 "High-voltage processor (pack contactor and isolation controller) message: contactor state; frame length from the layout, not yet observed on a vehicle bus";
CM_ SG_ 522 HVP_packContNegativeState "High-voltage processor (pack contactor and isolation controller): pack cont negative state; raw 0 = signal not available (SNA)";
CM_ SG_ 522 HVP_packContPositiveState "Current state of positive pack contactor; raw 0 = signal not available (SNA)";
CM_ SG_ 522 HVP_fcContPositiveAuxOpen "High-voltage processor (pack contactor and isolation controller): fc cont positive aux open";
CM_ SG_ 522 HVP_fcContNegativeAuxOpen "High-voltage processor (pack contactor and isolation controller): fc cont negative aux open";
CM_ SG_ 522 HVP_packContactorSetState "The current state of the pack contactors; raw 0 = signal not available (SNA)";
CM_ SG_ 522 HVP_fcContNegativeState "Current state of the negative FC contactor; raw 0 = signal not available (SNA)";
CM_ SG_ 522 HVP_contactorsBlocked "High-voltage processor (pack contactor and isolation controller): contactors blocked";
CM_ SG_ 522 HVP_fcContPositiveState "Current state of the positive FC contactor; raw 0 = signal not available (SNA)";
CM_ SG_ 522 HVP_fcContactorSetState "The current state of the fast charge contactors; raw 0 = signal not available (SNA)";
CM_ SG_ 522 HVP_fcCtrsRequestStatus "Current status of FC contactor request";
CM_ SG_ 522 HVP_fcCtrsResetRequestRequired "High-voltage processor (pack contactor and isolation controller): fc ctrs reset request required";
CM_ SG_ 522 HVP_fcCtrsOpenNowRequested "Flag indicated immediate-opening request of FC contactors";
CM_ SG_ 522 HVP_fcCtrsOpenRequested "Flag indicating opening request of FC contactors";
CM_ SG_ 522 HVP_fcCtrsClosingAllowed "Flag indicating closure allowance of FC contactors";
CM_ SG_ 522 HVP_packCtrsRequestStatus "Current request status of pack contactors";
CM_ SG_ 522 HVP_packCtrsResetRequestRequired "High-voltage processor (pack contactor and isolation controller): pack ctrs reset request required";
CM_ SG_ 522 HVP_packCtrsOpenNowRequested "Flag indicating immediate-opening request of pack contactors";
CM_ SG_ 522 HVP_packCtrsOpenRequested "Flag indicating opening request of pack contactors";
CM_ SG_ 522 HVP_packCtrsClosingAllowed "Flag indicating closure allowance of pack contactors";
CM_ SG_ 522 HVP_dcLinkAllowedToEnergize "Indicates there should be no HV exposure if the FC link is energized by an internal or external source";
CM_ SG_ 522 HVP_pyroTestInProgress "High-voltage processor (pack contactor and isolation controller): pyro test in progress";
CM_ SG_ 522 HVP_hvilDiag "Diagnostic status of HVIL circuit, including specific FAULT types; raw 14 = signal not available (SNA)";
CM_ SG_ 522 HVP_fcLinkAllowedToEnergize "The type of charge that is allowed to energize the FC link. Indicates that the HVP has disabled the dynamic FC weld check for DC charge, or has enabled the PCS charging hardware for AC charge";
CM_ BO_ 1962 "High-voltage processor (pack contactor and isolation controller) message: debug message; frame length from the layout, not yet observed on a vehicle bus";
CM_ SG_ 1962 HVP_debugMessageMultiplexer "High-voltage processor (pack contactor and isolation controller): debug message multiplexer";
CM_ SG_ 1962 HVP_ecuLogUploadRequest "High-voltage processor (pack contactor and isolation controller): ecu log upload request";
CM_ SG_ 1962 HVP_dcLinkVoltage "The HVP's measurement of the DC link voltage";
CM_ SG_ 1962 HVP_packVoltage "High-voltage processor (pack contactor and isolation controller): pack voltage";
CM_ SG_ 1962 HVP_fcLinkVoltage "Measured voltage on FC link";
CM_ SG_ 1962 HVP_10HzTask_stackUsage "High-voltage processor (pack contactor and isolation controller): 10 hz task stack usage";
CM_ SG_ 1962 HVP_packContVoltage "High-voltage processor (pack contactor and isolation controller): pack cont voltage";
CM_ SG_ 1962 HVP_packNegativeV "The HVP's common-mode measurement of PACK-HV-SENSE-NEG relative to chassis ground";
CM_ SG_ 1962 HVP_packPositiveV "The HVP's common-mode measurement of PACK-HV-SENSE-POS relative to chassis ground";
CM_ SG_ 1962 HVP_pyroAnalog "High-voltage processor (pack contactor and isolation controller): pyro analog";
CM_ SG_ 1962 HVP_shuntSetTCRCoeffA "High-voltage processor (pack contactor and isolation controller): shunt set TCR coeff a";
CM_ SG_ 1962 HVP_shuntSetTCRCoeffB "High-voltage processor (pack contactor and isolation controller): shunt set TCR coeff b";
CM_ SG_ 1962 HVP_shuntSetTCRCoeffC "High-voltage processor (pack contactor and isolation controller): shunt set TCR coeff c";
CM_ SG_ 1962 HVP_shuntSetTCRCoeffD "High-voltage processor (pack contactor and isolation controller): shunt set TCR coeff d";
CM_ SG_ 1962 HVP_fcContCoilCurrent "High-voltage processor (pack contactor and isolation controller): fc cont coil current";
CM_ SG_ 1962 HVP_fcContVoltage "High-voltage processor (pack contactor and isolation controller): fc cont voltage";
CM_ SG_ 1962 HVP_hvilInVoltage "Measured HVIL input voltage";
CM_ SG_ 1962 HVP_hvilOutVoltage "Measured HVIL output voltage";
CM_ SG_ 1962 HVP_shuntGainInvalidCountDbg "High-voltage processor (pack contactor and isolation controller): shunt gain invalid count dbg";
CM_ SG_ 1962 HVP_passivePyroRefVoltageMax "High-voltage processor (pack contactor and isolation controller): passive pyro ref voltage max; raw 1023 = signal not available (SNA)";
CM_ SG_ 1962 HVP_passivePyroRefVoltageMin "High-voltage processor (pack contactor and isolation controller): passive pyro ref voltage min; raw 1023 = signal not available (SNA)";
CM_ SG_ 1962 HVP_packContCoilCurrent "High-voltage processor (pack contactor and isolation controller): pack cont coil current";
CM_ SG_ 1962 HVP_battery12V "Monitored voltage sense of 12V battery";
CM_ SG_ 1962 HVP_fcLinkPositiveV "High-voltage processor (pack contactor and isolation controller): fc link positive v";
CM_ BO_ 554 "High-voltage processor (pack contactor and isolation controller) message: hvs control; frame length from the layout, not yet observed on a vehicle bus";
CM_ SG_ 554 HVP_dcLinkVoltageRequest "High-voltage processor (pack contactor and isolation controller): dc link voltage request";
CM_ SG_ 554 HVP_pcsControlRequest "The operating state that the HVP would like the PCS to be in";
CM_ SG_ 554 HVP_pcsChargeHwEnabled "The state of the PCS's charge enable line";
CM_ SG_ 554 HVP_pcsDcdcHwEnabled "The state of the PCS's DCDC enable line";
CM_ SG_ 554 HVP_dcLinkVoltageFiltered "High-voltage processor (pack contactor and isolation controller): dc link voltage filtered; raw 1498 = signal not available (SNA)";
CM_ BO_ 784 "High-voltage processor (pack contactor and isolation controller) message: info; frame length from the layout, not yet observed on a vehicle bus";
CM_ SG_ 784 HVP_infoIndex "High-voltage processor (pack contactor and isolation controller): info index";
CM_ SG_ 784 HVP_buildType "High-voltage processor (pack contactor and isolation controller): build type";
CM_ SG_ 784 HVP_buildConfigId "High-voltage processor (pack contactor and isolation controller): build config id";
CM_ SG_ 784 HVP_hardwareId "High-voltage processor (pack contactor and isolation controller): hardware id";
CM_ SG_ 784 HVP_componentId "High-voltage processor (pack contactor and isolation controller): component id";
CM_ SG_ 784 HVP_pcbaId "High-voltage processor (pack contactor and isolation controller): pcba id";
CM_ SG_ 784 HVP_assemblyId "HVP's assigned assembly ID";
CM_ SG_ 784 HVP_usageId "HVP's assigned usage ID";
CM_ SG_ 784 HVP_subUsageId "HVP's assigned subusage ID";
CM_ SG_ 784 HVP_platformType "High-voltage processor (pack contactor and isolation controller): platform type";
CM_ SG_ 784 HVP_appCrc "High-voltage processor (pack contactor and isolation controller): app crc";
CM_ SG_ 784 HVP_appGitHash "High-voltage processor (pack contactor and isolation controller): app git hash";
CM_ SG_ 784 HVP_bootGitHash "High-voltage processor (pack contactor and isolation controller): boot git hash";
CM_ SG_ 784 HVP_bootUdsProtoVersion "High-voltage processor (pack contactor and isolation controller): boot uds proto version";
CM_ SG_ 784 HVP_bootCrc "High-voltage processor (pack contactor and isolation controller): boot crc";
BA_DEF_ BO_ "GenMsgCycleTime" INT 0 3600000;
BA_DEF_ BO_ "GenMsgSendType" ENUM "Cyclic","NotUsed","NotUsed","NotUsed","NotUsed","NotUsed","NotUsed","IfActive","NoMsgSendType","NotUsed";
BA_DEF_ BO_ "VFrameFormat" ENUM "StandardCAN","ExtendedCAN","reserved","J1939PG","reserved","reserved","reserved","reserved","reserved","reserved","reserved","reserved","reserved","reserved","StandardCAN_FD","ExtendedCAN_FD";
BA_DEF_ BO_ "CANFD_BRS" ENUM "0","1";
BA_DEF_ SG_ "GenSigSNA" STRING;
BA_DEF_ SG_ "SystemSignalLongSymbol" STRING;
BA_DEF_ SG_ "Confidence" ENUM "validated","plausible","layout-only","contradicted";
BA_DEF_DEF_ "GenMsgCycleTime" 0;
BA_DEF_DEF_ "GenMsgSendType" "NoMsgSendType";
BA_DEF_DEF_ "VFrameFormat" "StandardCAN";
BA_DEF_DEF_ "CANFD_BRS" "1";
BA_DEF_DEF_ "GenSigSNA" "";
BA_DEF_DEF_ "SystemSignalLongSymbol" "";
BA_DEF_DEF_ "Confidence" "layout-only";
BA_ "GenMsgCycleTime" BO_ 1000 100;
BA_ "GenMsgSendType" BO_ 1000 0;
BA_ "GenMsgCycleTime" BO_ 2024 1000;
BA_ "GenMsgSendType" BO_ 2024 0;
BA_ "GenMsgCycleTime" BO_ 552 100;
BA_ "GenMsgSendType" BO_ 552 0;
BA_ "GenMsgCycleTime" BO_ 742 1000;
BA_ "GenMsgSendType" BO_ 742 0;
BA_ "GenMsgCycleTime" BO_ 744 100;
BA_ "GenMsgSendType" BO_ 744 0;
BA_ "GenMsgCycleTime" BO_ 895 1000;
BA_ "GenMsgSendType" BO_ 895 0;
BA_ "GenMsgCycleTime" BO_ 927 1000;
BA_ "GenMsgSendType" BO_ 927 0;
BA_ "GenMsgCycleTime" BO_ 958 1000;
BA_ "GenMsgSendType" BO_ 958 0;
BA_ "GenMsgCycleTime" BO_ 990 1000;
BA_ "GenMsgSendType" BO_ 990 0;
BA_ "GenMsgCycleTime" BO_ 1117 1000;
BA_ "GenMsgSendType" BO_ 1117 0;
BA_ "GenMsgCycleTime" BO_ 1334 1000;
BA_ "GenMsgSendType" BO_ 1334 0;
BA_ "GenMsgCycleTime" BO_ 1303 1000;
BA_ "GenMsgSendType" BO_ 1303 0;
BA_ "GenMsgCycleTime" BO_ 1310 1000;
BA_ "GenMsgSendType" BO_ 1310 0;
BA_ "GenMsgCycleTime" BO_ 580 100;
BA_ "GenMsgSendType" BO_ 580 0;
BA_ "GenMsgCycleTime" BO_ 702 100;
BA_ "GenMsgSendType" BO_ 702 0;
BA_ "GenMsgCycleTime" BO_ 1345 100;
BA_ "GenMsgSendType" BO_ 1345 0;
BA_ "GenMsgCycleTime" BO_ 1300 1000;
BA_ "GenMsgSendType" BO_ 1300 0;
BA_ "GenMsgCycleTime" BO_ 532 100;
BA_ "GenMsgSendType" BO_ 532 0;
BA_ "GenMsgCycleTime" BO_ 533 1000;
BA_ "GenMsgSendType" BO_ 533 0;
BA_ "GenMsgCycleTime" BO_ 535 1000;
BA_ "GenMsgSendType" BO_ 535 0;
BA_ "GenMsgCycleTime" BO_ 1650 10000;
BA_ "GenMsgSendType" BO_ 1650 0;
BA_ "GenMsgCycleTime" BO_ 1980 10000;
BA_ "GenMsgSendType" BO_ 1980 0;
BA_ "GenMsgCycleTime" BO_ 938 1000;
BA_ "GenMsgSendType" BO_ 938 0;
BA_ "GenMsgCycleTime" BO_ 522 1000;
BA_ "GenMsgSendType" BO_ 522 0;
BA_ "GenMsgCycleTime" BO_ 1962 1000;
BA_ "GenMsgSendType" BO_ 1962 0;
BA_ "GenMsgCycleTime" BO_ 554 100;
BA_ "GenMsgSendType" BO_ 554 0;
BA_ "GenMsgCycleTime" BO_ 784 10000;
BA_ "GenMsgSendType" BO_ 784 0;
BA_ "Confidence" SG_ 1000 EPBR_matrixIndex 1;
BA_ "SystemSignalLongSymbol" SG_ 1000 EPBR_a202_remoteEpbConfigIncompa "EPBR_a202_remoteEpbConfigIncompatible";
BA_ "SystemSignalLongSymbol" SG_ 1000 EPBR_a210_parkForDriverIsLeaving "EPBR_a210_parkForDriverIsLeavingDebug";
BA_ "SystemSignalLongSymbol" SG_ 1000 EPBR_a254_showStalkParkButtonFau "EPBR_a254_showStalkParkButtonFaultOnUi";
BA_ "SystemSignalLongSymbol" SG_ 1000 EPBR_a261_winchModeWithoutSteeri "EPBR_a261_winchModeWithoutSteering";
BA_ "SystemSignalLongSymbol" SG_ 1000 EPBR_a304_rearSeatControllerEFus "EPBR_a304_rearSeatControllerEFuseTrip";
BA_ "SystemSignalLongSymbol" SG_ 1000 EPBR_a353_missingSpeedUnableToPa "EPBR_a353_missingSpeedUnableToPark";
BA_ "SystemSignalLongSymbol" SG_ 1000 EPBR_a354_parkedForLowBrakeFluid "EPBR_a354_parkedForLowBrakeFluidMode";
BA_ "SystemSignalLongSymbol" SG_ 1000 EPBR_a355_brakeHwAndEpbHwMismatc "EPBR_a355_brakeHwAndEpbHwMismatch";
BA_ "SystemSignalLongSymbol" SG_ 1000 EPBR_a356_parkingForStationaryDe "EPBR_a356_parkingForStationaryDetect";
BA_ "SystemSignalLongSymbol" SG_ 1000 EPBR_a358_brakesTooHotForSlopeWi "EPBR_a358_brakesTooHotForSlopeWithOnlyOneEpb";
BA_ "SystemSignalLongSymbol" SG_ 1000 EPBR_a362_ibstPressedEspNotPress "EPBR_a362_ibstPressedEspNotPressedMismatch";
BA_ "SystemSignalLongSymbol" SG_ 1000 EPBR_a363_ibstNotPressedEspPress "EPBR_a363_ibstNotPressedEspPressedMismatch";
BA_ "SystemSignalLongSymbol" SG_ 1000 EPBR_a364_espMasterCylCompOverTh "EPBR_a364_espMasterCylCompOverThreshold";
BA_ "SystemSignalLongSymbol" SG_ 1000 EPBR_a365_TooSteepToParkWithTrai "EPBR_a365_TooSteepToParkWithTrailerWarning";
BA_ "SystemSignalLongSymbol" SG_ 1000 EPBR_a366_TooSteepToParkWithTrai "EPBR_a366_TooSteepToParkWithTrailerUnSecEnv";
BA_ "Confidence" SG_ 2024 EPBR_infoIndex 1;
BA_ "Confidence" SG_ 2024 EPBR_infoBuildType 0;
BA_ "Confidence" SG_ 2024 EPBR_infoBuildConfigId 0;
BA_ "Confidence" SG_ 2024 EPBR_infoHardwareId 0;
BA_ "Confidence" SG_ 2024 EPBR_infoComponentId 0;
BA_ "Confidence" SG_ 2024 EPBR_infoPcbaId 0;
BA_ "Confidence" SG_ 2024 EPBR_infoAssemblyId 0;
BA_ "GenSigSNA" SG_ 2024 EPBR_infoAssemblyId "255";
BA_ "Confidence" SG_ 2024 EPBR_infoUsageId 0;
BA_ "Confidence" SG_ 2024 EPBR_infoSubUsageId 0;
BA_ "Confidence" SG_ 2024 EPBR_infoAppCrc 0;
BA_ "Confidence" SG_ 2024 EPBR_infoAppGitHash 0;
BA_ "Confidence" SG_ 2024 EPBR_infoBootGitHash 0;
BA_ "Confidence" SG_ 2024 EPBR_infoPlatformType 0;
BA_ "Confidence" SG_ 2024 EPBR_infoBootUdsProtoVersion 0;
BA_ "Confidence" SG_ 2024 EPBR_infoBootCrc 0;
BA_ "Confidence" SG_ 552 EPBR_unitStatus 0;
BA_ "Confidence" SG_ 552 EPBR_unitFaultStatus 0;
BA_ "Confidence" SG_ 552 EPBR_summonState 0;
BA_ "Confidence" SG_ 552 EPBR_disconnected 0;
BA_ "Confidence" SG_ 552 EPBR_pistonTouchingRotor 0;
BA_ "Confidence" SG_ 552 EPBR_csmFaultReason 0;
BA_ "Confidence" SG_ 552 EPBR_esmOperationTrigger 0;
BA_ "Confidence" SG_ 552 EPBR_summonFaultReason 0;
BA_ "Confidence" SG_ 552 EPBR_localServiceModeActive 0;
BA_ "Confidence" SG_ 552 EPBR_localCdpState 0;
BA_ "Confidence" SG_ 552 EPBR_chimeRequestLocal 0;
BA_ "Confidence" SG_ 552 EPBR_telltaleLocal 0;
BA_ "GenSigSNA" SG_ 552 EPBR_telltaleLocal "7";
BA_ "Confidence" SG_ 552 EPBR_driverIsLeavingLocal 0;
BA_ "Confidence" SG_ 552 EPBR_driverIsLeavingAnySpeedLoca 0;
BA_ "SystemSignalLongSymbol" SG_ 552 EPBR_driverIsLeavingAnySpeedLoca "EPBR_driverIsLeavingAnySpeedLocal";
BA_ "Confidence" SG_ 552 EPBR_internalCDPRequest 0;
BA_ "Confidence" SG_ 552 EPBR_esmSpeedClass 0;
BA_ "Confidence" SG_ 552 EPBR_learnedEpbConfig 0;
BA_ "Confidence" SG_ 552 EPBR_internalStatusCounter 0;
BA_ "Confidence" SG_ 552 EPBR_internalStatusChecksum 0;
BA_ "Confidence" SG_ 742 EPBR_frontSeatCushionFanCur 0;
BA_ "Confidence" SG_ 742 EPBR_frontSeatBackrestFanCur 0;
BA_ "Confidence" SG_ 742 EPBR_frontSeatCushionFanDuty 0;
BA_ "Confidence" SG_ 742 EPBR_frontSeatCushionFanEn 0;
BA_ "Confidence" SG_ 742 EPBR_frontSeatBackrestFanEn 0;
BA_ "Confidence" SG_ 742 EPBR_frontSeatBackrestFanDuty 0;
BA_ "Confidence" SG_ 742 EPBR_seat2RControllerCurrent 0;
BA_ "Confidence" SG_ 744 EPBR_systemStatus 0;
BA_ "Confidence" SG_ 744 EPBR_freeRollModeStatus 0;
BA_ "Confidence" SG_ 744 EPBR_driverIsLeaving 0;
BA_ "Confidence" SG_ 744 EPBR_driverIsLeavingAnySpeed 0;
BA_ "Confidence" SG_ 744 EPBR_systemCdpAvailable 0;
BA_ "Confidence" SG_ 744 EPBR_chimeRequest 0;
BA_ "Confidence" SG_ 744 EPBR_telltale 0;
BA_ "GenSigSNA" SG_ 744 EPBR_telltale "7";
BA_ "Confidence" SG_ 744 EPBR_audioCurrentSpikeDetected 0;
BA_ "Confidence" SG_ 744 EPBR_redundantBrakingEnabled 0;
BA_ "Confidence" SG_ 744 EPBR_summonEnabled 0;
BA_ "Confidence" SG_ 744 EPBR_brakeLight 0;
BA_ "Confidence" SG_ 744 EPBR_epbConfigMismatch 0;
BA_ "Confidence" SG_ 744 EPBR_brakeConfirmedPressed 0;
BA_ "Confidence" SG_ 744 EPBR_requestUserConfirmation 0;
BA_ "Confidence" SG_ 744 EPBR_uiWinchModeMiscBlocking 0;
BA_ "Confidence" SG_ 744 EPBR_winchModeActive 0;
BA_ "Confidence" SG_ 744 EPBR_updateMode 0;
BA_ "Confidence" SG_ 744 EPBR_winchModePermissive 0;
BA_ "Confidence" SG_ 744 EPBR_winchModePending 0;
BA_ "Confidence" SG_ 744 EPBR_cdpRequest 0;
BA_ "Confidence" SG_ 744 EPBR_uiParkAvailable 0;
BA_ "Confidence" SG_ 744 EPBR_brakeDiscWipeRequest 0;
BA_ "GenSigSNA" SG_ 744 EPBR_brakeDiscWipeRequest "3";
BA_ "Confidence" SG_ 744 EPBR_showUiGearShifter 0;
BA_ "Confidence" SG_ 744 EPBR_uiWinchModeLvStatus 0;
BA_ "Confidence" SG_ 744 EPBR_contactorCycleNotNeededForW 0;
BA_ "SystemSignalLongSymbol" SG_ 744 EPBR_contactorCycleNotNeededForW "EPBR_contactorCycleNotNeededForWinchEntry";
BA_ "Confidence" SG_ 744 EPBR_autonomyBehavior 0;
BA_ "Confidence" SG_ 744 EPBR_showStalkFaultedOnUi 0;
BA_ "Confidence" SG_ 744 EPBR_espPowerRequest 0;
BA_ "Confidence" SG_ 744 EPBR_okToPark 0;
BA_ "Confidence" SG_ 744 EPBR_hornRequest 0;
BA_ "Confidence" SG_ 744 EPBR_winchModeAvailable 0;
BA_ "Confidence" SG_ 744 EPBR_bothDisconnected 0;
BA_ "Confidence" SG_ 744 EPBR_blockDrive 0;
BA_ "Confidence" SG_ 744 EPBR_statusCounter 0;
BA_ "Confidence" SG_ 744 EPBR_statusChecksum 0;
BA_ "Confidence" SG_ 1662 EVSE_isoTpToVehData 0;
BA_ "Confidence" SG_ 1322 FC_alertID 1;
BA_ "Confidence" SG_ 1322 FC_alertType 1;
BA_ "Confidence" SG_ 1322 FC_a146_CA_flybackOnTime 1;
BA_ "Confidence" SG_ 1322 FC_a146_CA_flybackV 1;
BA_ "Confidence" SG_ 1322 FC_a146_CA_flybackTargetV 1;
BA_ "Confidence" SG_ 1117 FC_evseBillingDataSelect 1;
BA_ "Confidence" SG_ 1117 FC_evseBillingEnergy 0;
BA_ "Confidence" SG_ 1117 FC_evseMeterPower 0;
BA_ "Confidence" SG_ 1117 FC_evseMeterCurrent 0;
BA_ "Confidence" SG_ 1117 FC_evseMeterVoltage 0;
BA_ "Confidence" SG_ 1117 FC_evseMeterFwGitHash 0;
BA_ "Confidence" SG_ 1334 FC_evseBilling2DataSelect 1;
BA_ "Confidence" SG_ 1334 FC_evsePpuEnabled 0;
BA_ "Confidence" SG_ 1334 FC_evseBillingEnergyHighRes 0;
BA_ "GenSigSNA" SG_ 1334 FC_evseBillingEnergyHighRes "16777215";
BA_ "Confidence" SG_ 1303 FC_id 0;
BA_ "Confidence" SG_ 1303 FC_sessionId 0;
BA_ "Confidence" SG_ 1310 FC_infoIndex 1;
BA_ "Confidence" SG_ 1310 FC_infoBuildType 0;
BA_ "Confidence" SG_ 1310 FC_infoBuildConfigID 0;
BA_ "Confidence" SG_ 1310 FC_infoHardwareID 0;
BA_ "Confidence" SG_ 1310 FC_infoComponentID 0;
BA_ "Confidence" SG_ 1310 FC_infoPcbaID 0;
BA_ "Confidence" SG_ 1310 FC_infoAssemblyID 0;
BA_ "Confidence" SG_ 1310 FC_infoUsageID 0;
BA_ "Confidence" SG_ 1310 FC_infoSubUsageID 0;
BA_ "Confidence" SG_ 1310 FC_infoApplicationCRC 0;
BA_ "Confidence" SG_ 1310 FC_infoAppGitHashBytes 0;
BA_ "Confidence" SG_ 1310 FC_infoBootGitHashBytes 0;
BA_ "Confidence" SG_ 1310 FC_infoPlatformType 0;
BA_ "Confidence" SG_ 1310 FC_infoMajorVersion 0;
BA_ "Confidence" SG_ 1310 FC_infoBranchOrigin 0;
BA_ "Confidence" SG_ 1310 FC_infoMaturity 0;
BA_ "Confidence" SG_ 1310 FC_infoHardwareRevision 0;
BA_ "Confidence" SG_ 1310 FC_partNumChar01 0;
BA_ "Confidence" SG_ 1310 FC_partNumChar02 0;
BA_ "Confidence" SG_ 1310 FC_partNumChar03 0;
BA_ "Confidence" SG_ 1310 FC_partNumChar04 0;
BA_ "Confidence" SG_ 1310 FC_partNumChar05 0;
BA_ "Confidence" SG_ 1310 FC_partNumChar06 0;
BA_ "Confidence" SG_ 1310 FC_partNumChar07 0;
BA_ "Confidence" SG_ 1310 FC_partNumChar08 0;
BA_ "Confidence" SG_ 1310 FC_partNumChar09 0;
BA_ "Confidence" SG_ 1310 FC_partNumChar10 0;
BA_ "Confidence" SG_ 1310 FC_partNumChar11 0;
BA_ "Confidence" SG_ 1310 FC_partNumChar12 0;
BA_ "Confidence" SG_ 1310 FC_partNumChar13 0;
BA_ "Confidence" SG_ 1310 FC_partNumChar14 0;
BA_ "Confidence" SG_ 1310 FC_partNumChar15 0;
BA_ "Confidence" SG_ 1310 FC_partNumChar16 0;
BA_ "Confidence" SG_ 1310 FC_partNumChar17 0;
BA_ "Confidence" SG_ 1310 FC_partNumChar18 0;
BA_ "Confidence" SG_ 1310 FC_partNumChar19 0;
BA_ "Confidence" SG_ 1310 FC_partNumChar20 0;
BA_ "Confidence" SG_ 580 FC_powerLimit 0;
BA_ "GenSigSNA" SG_ 580 FC_powerLimit "8191";
BA_ "Confidence" SG_ 580 FC_currentLimit 0;
BA_ "GenSigSNA" SG_ 580 FC_currentLimit "8191";
BA_ "Confidence" SG_ 580 FC_maxVoltageLimit 0;
BA_ "GenSigSNA" SG_ 580 FC_maxVoltageLimit "8191";
BA_ "Confidence" SG_ 580 FC_minVoltageLimit 0;
BA_ "GenSigSNA" SG_ 580 FC_minVoltageLimit "8191";
BA_ "Confidence" SG_ 702 FC_powerLimit_value 0;
BA_ "GenSigSNA" SG_ 702 FC_powerLimit_value "32768";
BA_ "Confidence" SG_ 702 FC_currentLimit_value 0;
BA_ "GenSigSNA" SG_ 702 FC_currentLimit_value "32768";
BA_ "Confidence" SG_ 702 FC_minVoltageLimit_value 0;
BA_ "GenSigSNA" SG_ 702 FC_minVoltageLimit_value "32768";
BA_ "Confidence" SG_ 702 FC_powerLimit_exp 0;
BA_ "Confidence" SG_ 702 FC_currentLimit_exp 0;
BA_ "Confidence" SG_ 702 FC_minVoltageLimit_exp 0;
BA_ "Confidence" SG_ 1345 FC_maxPowerLimit 0;
BA_ "GenSigSNA" SG_ 1345 FC_maxPowerLimit "8191";
BA_ "Confidence" SG_ 1345 FC_maxCurrentLimit 0;
BA_ "GenSigSNA" SG_ 1345 FC_maxCurrentLimit "8191";
BA_ "Confidence" SG_ 1300 FC_serialDataSelect 1;
BA_ "Confidence" SG_ 1300 FC_serialChar01 0;
BA_ "Confidence" SG_ 1300 FC_serialChar02 0;
BA_ "Confidence" SG_ 1300 FC_serialChar03 0;
BA_ "Confidence" SG_ 1300 FC_serialChar04 0;
BA_ "Confidence" SG_ 1300 FC_serialChar05 0;
BA_ "Confidence" SG_ 1300 FC_serialChar06 0;
BA_ "Confidence" SG_ 1300 FC_serialChar07 0;
BA_ "Confidence" SG_ 1300 FC_serialChar08 0;
BA_ "Confidence" SG_ 1300 FC_serialChar09 0;
BA_ "Confidence" SG_ 1300 FC_serialChar10 0;
BA_ "Confidence" SG_ 1300 FC_serialChar11 0;
BA_ "Confidence" SG_ 1300 FC_serialChar12 0;
BA_ "Confidence" SG_ 1300 FC_serialChar13 0;
BA_ "Confidence" SG_ 1300 FC_serialChar14 0;
BA_ "Confidence" SG_ 1300 FC_serialChar15 0;
BA_ "Confidence" SG_ 1300 FC_serialChar16 0;
BA_ "Confidence" SG_ 1300 FC_serialChar17 0;
BA_ "Confidence" SG_ 532 FC_protocolVersion 0;
BA_ "Confidence" SG_ 532 FC_statusCode 0;
BA_ "GenSigSNA" SG_ 532 FC_statusCode "0";
BA_ "Confidence" SG_ 532 FC_deprecated1 0;
BA_ "Confidence" SG_ 532 FC_deprecated2 0;
BA_ "Confidence" SG_ 532 FC_deprecated3 0;
BA_ "Confidence" SG_ 532 FC_adapterLocked 0;
BA_ "Confidence" SG_ 532 FC_minCurrentLimit 0;
BA_ "Confidence" SG_ 532 FC_type 0;
BA_ "GenSigSNA" SG_ 532 FC_type "7";
BA_ "Confidence" SG_ 532 FC_dcCurrent 0;
BA_ "Confidence" SG_ 532 FC_postID 0;
BA_ "GenSigSNA" SG_ 532 FC_postID "3";
BA_ "Confidence" SG_ 532 FC_dcVoltage 0;
BA_ "Confidence" SG_ 532 FC_leakageTestNotSupported 0;
BA_ "Confidence" SG_ 532 FC_dischargeSupported 0;
BA_ "Confidence" SG_ 533 FC_externalIsolationResistance 0;
BA_ "GenSigSNA" SG_ 533 FC_externalIsolationResistance "255";
BA_ "Confidence" SG_ 535 FC_status3DataSelect 1;
BA_ "Confidence" SG_ 535 FC_status3DummySig 0;
BA_ "Confidence" SG_ 535 FC_class 0;
BA_ "GenSigSNA" SG_ 535 FC_class "0";
BA_ "Confidence" SG_ 535 FC_brand 0;
BA_ "GenSigSNA" SG_ 535 FC_brand "0";
BA_ "Confidence" SG_ 535 FC_coolingType 0;
BA_ "GenSigSNA" SG_ 535 FC_coolingType "0";
BA_ "Confidence" SG_ 535 FC_uiStopType 0;
BA_ "GenSigSNA" SG_ 535 FC_uiStopType "0";
BA_ "Confidence" SG_ 535 FC_emergencyShutdownSupported 0;
BA_ "Confidence" SG_ 535 FC_generation 0;
BA_ "GenSigSNA" SG_ 535 FC_generation "0";
BA_ "Confidence" SG_ 1650 VC_hcmlInfoIndex 1;
BA_ "Confidence" SG_ 1650 VC_infoHCMLBuildConfigId 0;
BA_ "Confidence" SG_ 1650 VC_leftHeadlampLMMVariant 0;
BA_ "GenSigSNA" SG_ 1650 VC_leftHeadlampLMMVariant "0";
BA_ "Confidence" SG_ 1650 VC_infoHCMLAssemblyId 0;
BA_ "Confidence" SG_ 1650 VC_infoHCMLPcbaId 0;
BA_ "Confidence" SG_ 1650 VC_infoHCMLUsageId 0;
BA_ "Confidence" SG_ 1980 VC_hcmrInfoIndex 1;
BA_ "Confidence" SG_ 1980 VC_infoHCMRBuildConfigId 0;
BA_ "Confidence" SG_ 1980 VC_rightHeadlampLMMVariant 0;
BA_ "GenSigSNA" SG_ 1980 VC_rightHeadlampLMMVariant "0";
BA_ "Confidence" SG_ 1980 VC_infoHCMRAssemblyId 0;
BA_ "Confidence" SG_ 1980 VC_infoHCMRPcbaId 0;
BA_ "Confidence" SG_ 1980 VC_infoHCMRUsageId 0;
BA_ "Confidence" SG_ 1290 HVP_alertID 1;
BA_ "Confidence" SG_ 1290 HVP_alertSet 1;
BA_ "Confidence" SG_ 1290 HVP_a005_current 1;
BA_ "Confidence" SG_ 1290 HVP_a006_current 1;
BA_ "Confidence" SG_ 1290 HVP_a007_current 1;
BA_ "Confidence" SG_ 1290 HVP_a008_temperature 1;
BA_ "Confidence" SG_ 1290 HVP_a009_brickVoltage 1;
BA_ "Confidence" SG_ 1290 HVP_a010_brickVoltage 1;
BA_ "Confidence" SG_ 1290 HVP_a012_bmbCommStatusTypeA 1;
BA_ "Confidence" SG_ 1290 HVP_a012_bmbCommStatusTypeB 1;
BA_ "Confidence" SG_ 1290 HVP_a013_bmbCommStatusTypeA 1;
BA_ "Confidence" SG_ 1290 HVP_a013_bmbCommStatusTypeB 1;
BA_ "Confidence" SG_ 1290 HVP_a013_bmbChainBreakType 1;
BA_ "Confidence" SG_ 1290 HVP_a018_dcLinkVoltage 1;
BA_ "Confidence" SG_ 1290 HVP_a018_battery12V 1;
BA_ "SystemSignalLongSymbol" SG_ 1290 HVP_a018_remainingPcsPowerCycles "HVP_a018_remainingPcsPowerCyclesAllowed";
BA_ "SystemSignalLongSymbol" SG_ 1290 HVP_a018_remainingPcsRecoveriesA "HVP_a018_remainingPcsRecoveriesAllowed";
BA_ "SystemSignalLongSymbol" SG_ 1290 HVP_a018_hvcHardwareSupportsCycl "HVP_a018_hvcHardwareSupportsCycling";
BA_ "SystemSignalLongSymbol" SG_ 1290 HVP_a018_pcsHardwareOkToBePowerC "HVP_a018_pcsHardwareOkToBePowerCycled";
BA_ "Confidence" SG_ 1290 HVP_a020_energyReserveV 1;
BA_ "GenSigSNA" SG_ 1290 HVP_a020_energyReserveV "65535";
BA_ "Confidence" SG_ 1290 HVP_a020_shuntCurrentAux 1;
BA_ "GenSigSNA" SG_ 1290 HVP_a020_shuntCurrentAux "32768";
BA_ "Confidence" SG_ 1290 HVP_a020_shuntTemperature 1;
BA_ "GenSigSNA" SG_ 1290 HVP_a020_shuntTemperature "32768";
BA_ "Confidence" SG_ 1290 HVP_a021_pyroStatus 1;
BA_ "SystemSignalLongSymbol" SG_ 1290 HVP_a021_HighSideSwitchTestFaile "HVP_a021_HighSideSwitchTestFailed";
BA_ "Confidence" SG_ 1290 HVP_a021_SquibResistance 1;
BA_ "GenSigSNA" SG_ 1290 HVP_a021_SquibResistance "65535";
BA_ "Confidence" SG_ 1290 HVP_a021_Aout 1;
BA_ "GenSigSNA" SG_ 1290 HVP_a021_Aout "16383";
BA_ "Confidence" SG_ 1290 HVP_a022_pyroStatus 1;
BA_ "Confidence" SG_ 1290 HVP_a022_Aout 1;
BA_ "GenSigSNA" SG_ 1290 HVP_a022_Aout "16383";
BA_ "Confidence" SG_ 1290 HVP_a022_SquibResistance 1;
BA_ "GenSigSNA" SG_ 1290 HVP_a022_SquibResistance "65535";
BA_ "Confidence" SG_ 1290 HVP_a024_voltage 1;
BA_ "Confidence" SG_ 1290 HVP_a025_voltage1 1;
BA_ "Confidence" SG_ 1290 HVP_a025_voltage2 1;
BA_ "Confidence" SG_ 1290 HVP_a025_packVoltage 1;
BA_ "Confidence" SG_ 1290 HVP_a026_hvilStatus 1;
BA_ "GenSigSNA" SG_ 1290 HVP_a026_hvilStatus "14";
BA_ "Confidence" SG_ 1290 HVP_a026_inputVoltage 1;
BA_ "Confidence" SG_ 1290 HVP_a026_outputVoltage 1;
BA_ "Confidence" SG_ 1290 HVP_a026_internalVoltage 1;
BA_ "GenSigSNA" SG_ 1290 HVP_a026_internalVoltage "255";
BA_ "Confidence" SG_ 1290 HVP_a026_dirVoltage 1;
BA_ "GenSigSNA" SG_ 1290 HVP_a026_dirVoltage "255";
BA_ "Confidence" SG_ 1290 HVP_a026_difVoltage 1;
BA_ "GenSigSNA" SG_ 1290 HVP_a026_difVoltage "255";
BA_ "Confidence" SG_ 1290 HVP_a028_packVoltage 1;
BA_ "Confidence" SG_ 1290 HVP_a028_sumOfBrickV 1;
BA_ "Confidence" SG_ 1290 HVP_a030_packPositiveLinkV 1;
BA_ "Confidence" SG_ 1290 HVP_a030_dcPositiveLinkV 1;
BA_ "Confidence" SG_ 1290 HVP_a031_packNegativeLinkV 1;
BA_ "Confidence" SG_ 1290 HVP_a031_dcNegativeLinkV 1;
BA_ "Confidence" SG_ 1290 HVP_a033_contactorPowerV 1;
BA_ "Confidence" SG_ 1290 HVP_a033_coilCurrent 1;
BA_ "Confidence" SG_ 1290 HVP_a033_pwmDutyCylePositive 1;
BA_ "Confidence" SG_ 1290 HVP_a033_pwmDutyCyleNegative 1;
BA_ "Confidence" SG_ 1290 HVP_a035_contactorPowerV 1;
BA_ "Confidence" SG_ 1290 HVP_a035_coilCurrent 1;
BA_ "Confidence" SG_ 1290 HVP_a035_pwmDutyCylePositive 1;
BA_ "Confidence" SG_ 1290 HVP_a035_pwmDutyCyleNegative 1;
BA_ "Confidence" SG_ 1290 HVP_a036_pyroFiringHandle 1;
BA_ "Confidence" SG_ 1290 HVP_a037_pyroFiringHandle 1;
BA_ "Confidence" SG_ 1290 HVP_a040_powerVoltage 1;
BA_ "Confidence" SG_ 1290 HVP_a040_coilCurrent 1;
BA_ "Confidence" SG_ 1290 HVP_a040_posCtrVoltageDrop 1;
BA_ "Confidence" SG_ 1290 HVP_a040_negCtrVoltageDrop 1;
BA_ "Confidence" SG_ 1290 HVP_a045_dcLinkVoltage 1;
BA_ "Confidence" SG_ 1290 HVP_a046_shuntCurrent 1;
BA_ "Confidence" SG_ 1290 HVP_a046_shuntTemperature 1;
BA_ "Confidence" SG_ 1290 HVP_a046_asicTemperature 1;
BA_ "Confidence" SG_ 1290 HVP_a047_shuntCurrent 1;
BA_ "Confidence" SG_ 1290 HVP_a047_auxCurrent 1;
BA_ "Confidence" SG_ 1290 HVP_a049_contactorPowerV 1;
BA_ "Confidence" SG_ 1290 HVP_a049_coilCurrent 1;
BA_ "Confidence" SG_ 1290 HVP_a049_posCtrState 1;
BA_ "GenSigSNA" SG_ 1290 HVP_a049_posCtrState "0";
BA_ "Confidence" SG_ 1290 HVP_a049_negCtrState 1;
BA_ "GenSigSNA" SG_ 1290 HVP_a049_negCtrState "0";
BA_ "Confidence" SG_ 1290 HVP_a050_contactorPowerV 1;
BA_ "Confidence" SG_ 1290 HVP_a050_coilCurrent 1;
BA_ "Confidence" SG_ 1290 HVP_a050_posCtrState 1;
BA_ "GenSigSNA" SG_ 1290 HVP_a050_posCtrState "0";
BA_ "Confidence" SG_ 1290 HVP_a050_negCtrState 1;
BA_ "GenSigSNA" SG_ 1290 HVP_a050_negCtrState "0";
BA_ "Confidence" SG_ 1290 HVP_a051_shuntTemperature 1;
BA_ "GenSigSNA" SG_ 1290 HVP_a051_shuntTemperature "32768";
BA_ "Confidence" SG_ 1290 HVP_a051_shuntCurrent 1;
BA_ "GenSigSNA" SG_ 1290 HVP_a051_shuntCurrent "32768";
BA_ "Confidence" SG_ 1290 HVP_a051_energyReserveV 1;
BA_ "GenSigSNA" SG_ 1290 HVP_a051_energyReserveV "65535";
BA_ "Confidence" SG_ 1290 HVP_a053_packVoltage 1;
BA_ "Confidence" SG_ 1290 HVP_a053_dcLinkVoltage 1;
BA_ "Confidence" SG_ 1290 HVP_a056_diagnosis 1;
BA_ "GenSigSNA" SG_ 1290 HVP_a056_diagnosis "0";
BA_ "Confidence" SG_ 1290 HVP_a056_shuntCurrent 1;
BA_ "Confidence" SG_ 1290 HVP_a056_posPackContactorState 1;
BA_ "GenSigSNA" SG_ 1290 HVP_a056_posPackContactorState "0";
BA_ "Confidence" SG_ 1290 HVP_a056_negPackContactorState 1;
BA_ "GenSigSNA" SG_ 1290 HVP_a056_negPackContactorState "0";
BA_ "Confidence" SG_ 1290 HVP_a056_posFcContactorState 1;
BA_ "GenSigSNA" SG_ 1290 HVP_a056_posFcContactorState "0";
BA_ "Confidence" SG_ 1290 HVP_a056_negFcContactorState 1;
BA_ "GenSigSNA" SG_ 1290 HVP_a056_negFcContactorState "0";
BA_ "Confidence" SG_ 1290 HVP_a058_VrefSample 1;
BA_ "Confidence" SG_ 1290 HVP_a058_VrefStatus 1;
BA_ "Confidence" SG_ 1290 HVP_a058_VrefType 1;
BA_ "Confidence" SG_ 1290 HVP_a060_stackVoltage 1;
BA_ "Confidence" SG_ 1290 HVP_a060_sumBrickVoltage 1;
BA_ "Confidence" SG_ 1290 HVP_a067_hvilTypeFromHvp 1;
BA_ "Confidence" SG_ 1290 HVP_a067_hvilTypeFromGateway 1;
BA_ "Confidence" SG_ 1290 HVP_a068_shuntTemperature 1;
BA_ "GenSigSNA" SG_ 1290 HVP_a068_shuntTemperature "32768";
BA_ "Confidence" SG_ 1290 HVP_a068_shuntCurrent 1;
BA_ "GenSigSNA" SG_ 1290 HVP_a068_shuntCurrent "32768";
BA_ "Confidence" SG_ 1290 HVP_a068_energyReserveV 1;
BA_ "GenSigSNA" SG_ 1290 HVP_a068_energyReserveV "65535";
BA_ "Confidence" SG_ 938 HVP_matrixIndex 1;
BA_ "SystemSignalLongSymbol" SG_ 938 HVP_w048_swUnsupportedBmbAsicTyp "HVP_w048_swUnsupportedBmbAsicType";
BA_ "SystemSignalLongSymbol" SG_ 938 HVP_w053_hvVoltageSensorRational "HVP_w053_hvVoltageSensorRationality";
BA_ "SystemSignalLongSymbol" SG_ 938 HVP_w068_shuntUnexpectedThermist "HVP_w068_shuntUnexpectedThermistor";
BA_ "SystemSignalLongSymbol" SG_ 938 HVP_w071_PassivePyroVrefRational "HVP_w071_PassivePyroVrefRationality";
BA_ "Confidence" SG_ 522 HVP_packContNegativeState 0;
BA_ "GenSigSNA" SG_ 522 HVP_packContNegativeState "0";
BA_ "Confidence" SG_ 522 HVP_packContPositiveState 0;
BA_ "GenSigSNA" SG_ 522 HVP_packContPositiveState "0";
BA_ "Confidence" SG_ 522 HVP_fcContPositiveAuxOpen 0;
BA_ "Confidence" SG_ 522 HVP_fcContNegativeAuxOpen 0;
BA_ "Confidence" SG_ 522 HVP_packContactorSetState 0;
BA_ "GenSigSNA" SG_ 522 HVP_packContactorSetState "0";
BA_ "Confidence" SG_ 522 HVP_fcContNegativeState 0;
BA_ "GenSigSNA" SG_ 522 HVP_fcContNegativeState "0";
BA_ "Confidence" SG_ 522 HVP_contactorsBlocked 0;
BA_ "Confidence" SG_ 522 HVP_fcContPositiveState 0;
BA_ "GenSigSNA" SG_ 522 HVP_fcContPositiveState "0";
BA_ "Confidence" SG_ 522 HVP_fcContactorSetState 0;
BA_ "GenSigSNA" SG_ 522 HVP_fcContactorSetState "0";
BA_ "Confidence" SG_ 522 HVP_fcCtrsRequestStatus 0;
BA_ "Confidence" SG_ 522 HVP_fcCtrsResetRequestRequired 0;
BA_ "Confidence" SG_ 522 HVP_fcCtrsOpenNowRequested 0;
BA_ "Confidence" SG_ 522 HVP_fcCtrsOpenRequested 0;
BA_ "Confidence" SG_ 522 HVP_fcCtrsClosingAllowed 0;
BA_ "Confidence" SG_ 522 HVP_packCtrsRequestStatus 0;
BA_ "Confidence" SG_ 522 HVP_packCtrsResetRequestRequired 0;
BA_ "Confidence" SG_ 522 HVP_packCtrsOpenNowRequested 0;
BA_ "Confidence" SG_ 522 HVP_packCtrsOpenRequested 0;
BA_ "Confidence" SG_ 522 HVP_packCtrsClosingAllowed 0;
BA_ "Confidence" SG_ 522 HVP_dcLinkAllowedToEnergize 0;
BA_ "Confidence" SG_ 522 HVP_pyroTestInProgress 0;
BA_ "Confidence" SG_ 522 HVP_hvilDiag 0;
BA_ "GenSigSNA" SG_ 522 HVP_hvilDiag "14";
BA_ "Confidence" SG_ 522 HVP_fcLinkAllowedToEnergize 0;
BA_ "Confidence" SG_ 1962 HVP_debugMessageMultiplexer 1;
BA_ "Confidence" SG_ 1962 HVP_ecuLogUploadRequest 0;
BA_ "Confidence" SG_ 1962 HVP_dcLinkVoltage 0;
BA_ "Confidence" SG_ 1962 HVP_packVoltage 0;
BA_ "Confidence" SG_ 1962 HVP_fcLinkVoltage 0;
BA_ "Confidence" SG_ 1962 HVP_10HzTask_stackUsage 0;
BA_ "Confidence" SG_ 1962 HVP_packContVoltage 0;
BA_ "Confidence" SG_ 1962 HVP_packNegativeV 0;
BA_ "Confidence" SG_ 1962 HVP_packPositiveV 0;
BA_ "Confidence" SG_ 1962 HVP_pyroAnalog 0;
BA_ "Confidence" SG_ 1962 HVP_shuntSetTCRCoeffA 0;
BA_ "Confidence" SG_ 1962 HVP_shuntSetTCRCoeffB 0;
BA_ "Confidence" SG_ 1962 HVP_shuntSetTCRCoeffC 0;
BA_ "Confidence" SG_ 1962 HVP_shuntSetTCRCoeffD 0;
BA_ "Confidence" SG_ 1962 HVP_fcContCoilCurrent 0;
BA_ "Confidence" SG_ 1962 HVP_fcContVoltage 0;
BA_ "Confidence" SG_ 1962 HVP_hvilInVoltage 0;
BA_ "Confidence" SG_ 1962 HVP_hvilOutVoltage 0;
BA_ "Confidence" SG_ 1962 HVP_shuntGainInvalidCountDbg 0;
BA_ "Confidence" SG_ 1962 HVP_passivePyroRefVoltageMax 0;
BA_ "GenSigSNA" SG_ 1962 HVP_passivePyroRefVoltageMax "1023";
BA_ "Confidence" SG_ 1962 HVP_passivePyroRefVoltageMin 0;
BA_ "GenSigSNA" SG_ 1962 HVP_passivePyroRefVoltageMin "1023";
BA_ "Confidence" SG_ 1962 HVP_packContCoilCurrent 0;
BA_ "Confidence" SG_ 1962 HVP_battery12V 0;
BA_ "Confidence" SG_ 1962 HVP_fcLinkPositiveV 0;
BA_ "Confidence" SG_ 554 HVP_dcLinkVoltageRequest 0;
BA_ "Confidence" SG_ 554 HVP_pcsControlRequest 0;
BA_ "Confidence" SG_ 554 HVP_pcsChargeHwEnabled 0;
BA_ "Confidence" SG_ 554 HVP_pcsDcdcHwEnabled 0;
BA_ "Confidence" SG_ 554 HVP_dcLinkVoltageFiltered 0;
BA_ "GenSigSNA" SG_ 554 HVP_dcLinkVoltageFiltered "1498";
BA_ "Confidence" SG_ 784 HVP_infoIndex 1;
BA_ "Confidence" SG_ 784 HVP_buildType 0;
BA_ "Confidence" SG_ 784 HVP_buildConfigId 0;
BA_ "Confidence" SG_ 784 HVP_hardwareId 0;
BA_ "Confidence" SG_ 784 HVP_componentId 0;
BA_ "Confidence" SG_ 784 HVP_pcbaId 0;
BA_ "Confidence" SG_ 784 HVP_assemblyId 0;
BA_ "Confidence" SG_ 784 HVP_usageId 0;
BA_ "Confidence" SG_ 784 HVP_subUsageId 0;
BA_ "Confidence" SG_ 784 HVP_platformType 0;
BA_ "Confidence" SG_ 784 HVP_appCrc 0;
BA_ "Confidence" SG_ 784 HVP_appGitHash 0;
BA_ "Confidence" SG_ 784 HVP_bootGitHash 0;
BA_ "Confidence" SG_ 784 HVP_bootUdsProtoVersion 0;
BA_ "Confidence" SG_ 784 HVP_bootCrc 0;
VAL_ 1000 EPBR_matrixIndex 6 "AlertMatrix6" 5 "AlertMatrix5" 4 "AlertMatrix4" 3 "AlertMatrix3" 2 "AlertMatrix2" 1 "AlertMatrix1" 0 "AlertMatrix0" ;
VAL_ 2024 EPBR_infoIndex 255 "END" 41 "SUBCOMPONENT14" 40 "SUBCOMPONENT13" 39 "SUBCOMPONENT12" 38 "SUBCOMPONENT11" 37 "SUBCOMPONENT10" 36 "SUBCOMPONENT9" 35 "SUBCOMPONENT8" 34 "SUBCOMPONENT7" 33 "SUBCOMPONENT6" 32 "SUBCOMPONENT5" 31 "SUBCOMPONENT4" 24 "SUBCOMPONENT3" 23 "SUBCOMPONENT2" 20 "UDS_PROTOCOL_BOOTCRC" 19 "VERSION_DEPRECATED" 18 "BOOTLOADER_GITHASH" 17 "APP_GITHASH" 16 "SUBCOMPONENT1" 15 "BOOTLOADER_CRC" 14 "BOOTLOADER_SVN" 13 "APP_CRC" 11 "PCBAID_ASSYID_USAGEID" 10 "BUILD_HWID_COMPONENTID" 9 "DEPRECATED_9" 8 "DEPRECATED_8" 7 "DEPRECATED_7" 6 "DEPRECATED_6" 5 "DEPRECATED_5" 4 "DEPRECATED_4" 3 "DEPRECATED_3" 2 "DEPRECATED_2" 1 "DEPRECATED_1" 0 "DEPRECATED_0" ;
VAL_ 2024 EPBR_infoBuildType 4 "INFO_MFG_BUILD" 3 "INFO_TRACEABLE_CI_BUILD" 2 "INFO_LOCAL_BUILD" 1 "INFO_PLATFORM_BUILD" 0 "INFO_UNKNOWN_BUILD" ;
VAL_ 2024 EPBR_infoAssemblyId 255 "ASSEMBLY_SNA" 1 "ASSEMBLY1" ;
VAL_ 552 EPBR_unitStatus 23 "EPB_STATUS_COUNT" 22 "EPB_STATUS_AUTONOMY_OPEN" 21 "EPB_STATUS_FREE_ROLL_MODE" 20 "EPB_STATUS_DYNAMIC_PARKING" 19 "EPB_STATUS_EXTERNAL_PARKING" 18 "EPB_STATUS_RELEASING_FOR_EXTERNAL_PARK" 17 "EPB_STATUS_EXTERNAL_DYNAMIC" 16 "EPB_STATUS_SUMMON_PARKING" 15 "EPB_STATUS_SUMMON_RELEASING" 14 "EPB_STATUS_SUMMON" 13 "EPB_STATUS_WINCHMODE_PENDING" 12 "EPB_STATUS_PARK_PENDING" 11 "EPB_STATUS_SERVICE_RELEASING" 10 "EPB_STATUS_RELEASING" 9 "EPB_STATUS_DYNAMIC_APPLYING" 8 "EPB_STATUS_PARKING" 7 "EPB_STATUS_WINCHMODE_RELEASING" 6 "EPB_STATUS_WINCHMODE" 5 "EPB_STATUS_SERVICE" 4 "EPB_STATUS_START" 3 "EPB_STATUS_PARK" 2 "EPB_STATUS_DYNAMIC" 1 "EPB_STATUS_OPEN" 0 "EPB_STATUS_UNKNOWN" ;
VAL_ 552 EPBR_unitFaultStatus 3 "EPB_STATUS_FAULT_IDLE" 2 "EPB_STATUS_FAULT" 1 "EPB_STATUS_RETRY" 0 "EPB_STATUS_NOMINAL" ;
VAL_ 552 EPBR_summonState 6 "EPB_SUMMON_UNAVAILABLE" 5 "EPB_SUMMON_FAULT" 4 "EPB_SUMMON_COMPLETE" 3 "EPB_SUMMON_ACTIVE" 2 "EPB_SUMMON_ARMED" 1 "EPB_SUMMON_IDLE" 0 "EPB_SUMMON_INIT" ;
VAL_ 552 EPBR_csmFaultReason 23 "CSM_FAULT_REMOTE_MIA" 22 "CSM_FAULT_NVM_MISMATCH" 21 "CSM_FAULT_EPBM_MIA" 20 "CSM_FAULT_MOTOR_NOT_READY" 19 "CSM_FAULT_MOTOR_ACTIVE_FAULT" 18 "CSM_FAULT_MOTOR_IDLE_FAULT" 17 "CSM_FAULT_TIMEOUT_EPBM_START" 16 "CSM_FAULT_TIMEOUT_NO_RAMP" 15 "CSM_FAULT_TIMEOUT_EPBM_CUTOFF" 14 "CSM_FAULT_TIMEOUT_RELEASE_COMPLETE" 13 "CSM_FAULT_TIMEOUT_RELEASE_NO_LOAD" 12 "CSM_FAULT_TIMEOUT_RELEASE_WAIT_FOR_ENDSTOP" 11 "CSM_FAULT_TIMEOUT_RELEASE_INRUSH" 10 "CSM_FAULT_TIMEOUT_EPBM_WAIT_FOR_CLAMP" 9 "CSM_FAULT_TIMEOUT_EPB_WAIT_FOR_CLAMP" 8 "CSM_FAULT_TIMEOUT_APPLY_INRUSH" 7 "CSM_FAULT_TIMEOUT_APPLY_COMPLETE" 6 "CSM_FAULT_RELEASE_BLOCKED" 5 "CSM_FAULT_APPLY_BLOCKED" 4 "CSM_FAULT_TIMEOUT_CALIBRATE" 3 "CSM_FAULT_STATE_MISMATCH" 2 "CSM_FAULT_EPBM_FAULTED" 1 "CSM_FAULT_EPBM_DISABLED" 0 "CSM_FAULT_NONE" ;
VAL_ 552 EPBR_esmOperationTrigger 50 "EPB_TRIGGER_ACTIVE_DECEL_DAS_STATIC" 49 "EPB_TRIGGER_ACTIVE_DECEL_CDP_DOWN" 48 "EPB_TRIGGER_AP_IS_LEAVING" 47 "EPB_TRIGGER_RECOVERY_PARK" 46 "EPB_TRIGGER_SPEED_SOURCES_LOST" 45 "EPB_TRIGGER_ACTIVE_DECEL_OKTOPARK" 44 "EPB_TRIGGER_ACTIVE_DECEL_FAST" 43 "EPB_TRIGGER_STEERING_ACTIVE_DECEL" 42 "EPB_TRIGGER_LV_ACTIVE_DECEL" 41 "EPB_TRIGGER_CDP_PANIC_MODE_READY" 40 "EPB_TRIGGER_CDP_PANIC_MODE_TIMEOUT" 39 "EPB_TRIGGER_DI_PARK" 38 "EPB_TRIGGER_FREE_ROLL_PARK_FOR_HANDLE_PULLED" 37 "EPB_TRIGGER_LOW_BRAKE_FLUID_MODE_DYNAMIC" 36 "EPB_TRIGGER_LOW_BRAKE_FLUID_MODE_DYNAMIC_PARK" 35 "EPB_TRIGGER_LOW_BRAKE_FLUID_MODE_PARK" 34 "EPB_TRIGGER_STATIONARY_DETECT" 33 "EPB_TRIGGER_TOUCHSCREEN_INVALID" 32 "EPB_TRIGGER_UI_DOOR_OPEN_REQUEST" 31 "EPB_TRIGGER_AUTOPARK_END" 30 "EPB_TRIGGER_DRIVER_IS_LEAVING" 29 "EPB_TRIGGER_SYSTEM_APPLY" 28 "EPB_TRIGGER_ACCELERATION" 27 "EPB_TRIGGER_EPBM_DISQUALIFIED" 26 "EPB_TRIGGER_DISQUALIFIED" 25 "EPB_TRIGGER_SUMMON_FAULT" 24 "EPB_TRIGGER_FAULT" 23 "EPB_TRIGGER_SUMMON_COMPLETE" 22 "EPB_TRIGGER_REAPPLY" 21 "EPB_TRIGGER_SAVESTATE_ON_BOOT" 20 "EPB_TRIGGER_TIMEOUT" 19 "EPB_TRIGGER_SPEED_FAST" 18 "EPB_TRIGGER_SPEED_OKAYTOPARK" 17 "EPB_TRIGGER_SPEED_STOPPED" 16 "EPB_TRIGGER_USER_CANCEL" 15 "EPB_TRIGGER_USER_CONFIRMED" 14 "EPB_TRIGGER_DIAG_EXIT" 13 "EPB_TRIGGER_DIAG_OPEN" 12 "EPB_TRIGGER_DIAG_CLOSE" 11 "EPB_TRIGGER_SERVICE" 10 "EPB_TRIGGER_WINCHMODE_UNAVAILABLE" 9 "EPB_TRIGGER_WINCHMODE_ENTER" 8 "EPB_TRIGGER_WINCHMODE_EXIT" 7 "EPB_TRIGGER_TOUCHSCREEN" 6 "EPB_TRIGGER_DI_UNPARK" 5 "EPB_TRIGGER_ACTIVE_PARK_REQUEST" 4 "EPB_TRIGGER_PBUTTON_RELEASED" 3 "EPB_TRIGGER_PBUTTON_PRESSED_UNKNOWN" 2 "EPB_TRIGGER_PBUTTON_PRESSED_FAST" 1 "EPB_TRIGGER_PBUTTON_PRESSED_OKTOPARK" 0 "EPB_TRIGGER_PBUTTON_PRESSED_STOPPED" ;
VAL_ 552 EPBR_summonFaultReason 30 "EPB_SUMMONFAULT_MONITOR_TYPE_UNKNOWN" 29 "EPB_SUMMONFAULT_AP_MONITOR" 28 "EPB_SUMMONFAULT_REMOTE_DID_NOT_START" 27 "EPB_SUMMONFAULT_INVALID_REMOTE_STATE" 26 "EPB_SUMMONFAULT_START_IN_UNAVAILABLE" 25 "EPB_SUMMONFAULT_REMOTE_UNIT_FAULTED" 24 "EPB_SUMMONFAULT_LOCAL_UNIT_FAULTED" 23 "EPB_SUMMONFAULT_REMOTE_SUMMON_FAULTED" 22 "EPB_SUMMONFAULT_EPBREMOTE_MIA" 21 "EPB_SUMMONFAULT_PASSIVE_REQUEST" 20 "EPB_SUMMONFAULT_DI_STATE_INVALID" 19 "EPB_SUMMONFAULT_EPB_FAULT" 18 "EPB_SUMMONFAULT_MISMATCH" 17 "EPB_SUMMONFAULT_OOC" 16 "EPB_SUMMONFAULT_PM_REQUEST" 15 "EPB_SUMMONFAULT_PM_MIA" 14 "EPB_SUMMONFAULT_PARK_MIA" 13 "EPB_SUMMONFAULT_EXTERNAL" 12 "EPB_SUMMONFAULT_SPEED" 11 "EPB_SUMMONFAULT_EPBM_REQUEST" 10 "EPB_SUMMONFAULT_EAC_NOT_ALLOWED" 9 "EPB_SUMMONFAULT_VEH_CAN_FAULT" 8 "EPB_SUMMONFAULT_ESP_FAULT" 7 "EPB_SUMMONFAULT_DAS_FAULT" 6 "EPB_SUMMONFAULT_DI_APC_FAULT" 5 "EPB_SUMMONFAULT_DI_FAULT" 4 "EPB_SUMMONFAULT_EPBM_MIA" 3 "EPB_SUMMONFAULT_ESP_MIA" 2 "EPB_SUMMONFAULT_DAS_MIA" 1 "EPB_SUMMONFAULT_DI_MIA" 0 "EPB_SUMMONFAULT_NONE" ;
VAL_ 552 EPBR_localCdpState 2 "EPB_CDP_STATE_FAULT" 1 "EPB_CDP_STATE_VALID" 0 "EPB_CDP_STATE_UNKNOWN" ;
VAL_ 552 EPBR_chimeRequestLocal 4 "EPB_CHIME_REQUEST_ACTIVE_DECEL" 3 "EPB_CHIME_REQUEST_ABOUT_TO_ACTIVE_DECEL" 2 "EPB_CHIME_REQUEST_GPO" 1 "EPB_CHIME_REQUEST_GENERAL" 0 "EPB_CHIME_REQUEST_NONE" ;
VAL_ 552 EPBR_telltaleLocal 7 "EPB_TELLTALE_SNA" 4 "EPB_TELLTALE_LAMP_RED_FLASH" 3 "EPB_TELLTALE_LAMP_AMBER_ON" 2 "EPB_TELLTALE_LAMP_RED_ON" 1 "EPB_TELLTALE_LAMP_RED_PARKED" 0 "EPB_TELLTALE_LAMP_OFF" ;
VAL_ 552 EPBR_internalCDPRequest 1 "EPB_CDP_REQUESTED" 0 "EPB_CDP_NOT_REQUESTED" ;
VAL_ 552 EPBR_esmSpeedClass 4 "ESM_SPEED_CLASS_UNKNOWN" 3 "ESM_SPEED_CLASS_FAST" 2 "ESM_SPEED_CLASS_USER_APPLY_OK" 1 "ESM_SPEED_CLASS_SYSTEM_APPLY_OK" 0 "ESM_SPEED_CLASS_STOPPED" ;
VAL_ 552 EPBR_learnedEpbConfig 11 "EPB_CONFIG_CT_MANDO" 10 "EPB_CONFIG_MODEL3_ZF" 9 "EPB_CONFIG_MODELS_CERAMIC" 8 "EPB_CONFIG_MODELY_PERFORMANCE_V2" 7 "EPB_CONFIG_MODEL3_PERFORMANCE_V2" 6 "EPB_CONFIG_MODELX_BASE" 5 "EPB_CONFIG_MODELY_PERFORMANCE" 4 "EPB_CONFIG_MODELY_BASE" 3 "EPB_CONFIG_MODELS_BASE" 2 "EPB_CONFIG_MODEL3_PERFORMANCE" 1 "EPB_CONFIG_MODEL3_BASE" 0 "EPB_CONFIG_UNKNOWN" ;
VAL_ 744 EPBR_systemStatus 8 "EPB_VEHICLE_STATUS_MISMATCH" 7 "EPB_VEHICLE_STATUS_FAULT_SECURE" 6 "EPB_VEHICLE_STATUS_FAULT" 5 "EPB_VEHICLE_STATUS_RELEASING" 4 "EPB_VEHICLE_STATUS_PARKING" 3 "EPB_VEHICLE_STATUS_DYNAMIC" 2 "EPB_VEHICLE_STATUS_PARKED" 1 "EPB_VEHICLE_STATUS_RELEASED" 0 "EPB_VEHICLE_STATUS_UNKNOWN" ;
VAL_ 744 EPBR_freeRollModeStatus 2 "EPB_FREE_ROLL_MODE_ENABLED" 1 "EPB_FREE_ROLL_MODE_AVAILABLE" 0 "EPB_FREE_ROLL_MODE_UNAVAILABLE" ;
VAL_ 744 EPBR_chimeRequest 4 "EPB_CHIME_REQUEST_ACTIVE_DECEL" 3 "EPB_CHIME_REQUEST_ABOUT_TO_ACTIVE_DECEL" 2 "EPB_CHIME_REQUEST_GPO" 1 "EPB_CHIME_REQUEST_GENERAL" 0 "EPB_CHIME_REQUEST_NONE" ;
VAL_ 744 EPBR_telltale 7 "EPB_TELLTALE_SNA" 4 "EPB_TELLTALE_LAMP_RED_FLASH" 3 "EPB_TELLTALE_LAMP_AMBER_ON" 2 "EPB_TELLTALE_LAMP_RED_ON" 1 "EPB_TELLTALE_LAMP_RED_PARKED" 0 "EPB_TELLTALE_LAMP_OFF" ;
VAL_ 744 EPBR_cdpRequest 1 "EPB_CDP_REQUESTED" 0 "EPB_CDP_NOT_REQUESTED" ;
VAL_ 744 EPBR_uiParkAvailable 2 "EPB_AVAIL_REAPPLIED" 1 "EPB_AVAIL_AVAILABLE" 0 "EPB_AVAIL_NOT_AVAILABLE" ;
VAL_ 744 EPBR_brakeDiscWipeRequest 3 "EPB_BRAKEDISCWIPE_REQUEST_SNA" 2 "EPB_BRAKEDISCWIPE_REQUEST_STRONG" 1 "EPB_BRAKEDISCWIPE_REQUEST_LIGHT" 0 "EPB_BRAKEDISCWIPE_REQUEST_NONE" ;
VAL_ 744 EPBR_uiWinchModeLvStatus 3 "EPB_LV_OK" 2 "EPB_LV_BLOCKED_TIMER_RUNNING" 1 "EPB_LV_BLOCKED_INPUT_VOLTAGE_LOW" 0 "EPB_LV_BLOCKED_BATTERY" ;
VAL_ 744 EPBR_autonomyBehavior 2 "DRIVERLESS_NO_TAKEOVER" 1 "DRIVERLESS_TAKEOVER" 0 "DRIVER" ;
VAL_ 1322 FC_alertID 321 "a321_FCAlertPlaceholder" 313 "a313_GB_inputVoltageRailOv" 312 "a312_GB_evseLimitsTimeout" 311 "a311_GB_battParamsTimeout" 310 "a310_GB_unused" 309 "a309_GB_unused" 308 "a308_GB_evseConLockTimeout" 307 "a307_GB_fcContOpenTimeout" 306 "a306_GB_vehReadyDeasserted" 305 "a305_GB_posRecogTimeout" 304 "a304_GB_unused" 303 "a303_GB_negRecogTimeout" 302 "a302_GB_unused" 301 "a301_GB_unused" 300 "a300_GB_unused" 299 "a299_GB_evseReadyTimeout" 298 "a298_GB_bmsCtrCloseTimeout" 297 "a297_GB_unused" 296 "a296_GB_invalidPilotTransitio" 295 "a295_GB_pilotRationality" 294 "a294_GB_unused" 293 "a293_GB_proxRationality" 292 "a292_GB_vehConLockTimeout" 291 "a291_GB_vehDataTimeout" 290 "a290_GB_pilotAcceptTimeout" 289 "a289_GB_proxTimeout" 288 "a288_GB_evseAbnormalStopReq" 287 "a287_GB_vehConnUnlocked" 286 "a286_GB_evseConnUnlocked" 285 "a285_GB_proxDisconnected" 284 "a284_GB_pcbTempHiFoldBk" 283 "a283_GB_posTempHiFoldBk" 282 "a282_GB_negTempHiFoldBk" 281 "a281_GB_evseOutOfService" 280 "a280_GB_retryLimitExceeded" 279 "a279_GB_evseOverCurrent" 278 "a278_GB_timeoutCCS" 277 "a277_GB_posToPcbDeltaLo" 276 "a276_GB_negToPcbDeltaLo" 275 "a275_GB_posToPcbDeltaHi" 274 "a274_GB_negToPcbDeltaHi" 273 "a273_GB_negToPosDeltaLo" 272 "a272_GB_negToPosDeltaHi" 271 "a271_GB_timeoutCRO" 270 "a270_GB_timeoutCML" 269 "a269_GB_timeoutCRM" 268 "a268_GB_pcb_OT" 267 "a267_GB_posPin_OT" 266 "a266_GB_negPin_OT" 265 "a265_GB_bmsIncompatible" 264 "a264_GB_timeoutCHM" 263 "a263_GB_hwProxTrip" 262 "a262_GB_evseRxBufOvf" 261 "a261_GB_evseTxBufOvf" 260 "a260_GB_vehRxBufOvf" 259 "a259_GB_vehTxBufOvf" 258 "a258_GB_evseMia" 257 "a257_GB_bmsMia" 193 "a193_FCAlertPlaceholder" 187 "a187_CA_evseConLockTimeout" 186 "a186_CA_fcContOpenTimeout" 185 "a185_CA_vehReadyDeasserted" 184 "a184_CA_evseBatMalfunc" 183 "a183_CA_evseBatIncompat" 182 "a182_CA_evseChrMalfunc" 181 "a181_CA_vRegBrownout" 180 "a180_CA_chargingProblem" 179 "a179_CA_startupProblem" 178 "a178_CA_evseStartTimeout" 177 "a177_CA_bmsCtrCloseTimeout" 176 "a176_CA_chargingBusTimeout" 175 "a175_CA_evseIsoTestTimeout" 174 "a174_CA_vehReadyTimeout" 173 "a173_CA_evseDataTimeout" 172 "a172_CA_ss2LowTimeout" 171 "a171_CA_vehConLockTimeout" 170 "a170_CA_vehDataTimeout" 169 "a169_CA_pilotAcceptTimeout" 168 "a168_CA_proxTimeout" 167 "a167_CA_isoVoltageLow" 166 "a166_CA_vehConnUnlocked" 165 "a165_CA_evseConnUnlocked" 164 "a164_CA_proxDisconnected" 163 "a163_CA_pcbTempHiFoldBk" 162 "a162_CA_evseTempHiFoldBk" 161 "a161_CA_vehTempHiFoldBk" 160 "a160_CA_ss2Deasserted" 159 "a159_CA_wdtExpired" 158 "a158_CA_evseOverCurrent" 157 "a157_CA_unused" 156 "a156_CA_flybackRunTimeout" 155 "a155_CA_evseToPcbDeltaLo" 154 "a154_CA_vehToPcbDeltaLo" 153 "a153_CA_evseToPcbDeltaHi" 152 "a152_CA_vehToPcbDeltaHi" 151 "a151_CA_vehToEvseDeltaLo" 150 "a150_CA_vehToEvseDeltaHi" 149 "a149_CA_pcb_UT" 148 "a148_CA_evseConn_UT" 147 "a147_CA_vehConn_UT" 146 "a146_CA_flybackBusLoadHi" 145 "a145_CA_flybackDataStale" 144 "a144_CA_flybackUnstable" 143 "a143_CA_pcb_OT" 142 "a142_CA_evseConn_OT" 141 "a141_CA_vehConn_OT" 140 "a140_CA_bmsIncompatible" 139 "a139_CA_ss2NotLow" 138 "a138_CA_hwProxTrip" 137 "a137_CA_evseRxBufOvf" 136 "a136_CA_evseTxBufOvf" 135 "a135_CA_vehRxBufOvf" 134 "a134_CA_vehTxBufOvf" 133 "a133_CA_evseMia" 132 "a132_CA_bmsMia" 131 "a131_CA_flyback_HW_OV" 130 "a130_CA_flyback_SW_OV" 129 "a129_CA_flyback_HW_OC" 0 "ALERT_DO_NOT_USE_ZERO" ;
VAL_ 1322 FC_alertType 1 "FAULT" 0 "WARNING" ;
VAL_ 1117 FC_evseBillingDataSelect 1 "1" 0 "0" ;
VAL_ 1334 FC_evseBilling2DataSelect 0 "FC_EVSEBILLING2_DATASELECT_0" ;
VAL_ 1334 FC_evseBillingEnergyHighRes 16777215 "SNA" ;
VAL_ 1310 FC_infoIndex 255 "END_FC" 27 "PART_NUM_3" 26 "PART_NUM_2" 25 "PART_NUM_1" 22 "VARIANT_CRC_FC" 20 "UDS_PROTOCOL_BOOTCRC_FC" 19 "VERSION_DEPRECATED_FC" 18 "BOOTLOADER_GITHASH_FC" 17 "APP_GITHASH_FC" 16 "SUBCOMPONENT_FC" 15 "BOOTLOADER_CRC_FC" 14 "BOOTLOADER_SVN_FC" 13 "APP_CRC_FC" 11 "PCBAID_ASSYID_USAGEID_FC" 10 "BUILD_HWID_COMPONENTID_FC" 9 "DEPRECATED_9_FC" 8 "DEPRECATED_8_FC" 7 "DEPRECATED_7_FC" 6 "DEPRECATED_6_FC" 5 "DEPRECATED_5_FC" 4 "DEPRECATED_4_FC" 3 "DEPRECATED_3_FC" 2 "DEPRECATED_2_FC" 1 "DEPRECATED_1_FC" 0 "DEPRECATED_0_FC" ;
VAL_ 1310 FC_infoBuildType 4 "INFO_MFG_BUILD_FC" 3 "INFO_TRACEABLE_CI_BUILD_FC" 2 "INFO_LOCAL_BUILD_FC" 1 "INFO_PLATFORM_BUILD_FC" 0 "INFO_UNKNOWN_BUILD_FC" ;
VAL_ 580 FC_powerLimit 8191 "SNA" ;
VAL_ 580 FC_currentLimit 8191 "SNA" ;
VAL_ 580 FC_maxVoltageLimit 8191 "SNA" ;
VAL_ 580 FC_minVoltageLimit 8191 "SNA" ;
VAL_ 702 FC_powerLimit_value -32768 "SNA" ;
VAL_ 702 FC_currentLimit_value -32768 "SNA" ;
VAL_ 702 FC_minVoltageLimit_value -32768 "SNA" ;
VAL_ 1345 FC_maxPowerLimit 8191 "SNA" ;
VAL_ 1345 FC_maxCurrentLimit 8191 "SNA" ;
VAL_ 1300 FC_serialDataSelect 2 "Mux2" 1 "Mux1" 0 "Mux0" ;
VAL_ 532 FC_statusCode 15 "FC_STATUS_NODATA" 14 "FC_STATUS_MALFUNCTION" 13 "FC_STATUS_NOTCOMPATIBLE" 7 "FC_STATUS_POST_OUT_OF_SERVICE" 6 "FC_STATUS_EXT_ISOACTIVE" 5 "FC_STATUS_INT_ISOACTIVE" 4 "FC_STATUS_DEPRECATED_4" 3 "FC_STATUS_DEPRECATED_3" 2 "FC_STATUS_UPDATE_IN_PROGRESS" 1 "FC_STATUS_READY" 0 "FC_STATUS_NOTREADY_SNA" ;
VAL_ 532 FC_type 7 "FC_TYPE_SNA" 6 "FC_TYPE_OTHER" 5 "FC_TYPE_MC_EVSE" 4 "FC_TYPE_COMBO" 3 "FC_TYPE_CC_EVSE" 2 "FC_TYPE_GB" 1 "FC_TYPE_CHADEMO" 0 "FC_TYPE_SUPERCHARGER" ;
VAL_ 532 FC_postID 3 "FC_POST_ID_SNA" 2 "FC_POST_ID_2" 1 "FC_POST_SLAVE" 0 "FC_POST_MASTER" ;
VAL_ 533 FC_externalIsolationResistance 255 "SNA" ;
VAL_ 535 FC_status3DataSelect 1 "Mux1" 0 "Mux0" ;
VAL_ 535 FC_class 2 "FC_CLASS_URBANCHARGER" 1 "FC_CLASS_SUPERCHARGER" 0 "FC_CLASS_SNA" ;
VAL_ 535 FC_brand 1 "TESLA" 0 "SNA" ;
VAL_ 535 FC_coolingType 3 "FC_COOLING_TYPE_IMMERSION" 2 "FC_COOLING_TYPE_CONVECTION" 1 "FC_COOLING_TYPE_LIQUID" 0 "FC_COOLING_TYPE_SNA" ;
VAL_ 535 FC_uiStopType 2 "FC_UI_STOP_TYPE_MOMENTARY" 1 "FC_UI_STOP_TYPE_TOGGLE" 0 "FC_UI_STOP_TYPE_SNA" ;
VAL_ 535 FC_generation 0 "GENERATION_SNA" ;
VAL_ 1650 VC_hcmlInfoIndex 9 "END" 8 "ECULESS_MISC" 7 "ECULESS_BOOST" 6 "ECULESS_LED_VOLTAGES" 5 "ECULESS_IC700_SM" 4 "ECULESS_IC600_DRL_TURN" 3 "ECULESS_IC500_LB" 2 "ECULESS_IC400_HB" 1 "HCML_ASSEMBLY_PCBA_USAGE_ID" 0 "HCML_BUILD_CONFIG_ID_LMM_VARIANT" ;
VAL_ 1650 VC_leftHeadlampLMMVariant 2 "LMM_VARIANT_LMM4" 1 "LMM_VARIANT_NOT_LMM4_OR_UNKNOWN" 0 "LMM_VARIANT_SNA" ;
VAL_ 1980 VC_hcmrInfoIndex 9 "END" 8 "ECULESS_MISC" 7 "ECULESS_BOOST" 6 "ECULESS_LED_VOLTAGES" 5 "ECULESS_IC700_SM" 4 "ECULESS_IC600_DRL_TURN" 3 "ECULESS_IC500_LB" 2 "ECULESS_IC400_HB" 1 "HCMR_ASSEMBLY_PCBA_USAGE_ID" 0 "HCMR_BUILD_CONFIG_ID_LMM_VARIANT" ;
VAL_ 1980 VC_rightHeadlampLMMVariant 2 "LMM_VARIANT_LMM4" 1 "LMM_VARIANT_NOT_LMM4_OR_UNKNOWN" 0 "LMM_VARIANT_SNA" ;
VAL_ 1290 HVP_alertID 71 "a071_PassivePyroVrefRationality" 70 "a070_hvsCanFrameRxDropped" 69 "a069_hviCanFrameRxDropped" 68 "a068_shuntUnexpectedThermistor" 67 "a067_HvilCalNodeMismatch" 65 "a065_FastOpenVshDetected" 64 "a064_BmbAuxVRationality" 63 "a063_BmbBrickVRationality" 62 "a062_BmbOtpConfigError" 61 "a061_ShuntCurrentRationality" 60 "a060_StackVoltageSense" 59 "a059_BmbVrefWarning" 58 "a058_BmbVrefBad" 57 "a057_BatmanDiagnosticsError" 56 "a056_contactorFailedToOpen" 55 "a055_swMissingPartNumber" 54 "a054_swMissingConfigBlock" 53 "a053_hvVoltageSensorRationality" 52 "a052_BmbStatusRegError" 51 "a051_shuntThermistorMia" 50 "a050_fcCtrCloseFailed" 49 "a049_packCtrCloseFailed" 48 "a048_swUnsupportedBmbAsicType" 47 "a047_passivePyroDeploy" 46 "a046_shuntOverTemperature" 45 "a045_dcLinkOverVoltage" 44 "a044_fcContactorForceOpen" 43 "a043_packContactorForceOpen" 42 "a042_fcCtrCloseBlocked" 41 "a041_packCtrCloseBlocked" 40 "a040_FcContactorFellOpen" 39 "a039_PackContactorFellOpen" 38 "a038_CpilFault" 37 "a037_pyroFuseFailedToBlow" 36 "a036_pyroFuseBlown" 35 "a035_packContHwFault" 34 "a034_cpMismatchFault" 33 "a033_fcContHwFault" 32 "a032_ShuntHwAndBmsMiaFault" 31 "a031_packNegCtrArcFault" 30 "a030_PackPosCtrArcFault" 29 "a029_EnsMiaFault" 28 "a028_PackVoltMismatchFault" 27 "a027_BmsMiaOnHvsFault" 26 "a026_HvilFault" 25 "a025_VerSupplyFault" 24 "a024_Supply12vFault" 23 "a023_BmbResetRecovery" 22 "a022_PyroMiaWarning" 21 "a021_PyroMiaFault" 20 "a020_ShuntHwMiaFault" 19 "a019_CpFault" 18 "a018_powerCyclingPcs" 17 "a017_GtwMiaFault" 16 "a016_PcsMiaFault" 15 "a015_CpMiaFault" 14 "a014_BmsMiaOnHviFault" 13 "a013_BmbCommunication" 12 "a012_BmbDataIntegrityLoss" 11 "a011_PrimaryBmbMiaFault" 10 "a010_UnderVoltageFault" 9 "a009_OverVoltageFault" 8 "a008_OverTemperatureFault" 7 "a007_OverCurrentFault" 6 "a006_OverChargeCurrentFault" 5 "a005_OverDchgCurrentFault" 4 "a004_CrashEvent" 3 "a003_SwAssertion" 2 "a002_UnusedAlert2" 1 "a001_WatchdogReset" 0 "ALERT_DO_NOT_USE_ZERO" ;
VAL_ 1290 HVP_alertSet 1 "SET" 0 "CLEARED" ;
VAL_ 1290 HVP_a012_bmbCommStatusTypeA 3 "BYPASSED" 2 "NOMINAL" 1 "BAD" 0 "MISSING" ;
VAL_ 1290 HVP_a012_bmbCommStatusTypeB 3 "BYPASSED" 2 "NOMINAL" 1 "BAD" 0 "MISSING" ;
VAL_ 1290 HVP_a013_bmbCommStatusTypeA 3 "BYPASSED" 2 "NOMINAL" 1 "BAD" 0 "MISSING" ;
VAL_ 1290 HVP_a013_bmbCommStatusTypeB 3 "BYPASSED" 2 "NOMINAL" 1 "BAD" 0 "MISSING" ;
VAL_ 1290 HVP_a013_bmbChainBreakType 5 "TAIL_BREAK" 4 "HEAD_BREAK" 3 "INVALID_BREAK" 2 "DOUBLE_BREAK" 1 "SINGLE_BREAK" 0 "NONE" ;
VAL_ 1290 HVP_a020_energyReserveV 65535 "SNA" ;
VAL_ 1290 HVP_a020_shuntCurrentAux -32768 "SNA" ;
VAL_ 1290 HVP_a020_shuntTemperature -32768 "SNA" ;
VAL_ 1290 HVP_a021_pyroStatus 3 "ACTIVATED" 2 "FAULT" 1 "OK" 0 "UNKNOWN" ;
VAL_ 1290 HVP_a021_SquibResistance 65535 "SNA" ;
VAL_ 1290 HVP_a021_Aout 16383 "SNA" ;
VAL_ 1290 HVP_a022_pyroStatus 3 "ACTIVATED" 2 "FAULT" 1 "OK" 0 "UNKNOWN" ;
VAL_ 1290 HVP_a022_Aout 16383 "SNA" ;
VAL_ 1290 HVP_a022_SquibResistance 65535 "SNA" ;
VAL_ 1290 HVP_a026_hvilStatus 14 "SNA" 13 "PM_OPEN_FAULT" 12 "DI_OPEN_FAULT" 11 "PM_STATUS_MISSING_FAULT" 10 "DI_STATUS_MISSING_FAULT" 9 "VEHICLE_OR_PENTHOUSE_LID_OPEN_FAULT" 8 "NO_12V_SUPPLY" 7 "VEHICLE_NODE_FAULT" 6 "UNKNOWN_LOCATION_OPEN_FAULT" 5 "PENTHOUSE_LID_OPEN_FAULT" 4 "VEHICLE_OPEN_FAULT" 3 "INTERNAL_OPEN_FAULT" 2 "CURRENT_SOURCE_OR_GROUND_LEAK_FAULT" 1 "OK" 0 "UNKNOWN" ;
VAL_ 1290 HVP_a026_internalVoltage 255 "SNA" ;
VAL_ 1290 HVP_a026_dirVoltage 255 "SNA" ;
VAL_ 1290 HVP_a026_difVoltage 255 "SNA" ;
VAL_ 1290 HVP_a036_pyroFiringHandle 12 "PACK_NEGATIVE_CTR_ARC" 11 "PACK_POSITIVE_CTR_ARC" 10 "ENS_CRASH" 9 "SHUNT_MIA" 8 "OPEN_IMMEDIATELY" 7 "TEMPERATURE" 6 "UNDER_VOLTAGE" 5 "OVER_VOLTAGE" 4 "OVER_CURRENT" 3 "OVER_CHARGE_CURRENT" 2 "OVER_DISCHARGE_CURRENT" 1 "HVP" ;
VAL_ 1290 HVP_a037_pyroFiringHandle 12 "PACK_NEGATIVE_CTR_ARC" 11 "PACK_POSITIVE_CTR_ARC" 10 "ENS_CRASH" 9 "SHUNT_MIA" 8 "OPEN_IMMEDIATELY" 7 "TEMPERATURE" 6 "UNDER_VOLTAGE" 5 "OVER_VOLTAGE" 4 "OVER_CURRENT" 3 "OVER_CHARGE_CURRENT" 2 "OVER_DISCHARGE_CURRENT" 1 "HVP" ;
VAL_ 1290 HVP_a049_posCtrState 7 "WELDED" 6 "ECONOMIZED" 5 "OPENING" 4 "PULLED_IN" 3 "BLOCKED" 2 "PRECHARGE" 1 "OPEN" 0 "SNA" ;
VAL_ 1290 HVP_a049_negCtrState 7 "WELDED" 6 "ECONOMIZED" 5 "OPENING" 4 "PULLED_IN" 3 "BLOCKED" 2 "PRECHARGE" 1 "OPEN" 0 "SNA" ;
VAL_ 1290 HVP_a050_posCtrState 7 "WELDED" 6 "ECONOMIZED" 5 "OPENING" 4 "PULLED_IN" 3 "BLOCKED" 2 "PRECHARGE" 1 "OPEN" 0 "SNA" ;
VAL_ 1290 HVP_a050_negCtrState 7 "WELDED" 6 "ECONOMIZED" 5 "OPENING" 4 "PULLED_IN" 3 "BLOCKED" 2 "PRECHARGE" 1 "OPEN" 0 "SNA" ;
VAL_ 1290 HVP_a051_shuntTemperature -32768 "SNA" ;
VAL_ 1290 HVP_a051_shuntCurrent -32768 "SNA" ;
VAL_ 1290 HVP_a051_energyReserveV 65535 "SNA" ;
VAL_ 1290 HVP_a056_diagnosis 2 "PACK_CONTACTOR_WELDED" 1 "HIGH_SHUNT_CURRENT" 0 "SHUNT_CURRENT_SNA" ;
VAL_ 1290 HVP_a056_posPackContactorState 7 "WELDED" 6 "ECONOMIZED" 5 "OPENING" 4 "PULLED_IN" 3 "BLOCKED" 2 "PRECHARGE" 1 "OPEN" 0 "SNA" ;
VAL_ 1290 HVP_a056_negPackContactorState 7 "WELDED" 6 "ECONOMIZED" 5 "OPENING" 4 "PULLED_IN" 3 "BLOCKED" 2 "PRECHARGE" 1 "OPEN" 0 "SNA" ;
VAL_ 1290 HVP_a056_posFcContactorState 7 "WELDED" 6 "ECONOMIZED" 5 "OPENING" 4 "PULLED_IN" 3 "BLOCKED" 2 "PRECHARGE" 1 "OPEN" 0 "SNA" ;
VAL_ 1290 HVP_a056_negFcContactorState 7 "WELDED" 6 "ECONOMIZED" 5 "OPENING" 4 "PULLED_IN" 3 "BLOCKED" 2 "PRECHARGE" 1 "OPEN" 0 "SNA" ;
VAL_ 1290 HVP_a058_VrefStatus 3 "BYPASSED" 2 "NOMINAL" 1 "BAD" 0 "MISSING" ;
VAL_ 1290 HVP_a058_VrefType 2 "REF2" 1 "V3" 0 "V5" ;
VAL_ 1290 HVP_a067_hvilTypeFromHvp 2 "CAN" 1 "LV" 0 "UNKNOWN" ;
VAL_ 1290 HVP_a067_hvilTypeFromGateway 2 "CAN" 1 "LV" 0 "UNKNOWN" ;
VAL_ 1290 HVP_a068_shuntTemperature -32768 "SNA" ;
VAL_ 1290 HVP_a068_shuntCurrent -32768 "SNA" ;
VAL_ 1290 HVP_a068_energyReserveV 65535 "SNA" ;
VAL_ 938 HVP_matrixIndex 1 "AlertMatrix1" 0 "AlertMatrix0" ;
VAL_ 522 HVP_packContNegativeState 7 "CONTACTOR_STATE_WELDED" 6 "CONTACTOR_STATE_ECONOMIZED" 5 "CONTACTOR_STATE_OPENING" 4 "CONTACTOR_STATE_PULLED_IN" 3 "CONTACTOR_STATE_BLOCKED" 2 "CONTACTOR_STATE_PRECHARGE" 1 "CONTACTOR_STATE_OPEN" 0 "CONTACTOR_STATE_SNA" ;
VAL_ 522 HVP_packContPositiveState 7 "CONTACTOR_STATE_WELDED" 6 "CONTACTOR_STATE_ECONOMIZED" 5 "CONTACTOR_STATE_OPENING" 4 "CONTACTOR_STATE_PULLED_IN" 3 "CONTACTOR_STATE_BLOCKED" 2 "CONTACTOR_STATE_PRECHARGE" 1 "CONTACTOR_STATE_OPEN" 0 "CONTACTOR_STATE_SNA" ;
VAL_ 522 HVP_packContactorSetState 9 "CONTACTOR_SET_STATE_NEGATIVE_CLOSED" 8 "CONTACTOR_SET_STATE_POSITIVE_CLOSED" 7 "CONTACTOR_SET_STATE_WELDED" 6 "CONTACTOR_SET_STATE_PARTIAL_WELD" 5 "CONTACTOR_SET_STATE_CLOSED" 4 "CONTACTOR_SET_STATE_OPENING" 3 "CONTACTOR_SET_STATE_BLOCKED" 2 "CONTACTOR_SET_STATE_CLOSING" 1 "CONTACTOR_SET_STATE_OPEN" 0 "CONTACTOR_SET_STATE_SNA" ;
VAL_ 522 HVP_fcContNegativeState 7 "CONTACTOR_STATE_WELDED" 6 "CONTACTOR_STATE_ECONOMIZED" 5 "CONTACTOR_STATE_OPENING" 4 "CONTACTOR_STATE_PULLED_IN" 3 "CONTACTOR_STATE_BLOCKED" 2 "CONTACTOR_STATE_PRECHARGE" 1 "CONTACTOR_STATE_OPEN" 0 "CONTACTOR_STATE_SNA" ;
VAL_ 522 HVP_fcContPositiveState 7 "CONTACTOR_STATE_WELDED" 6 "CONTACTOR_STATE_ECONOMIZED" 5 "CONTACTOR_STATE_OPENING" 4 "CONTACTOR_STATE_PULLED_IN" 3 "CONTACTOR_STATE_BLOCKED" 2 "CONTACTOR_STATE_PRECHARGE" 1 "CONTACTOR_STATE_OPEN" 0 "CONTACTOR_STATE_SNA" ;
VAL_ 522 HVP_fcContactorSetState 9 "CONTACTOR_SET_STATE_NEGATIVE_CLOSED" 8 "CONTACTOR_SET_STATE_POSITIVE_CLOSED" 7 "CONTACTOR_SET_STATE_WELDED" 6 "CONTACTOR_SET_STATE_PARTIAL_WELD" 5 "CONTACTOR_SET_STATE_CLOSED" 4 "CONTACTOR_SET_STATE_OPENING" 3 "CONTACTOR_SET_STATE_BLOCKED" 2 "CONTACTOR_SET_STATE_CLOSING" 1 "CONTACTOR_SET_STATE_OPEN" 0 "CONTACTOR_SET_STATE_SNA" ;
VAL_ 522 HVP_fcCtrsRequestStatus 2 "REQUEST_COMPLETED" 1 "REQUEST_ACTIVE" 0 "REQUEST_NOT_ACTIVE" ;
VAL_ 522 HVP_packCtrsRequestStatus 2 "REQUEST_COMPLETED" 1 "REQUEST_ACTIVE" 0 "REQUEST_NOT_ACTIVE" ;
VAL_ 522 HVP_hvilDiag 14 "SNA" 13 "PM_OPEN_FAULT" 12 "DI_OPEN_FAULT" 11 "PM_STATUS_MISSING_FAULT" 10 "DI_STATUS_MISSING_FAULT" 9 "VEHICLE_OR_PENTHOUSE_LID_OPEN_FAULT" 8 "NO_12V_SUPPLY" 7 "VEHICLE_NODE_FAULT" 6 "UNKNOWN_LOCATION_OPEN_FAULT" 5 "PENTHOUSE_LID_OPEN_FAULT" 4 "VEHICLE_OPEN_FAULT" 3 "INTERNAL_OPEN_FAULT" 2 "CURRENT_SOURCE_OR_GROUND_LEAK_FAULT" 1 "OK" 0 "UNKNOWN" ;
VAL_ 522 HVP_fcLinkAllowedToEnergize 2 "FC_LINK_ENERGY_DC" 1 "FC_LINK_ENERGY_AC" 0 "FC_LINK_ENERGY_NONE" ;
VAL_ 1962 HVP_debugMessageMultiplexer 12 "Mux12" 11 "Mux11" 10 "Mux10" 9 "Mux9" 8 "Mux8" 7 "Mux7" 6 "Mux6" 5 "Mux5" 4 "Mux4" 3 "Mux3" 2 "Mux2" 1 "Mux1" 0 "Mux0" ;
VAL_ 1962 HVP_ecuLogUploadRequest 3 "REQUEST_PRIORITY_3" 2 "REQUEST_PRIORITY_2" 1 "REQUEST_PRIORITY_1" 0 "REQUEST_PRIORITY_NONE" ;
VAL_ 1962 HVP_passivePyroRefVoltageMax 1023 "SNA" ;
VAL_ 1962 HVP_passivePyroRefVoltageMin 1023 "SNA" ;
VAL_ 554 HVP_pcsControlRequest 3 "DISCHARGE" 2 "PRECHARGE" 1 "SUPPORT" 0 "SHUTDOWN" ;
VAL_ 554 HVP_dcLinkVoltageFiltered -550 "SNA" ;
VAL_ 784 HVP_infoIndex 255 "END" 31 "SUBCOMPONENT_GITHASH" 30 "PACKAGE_SN_8_14" 29 "PACKAGE_SN_1_7" 27 "PACKAGE_PN_15_20" 26 "PACKAGE_PN_8_14" 25 "PACKAGE_PN_1_7" 23 "SUBCOMPONENT2" 22 "VARIANTCRC" 20 "UDS_PROTOCOL_BOOTCRC" 19 "VERSION_DEPRECATED" 18 "BOOTLOADER_GITHASH" 17 "APP_GITHASH" 16 "SUBCOMPONENT" 15 "BOOTLOADER_CRC" 14 "BOOTLOADER_SVN" 13 "APP_CRC" 11 "PCBAID_ASSYID_USAGEID" 10 "BUILD_HWID_COMPONENTID" 9 "DEPRECATED_9" 8 "DEPRECATED_8" 7 "DEPRECATED_7" 6 "DEPRECATED_6" 5 "DEPRECATED_5" 4 "DEPRECATED_4" 3 "DEPRECATED_3" 2 "DEPRECATED_2" 1 "DEPRECATED_1" 0 "DEPRECATED_0" ;
VAL_ 784 HVP_buildType 4 "INFO_MFG_BUILD" 3 "INFO_TRACEABLE_CI_BUILD" 2 "INFO_LOCAL_BUILD" 1 "INFO_PLATFORM_BUILD" 0 "INFO_UNKNOWN_BUILD" ;
